VERSION ""

NS_ :

BS_:

BU_: BDCF THU FP IP RRS PLG BDCR FIS EPS ARHUD ETC EMS EPBI LAS WLCM ESCL HU APA ACC LCDAL LCDAR BMT AMP SRS TCU ATB AWD ESL ACM ECM PCU BMS IBCU OTA

BO_ 1476 BDCF_5C4: 8 BDCF
 SG_ Digital_certificate_response : 7|64@0+ (1,0) [0|1] ""  THU

BO_ 1494 BDCF_5D6: 8 BDCF
 SG_ Digital_certificate_request : 7|64@0+ (1,0) [0|1] ""  THU

BO_ 1320 BDCF_528: 8 BDCF
 SG_ group_number : 7|8@0+ (1,0) [0|1] ""  THU,IP,FIS
 SG_ RemoteParking_payment_activation_status : 15|2@0+ (1,0) [0|3] ""  THU,IP
 SG_ controller_number : 39|8@0+ (1,0) [0|255] "" Vector__XXX

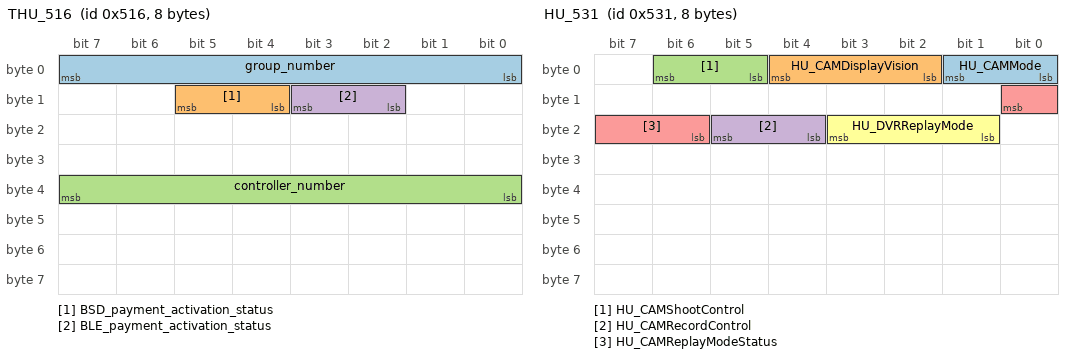
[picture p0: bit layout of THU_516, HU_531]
BO_ 1302 THU_516: 8 THU
 SG_ group_number : 7|8@0+ (1,0) [0|255] ""  BDCF,IP
 SG_ BSD_payment_activation_status : 13|2@0+ (1,0) [0|3] ""  BDCF,IP
 SG_ controller_number : 39|8@0+ (1,0) [0|255] ""  BDCF
 SG_ BLE_payment_activation_status : 11|2@0+ (1,0) [0|3] ""  BDCF

BO_ 1383 BDCF_567: 8 BDCF
 SG_ group_number : 7|8@0+ (1,0) [0|255] ""  THU
 SG_ BSD_payment_activation : 10|1@0+ (1,0) [0|1] ""  THU
 SG_ RemoteParking_payment_activation : 11|1@0+ (1,0) [0|1] ""  THU
 SG_ FV : 39|8@0+ (1,0) [0|255] ""  THU
 SG_ MAC : 47|24@0+ (1,0) [0|16777215] ""  THU
 SG_ BLE_payment_activation : 9|1@0+ (1,0) [0|1] ""  THU

BO_ 1329 HU_531: 8 THU
 SG_ HU_CAMMode : 1|2@0+ (1,0) [0|1] ""  BDCF
 SG_ HU_CAMDisplayVision : 4|3@0+ (1,0) [0|7] ""  BDCF
 SG_ HU_CAMShootControl : 6|2@0+ (1,0) [0|3] ""  BDCF
 SG_ HU_CAMRecordControl : 21|2@0+ (1,0) [0|3] ""  BDCF
 SG_ HU_CAMReplayModeStatus : 8|3@0+ (1,0) [0|7] ""  BDCF
 SG_ HU_DVRReplayMode : 19|3@0+ (1,0) [0|7] ""  BDCF

BO_ 1034 BDCR_40A: 8 BDCR
 SG_ BDCR_NMDestinationAddress : 7|8@0+ (1,0) [0|255] ""  BDCF,THU,HU,IP,FIS,BMT,PLG
 SG_ BDCR_NMAlive : 8|1@0+ (1,0) [0|1] ""  BDCF,THU,HU,IP,FIS,BMT,PLG
 SG_ BDCR_NMRing : 9|1@0+ (1,0) [0|1] ""  BDCF,THU,HU,IP,FIS,BMT,PLG
 SG_ BDCR_NMLimphome : 10|1@0+ (1,0) [0|1] ""  BDCF,THU,HU,IP,FIS,BMT,PLG
 SG_ BDCR_NMSleepIndication : 12|1@0+ (1,0) [0|1] ""  BDCF,THU,HU,IP,FIS,BMT,PLG
 SG_ BDCR_NMSleepAcknowledge : 13|1@0+ (1,0) [0|1] ""  BDCF,THU,HU,IP,FIS,BMT,PLG
 SG_ BDCR_PowerDistributionStatus : 16|1@0+ (1,0) [0|1] ""  BDCF,THU,HU,IP,FIS,BMT,PLG
 SG_ BDCR_BusMessageWakeUp : 17|1@0+ (1,0) [0|1] ""  BDCF,THU,HU,IP,FIS,BMT,PLG
 SG_ BDCR_BusMessageWakeUpMold : 20|3@0+ (1,0) [0|7] ""  BDCF,THU,HU,IP,FIS,BMT,PLG
 SG_ BDCR_PowerStatus : 21|1@0+ (1,0) [0|1] ""  BDCF,THU,HU,IP,FIS,BMT,PLG
 SG_ BDCR_CanBusStatus : 22|1@0+ (1,0) [0|1] ""  BDCF,THU,HU,IP,FIS,BMT,PLG
 SG_ BDCR_KeyRemoteOpenPTSWakeUp : 23|1@0+ (1,0) [0|1] ""  BDCF,THU,HU,IP,FIS,BMT,PLG
 SG_ BDCR_PTSSwitchWakeUp : 24|1@0+ (1,0) [0|1] ""  BDCF,THU,HU,IP,FIS,BMT,PLG
 SG_ BDCR_KickWakeUp : 25|1@0+ (1,0) [0|1] ""  BDCF,THU,HU,IP,FIS,BMT,PLG
 SG_ BDCR_KeyRemoteOpenSCMWakeUp : 26|1@0+ (1,0) [0|1] ""  BDCF,THU,HU,IP,FIS,BMT,PLG
 SG_ BDCR_SCMSwitchWakeUp : 27|1@0+ (1,0) [0|1] ""  BDCF,THU,HU,IP,FIS,BMT,PLG
 SG_ BDCR_PTSStillOver10MinStatus : 28|1@0+ (1,0) [0|1] ""  BDCF,THU,HU,IP,FIS,BMT,PLG
 SG_ BDC2_WakeUpSource : 35|4@0+ (1,0) [0|15] ""  BDCF,THU,HU,IP,FIS,BMT,PLG

BO_ 1041 THU_411: 8 THU
 SG_ HU_NMDestinationAddress : 7|8@0+ (1,0) [0|255] ""  BDCF,ARHUD
 SG_ HU_NMAlive : 8|1@0+ (1,0) [0|1] ""  BDCF,ARHUD
 SG_ HU_NMRing : 9|1@0+ (1,0) [0|1] ""  BDCF,ARHUD
 SG_ HU_NMLimphome : 10|1@0+ (1,0) [0|1] ""  BDCF,ARHUD
 SG_ HU_NMSleepIndication : 12|1@0+ (1,0) [0|1] ""  BDCF,ARHUD
 SG_ HU_NMSleepAcknowledge : 13|1@0+ (1,0) [0|1] ""  BDCF,ARHUD
 SG_ HU_PowerDistributionStatus : 16|1@0+ (1,0) [0|1] ""  BDCF,ARHUD
 SG_ HU_BusMessageWakeUp : 17|1@0+ (1,0) [0|1] ""  BDCF,ARHUD
 SG_ HU_BusMessageWakeUpMold : 20|3@0+ (1,0) [0|7] ""  BDCF,ARHUD
 SG_ HU_Chip : 21|1@0+ (1,0) [0|1] ""  BDCF,ARHUD
 SG_ HU_TBOX_ECALLRequestSwitch : 22|1@0+ (1,0) [0|1] ""  BDCF,ARHUD
 SG_ HU_TBOX_RemoteWakeup : 23|1@0+ (1,0) [0|1] ""  BDCF,ARHUD
 SG_ HU_PowerStatus : 24|1@0+ (1,0) [0|1] ""  BDCF,ARHUD
 SG_ HU_RemoteLocksignal : 25|1@0+ (1,0) [0|1] ""  BDCF,ARHUD
 SG_ HU_PowerDown10Min : 26|1@0+ (1,0) [0|1] ""  BDCF,ARHUD
 SG_ HU_CanBusStatus : 27|1@0+ (1,0) [0|1] ""  BDCF,ARHUD
 SG_ NM_Segment : 28|1@0+ (1,0) [0|1] ""  BDCF,ARHUD
 SG_ HU_G_sensorWakeup : 29|1@0+ (1,0) [0|1] ""  BDCF,ARHUD

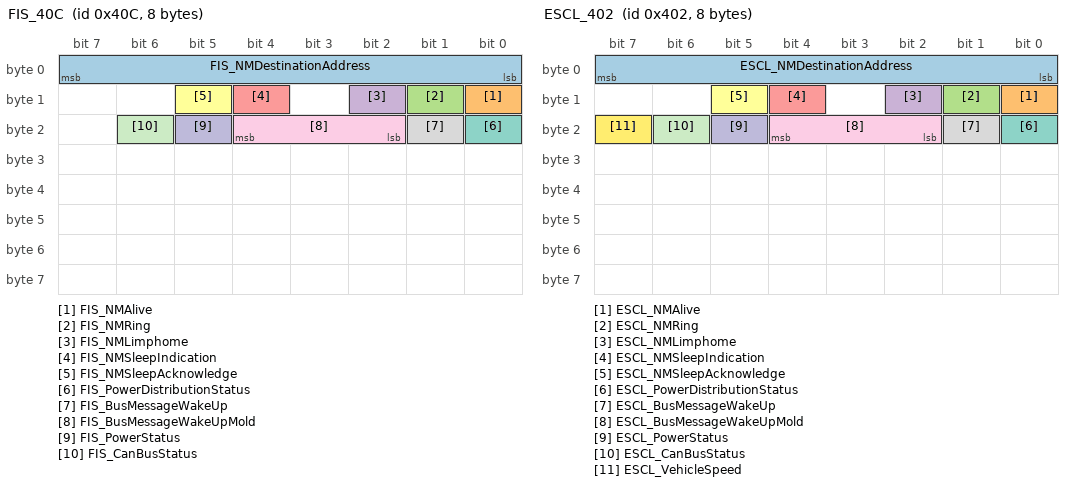
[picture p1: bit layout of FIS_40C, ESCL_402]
BO_ 1036 FIS_40C: 8 FIS
 SG_ FIS_NMDestinationAddress : 7|8@0+ (1,0) [0|255] ""  BDCF,THU,ARHUD
 SG_ FIS_NMAlive : 8|1@0+ (1,0) [0|1] ""  BDCF,THU,ARHUD
 SG_ FIS_NMRing : 9|1@0+ (1,0) [0|1] ""  BDCF,THU,ARHUD
 SG_ FIS_NMLimphome : 10|1@0+ (1,0) [0|1] ""  BDCF,THU,ARHUD
 SG_ FIS_NMSleepIndication : 12|1@0+ (1,0) [0|1] ""  BDCF,THU,ARHUD
 SG_ FIS_NMSleepAcknowledge : 13|1@0+ (1,0) [0|1] ""  BDCF,THU,ARHUD
 SG_ FIS_PowerDistributionStatus : 16|1@0+ (1,0) [0|1] ""  BDCF,THU,ARHUD
 SG_ FIS_BusMessageWakeUp : 17|1@0+ (1,0) [0|1] ""  BDCF,THU,ARHUD
 SG_ FIS_BusMessageWakeUpMold : 20|3@0+ (1,0) [0|7] ""  BDCF,THU,ARHUD
 SG_ FIS_PowerStatus : 21|1@0+ (1,0) [0|1] ""  BDCF,THU,ARHUD
 SG_ FIS_CanBusStatus : 22|1@0+ (1,0) [0|1] ""  BDCF,THU,ARHUD

BO_ 1026 ESCL_402: 8 ESCL
 SG_ ESCL_NMDestinationAddress : 7|8@0+ (1,0) [0|255] ""  BDCF,THU,ARHUD
 SG_ ESCL_NMAlive : 8|1@0+ (1,0) [0|1] ""  BDCF,THU,ARHUD
 SG_ ESCL_NMRing : 9|1@0+ (1,0) [0|1] ""  BDCF,THU,ARHUD
 SG_ ESCL_NMLimphome : 10|1@0+ (1,0) [0|1] ""  BDCF,THU,ARHUD
 SG_ ESCL_NMSleepIndication : 12|1@0+ (1,0) [0|1] ""  BDCF,THU,ARHUD
 SG_ ESCL_NMSleepAcknowledge : 13|1@0+ (1,0) [0|1] ""  BDCF,THU,ARHUD
 SG_ ESCL_PowerDistributionStatus : 16|1@0+ (1,0) [0|1] ""  BDCF,THU,ARHUD
 SG_ ESCL_BusMessageWakeUp : 17|1@0+ (1,0) [0|1] ""  BDCF,THU,ARHUD
 SG_ ESCL_BusMessageWakeUpMold : 20|3@0+ (1,0) [0|7] ""  BDCF,THU,ARHUD
 SG_ ESCL_PowerStatus : 21|1@0+ (1,0) [0|1] ""  BDCF,THU,ARHUD
 SG_ ESCL_CanBusStatus : 22|1@0+ (1,0) [0|1] ""  BDCF,THU,ARHUD
 SG_ ESCL_VehicleSpeed : 23|1@0+ (1,0) [0|1] ""  BDCF,THU,ARHUD

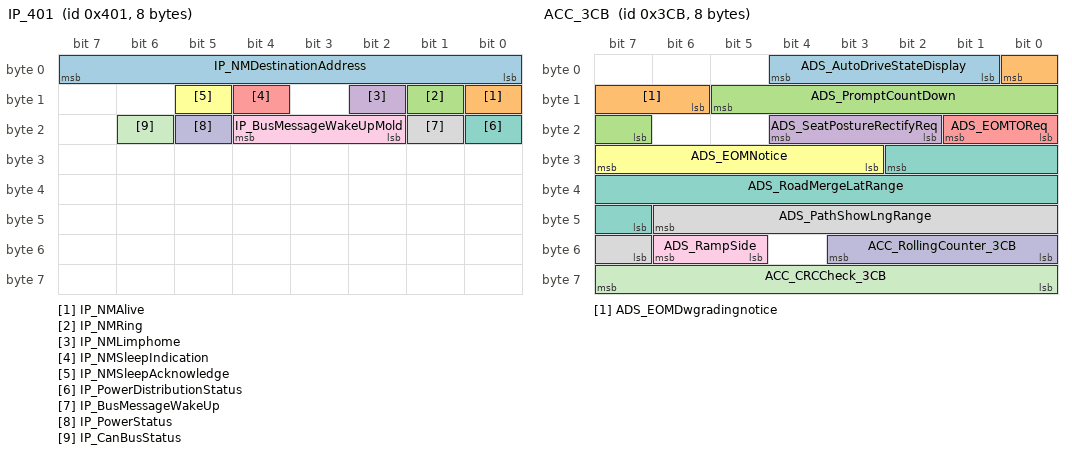
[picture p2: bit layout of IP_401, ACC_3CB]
BO_ 1025 IP_401: 8 IP
 SG_ IP_NMDestinationAddress : 7|8@0+ (1,0) [0|255] ""  BDCF,THU,ARHUD
 SG_ IP_NMAlive : 8|1@0+ (1,0) [0|1] ""  BDCF,THU,ARHUD
 SG_ IP_NMRing : 9|1@0+ (1,0) [0|1] ""  BDCF,THU,ARHUD
 SG_ IP_NMLimphome : 10|1@0+ (1,0) [0|1] ""  BDCF,THU,ARHUD
 SG_ IP_NMSleepIndication : 12|1@0+ (1,0) [0|1] ""  BDCF,THU,ARHUD
 SG_ IP_NMSleepAcknowledge : 13|1@0+ (1,0) [0|1] ""  BDCF,THU,ARHUD
 SG_ IP_PowerDistributionStatus : 16|1@0+ (1,0) [0|1] ""  BDCF,THU,ARHUD
 SG_ IP_BusMessageWakeUp : 17|1@0+ (1,0) [0|1] ""  BDCF,THU,ARHUD
 SG_ IP_BusMessageWakeUpMold : 20|3@0+ (1,0) [0|7] ""  BDCF,THU,ARHUD
 SG_ IP_PowerStatus : 21|1@0+ (1,0) [0|1] ""  BDCF,THU,ARHUD
 SG_ IP_CanBusStatus : 22|1@0+ (1,0) [0|1] ""  BDCF,THU,ARHUD

BO_ 1024 BDCF_400: 8 BDCF
 SG_ BDCF_NMDestinationAddress : 7|8@0+ (1,0) [0|255] ""  THU,ARHUD
 SG_ BDCF_NMAlive : 8|1@0+ (1,0) [0|1] ""  THU,ARHUD
 SG_ BDCF_NMRing : 9|1@0+ (1,0) [0|1] ""  THU,ARHUD
 SG_ BDCF_NMLimphome : 10|1@0+ (1,0) [0|1] ""  THU,ARHUD
 SG_ BDCF_NMSleepIndication : 12|1@0+ (1,0) [0|1] ""  THU,ARHUD
 SG_ BDCF_NMSleepAcknowledge : 13|1@0+ (1,0) [0|1] ""  THU,ARHUD
 SG_ BDCF_PowerDistributionStatus : 16|1@0+ (1,0) [0|1] ""  THU,ARHUD
 SG_ BDCF_BusMessageWakeUpMold : 20|4@0+ (1,0) [0|15] ""  THU,ARHUD
 SG_ BDCF_PositionLampSwitchWakeUp : 21|1@0+ (1,0) [0|1] ""  THU,ARHUD
 SG_ BDCF_EmergencyLightSwitchWakeUp : 22|1@0+ (1,0) [0|1] ""  THU,ARHUD
 SG_ BDCF_HoodStatusWakeUp : 23|1@0+ (1,0) [0|1] ""  THU,ARHUD
 SG_ BDCF_TrunkStatusWakeUp : 24|1@0+ (1,0) [0|1] ""  THU,ARHUD
 SG_ BDCF_RightRearDoorStatusWakeUp : 25|1@0+ (1,0) [0|1] ""  THU,ARHUD
 SG_ BDCF_LeftRearDoorStatusWakeUp : 26|1@0+ (1,0) [0|1] ""  THU,ARHUD
 SG_ BDCF_PassengerDoorStatusWakeUp : 27|1@0+ (1,0) [0|1] ""  THU,ARHUD
 SG_ BDCF_DriverDoorStatusWakeUp : 28|1@0+ (1,0) [0|1] ""  THU,ARHUD
 SG_ BDCF_CentralUnlockorLockControlS : 29|1@0+ (1,0) [0|1] ""  THU,ARHUD
 SG_ BDCF_DriverDoorUnlockorLockStatu : 30|1@0+ (1,0) [0|1] ""  THU,ARHUD
 SG_ BDCF_KeyRemoteSignalWakeUp : 34|3@0+ (1,0) [0|7] ""  THU,ARHUD
 SG_ BDCF_TrunkSwitchCommandWakeUp : 35|1@0+ (1,0) [0|1] ""  THU,ARHUD
 SG_ BDCF_Easy_openWakeUp : 36|1@0+ (1,0) [0|1] ""  THU,ARHUD
 SG_ BDCF_OverTakeLightSwitchWakeUp : 37|1@0+ (1,0) [0|1] ""  THU,ARHUD
 SG_ BDCF_StartupButtonSignalWakeUp : 38|1@0+ (1,0) [0|1] ""  THU,ARHUD
 SG_ BDCF_DoorHandleButtonSignalWakeU : 39|1@0+ (1,0) [0|1] ""  THU,ARHUD
 SG_ BDCF_BrakePedalWakeUp : 40|1@0+ (1,0) [0|1] ""  THU,ARHUD
 SG_ BDCF_GreetWakeUp : 41|1@0+ (1,0) [0|1] ""  THU,ARHUD
 SG_ BDCF_PowerStatus : 42|1@0+ (1,0) [0|1] ""  THU,ARHUD,ETC
 SG_ BDCF_PositionLampStatus : 43|1@0+ (1,0) [0|1] ""  THU,ARHUD
 SG_ BDCF_SecondAntiTheftStatus : 44|1@0+ (1,0) [0|1] ""  THU,ARHUD
 SG_ BDCF_ALLDoorStatus : 45|1@0+ (1,0) [0|1] ""  THU,ARHUD
 SG_ BDCF_DriverDoorHandleButtonStatu : 46|1@0+ (1,0) [0|1] ""  THU,ARHUD
 SG_ BDCF_TrunkButtonStatus : 47|1@0+ (1,0) [0|1] ""  THU,ARHUD
 SG_ BDCF_FollowMeHomeStatus : 48|1@0+ (1,0) [0|1] ""  THU,ARHUD
 SG_ BDCF_CanBusStatus : 49|1@0+ (1,0) [0|1] ""  THU,ARHUD
 SG_ BDCF_LinBusStatus : 50|1@0+ (1,0) [0|1] ""  THU,ARHUD
 SG_ BDCF_TurnLightSwitchStatus : 51|1@0+ (1,0) [0|1] ""  THU,ARHUD
 SG_ BDCF_UnlockPerformStatus : 52|1@0+ (1,0) [0|1] ""  THU,ARHUD
 SG_ BDCF_lockPerformStatus : 53|1@0+ (1,0) [0|1] ""  THU,ARHUD
 SG_ BDCF_PowerSaveModeStatus : 54|1@0+ (1,0) [0|1] ""  THU,ARHUD
 SG_ BDCF_BrakePedalStatus : 55|1@0+ (1,0) [0|1] ""  THU,ARHUD
 SG_ BDCF_RemoteSignalStatus : 56|1@0+ (1,0) [0|1] ""  THU,ARHUD
 SG_ BDCF_DSMLocalSwitchWakeUp : 57|1@0+ (1,0) [0|1] ""  THU,ARHUD
 SG_ BDCF_DSMSleepStatus : 58|1@0+ (1,0) [0|1] ""  THU,ARHUD

BO_ 973 ACC_3CD: 8 ACC
 SG_ ADS_DisToRamp : 7|9@0+ (1,0) [0|400] "m" BDCF,THU
 SG_ ADS_PathThroughRamp : 14|2@0+ (1,0) [0|3] "" THU
 SG_ ADS_RampStatus : 12|3@0+ (1,0) [0|3] "" THU
 SG_ ADS_TunnelStatus : 9|2@0+ (1,0) [0|3] "" THU
 SG_ ADS_TunnelDis : 23|9@0+ (1,0) [0|400] "m" THU
 SG_ ACC_RollingCounter_3CD : 51|4@0+ (1,0) [0|15] "" THU
 SG_ ACC_CRCCheck_3CD : 63|8@0+ (1,0) [0|255] "" THU

BO_ 971 ACC_3CB: 8 ACC
 SG_ ADS_AutoDriveStateDisplay : 4|4@0+ (1,0) [0|15] "" BDCF,THU
 SG_ ADS_EOMDwgradingnotice : 0|3@0+ (1,0) [0|7] "" THU
 SG_ ADS_PromptCountDown : 13|7@0+ (1,0) [0|100] "s" THU
 SG_ ADS_SeatPostureRectifyReq : 20|3@0+ (1,0) [0|7] "" THU
 SG_ ADS_EOMTOReq : 17|2@0+ (1,0) [0|3] "" THU
 SG_ ADS_EOMNotice : 31|5@0+ (1,0) [0|31] "" THU
 SG_ ADS_RoadMergeLatRange : 26|12@0+ (0.01,-16) [-16|16] "m" THU
 SG_ ADS_PathShowLngRange : 46|8@0+ (1,0) [0|200] "m" THU
 SG_ ADS_RampSide : 54|2@0+ (1,0) [0|3] "" THU
 SG_ ACC_RollingCounter_3CB : 51|4@0+ (1,0) [0|15] "" THU
 SG_ ACC_CRCCheck_3CB : 63|8@0+ (1,0) [0|255] "" THU

BO_ 970 ACC_3CA: 8 ACC
 SG_ ADS_RoadSlopeShapeC3 : 7|12@0+ (0.000000476837158203125,-0.000976085662841796875) [-0.000976085662841796875|0.000976085662841796875] "" BDCF,THU
 SG_ ADS_PathShow_C1 : 11|12@0+ (0.00048828125,-1) [-1|0.9990234375] "" THU
 SG_ ADS_PathShow_C2 : 31|12@0+ (0.0000152587890625,-0.0312347412109375) [-0.0312347412109375|0.0312347412109375] "" THU
 SG_ ADS_PathShow_C3 : 35|12@0+ (0.000000476837158203125,-0.000976085662841796875) [-0.000976085662841796875|0.000976085662841796875] "" THU
 SG_ ADS_PathShow_Status : 55|3@0+ (1,0) [0|7] "" THU
 SG_ ACC_RollingCounter_3CA : 51|4@0+ (1,0) [0|15] "" THU
 SG_ ACC_CRCCheck_3CA : 63|8@0+ (1,0) [0|255] "" THU

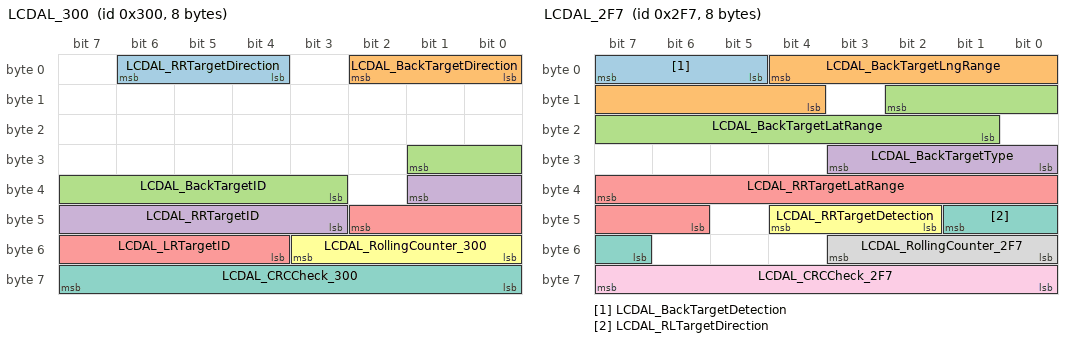
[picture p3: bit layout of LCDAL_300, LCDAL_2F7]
BO_ 768 LCDAL_300: 8 LCDAL
 SG_ LCDAL_RRTargetDirection : 6|3@0+ (1,0) [0|7] "" BDCF,THU,IP
 SG_ LCDAL_BackTargetDirection : 2|3@0+ (1,0) [0|7] "" THU,IP
 SG_ LCDAL_BackTargetID : 25|7@0+ (1,0) [0|63] "" THU,IP
 SG_ LCDAL_RRTargetID : 33|7@0+ (1,0) [0|63] "" THU,IP
 SG_ LCDAL_LRTargetID : 42|7@0+ (1,0) [0|63] "" THU,IP
 SG_ LCDAL_RollingCounter_300 : 51|4@0+ (1,0) [0|15] "" THU,IP
 SG_ LCDAL_CRCCheck_300 : 63|8@0+ (1,0) [0|255] "" THU,IP

BO_ 759 LCDAL_2F7: 8 LCDAL
 SG_ LCDAL_BackTargetDetection : 7|3@0+ (1,0) [0|7] "" BDCF,THU,IP
 SG_ LCDAL_BackTargetLngRange : 4|9@0+ (0.5,-70) [-70|180] "m" THU,IP
 SG_ LCDAL_BackTargetLatRange : 10|10@0+ (0.1,-50) [-50|50] "m" THU,IP
 SG_ LCDAL_BackTargetType : 27|4@0+ (1,0) [0|15] "" THU,IP
 SG_ LCDAL_RRTargetLatRange : 39|10@0+ (0.1,-50) [-50|50] "m" THU,IP
 SG_ LCDAL_RRTargetDetection : 44|3@0+ (1,0) [0|7] "" THU,IP
 SG_ LCDAL_RLTargetDirection : 41|3@0+ (1,0) [0|7] "" THU,IP
 SG_ LCDAL_RollingCounter_2F7 : 51|4@0+ (1,0) [0|15] "" THU,IP
 SG_ LCDAL_CRCCheck_2F7 : 63|8@0+ (1,0) [0|255] "" THU,IP

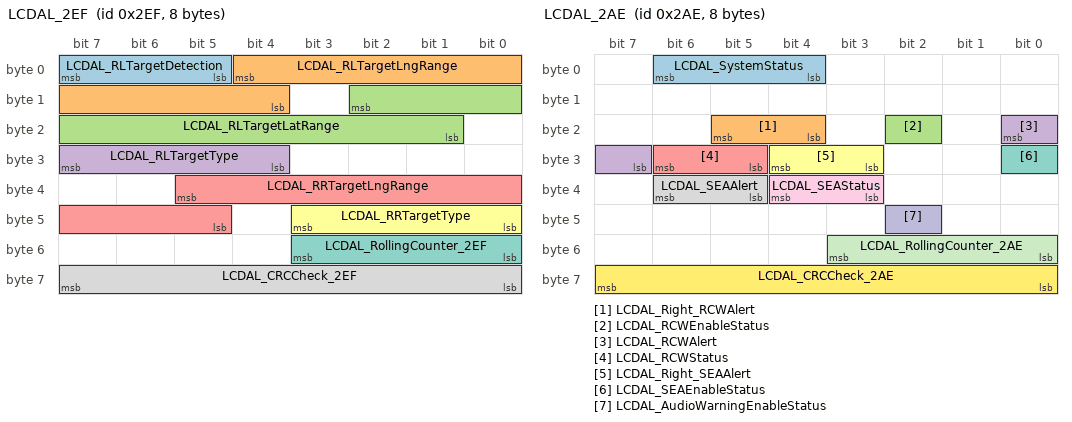
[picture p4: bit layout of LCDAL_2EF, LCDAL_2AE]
BO_ 751 LCDAL_2EF: 8 LCDAL
 SG_ LCDAL_RLTargetDetection : 7|3@0+ (1,0) [0|7] "" BDCF,THU,IP
 SG_ LCDAL_RLTargetLngRange : 4|9@0+ (0.5,-70) [-70|180] "m" THU,IP
 SG_ LCDAL_RLTargetLatRange : 10|10@0+ (0.1,-50) [-50|50] "m" THU,IP
 SG_ LCDAL_RLTargetType : 31|4@0+ (1,0) [0|15] "" THU,IP
 SG_ LCDAL_RRTargetLngRange : 37|9@0+ (0.5,-70) [-70|180] "m" THU,IP
 SG_ LCDAL_RRTargetType : 43|4@0+ (1,0) [0|15] "" THU,IP
 SG_ LCDAL_RollingCounter_2EF : 51|4@0+ (1,0) [0|15] "" THU,IP
 SG_ LCDAL_CRCCheck_2EF : 63|8@0+ (1,0) [0|255] "" THU,IP

BO_ 687 LCDAR_2AF: 8 LCDAR
SG_ LCDAR_BSD_LCAEnableStatus : 7|2@0+ (1,0) [0|3] "" THU,IP
SG_ LCDAR_Left_BSD_LCAAlert : 5|2@0+ (1,0) [0|3] "" THU,IP
SG_ LCDAR_Left_RCTAAlert : 1|2@0+ (1,0) [0|3] "" THU,IP
SG_ LCDAR_RCTAEnableStatus : 15|1@0+ (1,0) [0|1] "" THU,IP
SG_ LCDAR_SystemStatus : 12|3@0+ (1,0) [0|7] "" BDCF,THU,IP
SG_ LCDAR_BSD_LCAAlert : 9|2@0+ (1,0) [0|3] "" THU,IP
SG_ LCDAR_BSD_LCAStatus : 23|2@0+ (1,0) [0|3] "" THU,IP
SG_ LCDAR_RCTAAlert : 21|2@0+ (1,0) [0|3] "" THU,IP
SG_ LCDAR_RCTBActive : 19|1@0+ (1,0) [0|1] "" Vector__XXX
SG_ LCDAR_RCTBEnable : 18|1@0+ (1,0) [0|1] "" Vector__XXX
SG_ LCDAR_RCTBStatus : 17|2@0+ (1,0) [0|3] "" THU,IP
SG_ LCDAR_RCTAStatus : 31|2@0+ (1,0) [0|3] "" THU,IP
SG_ LCDAR_Left_ELK_oAlert : 29|2@0+ (1,0) [0|3] "" THU,IP
SG_ LCDAR_ELK_oStatus : 27|2@0+ (1,0) [0|3] "" THU,IP
SG_ LCDAR_ELK_oAlert : 25|2@0+ (1,0) [0|3] "" THU,IP
SG_ LCDAR_RCTBTargetDecel : 39|16@0+ (0.0005,-16) [-16|16] "m/s2" Vector__XXX
SG_ ADS_LCDAR_Left_LCAAlertForELK : 53|2@0+ (1,0) [0|3] "" THU,IP
SG_ LCDAR_RollingCounter_2AF : 51|4@0+ (1,0) [0|15] "" THU,IP
SG_ LCDAR_CRCCheck_2AF : 63|8@0+ (1,0) [0|255] "" THU,IP

BO_ 686 LCDAL_2AE: 8 LCDAL
SG_ LCDAL_SystemStatus : 6|3@0+ (1,0) [0|7] "" BDCF,THU,IP
SG_ LCDAL_Right_RCWAlert : 21|2@0+ (1,0) [0|3] "" THU,IP
SG_ LCDAL_RCWEnableStatus : 18|1@0+ (1,0) [0|1] "" THU,IP
SG_ LCDAL_RCWAlert : 16|2@0+ (1,0) [0|3] "" BDCF,THU,IP
SG_ LCDAL_RCWStatus : 30|2@0+ (1,0) [0|3] "" BDCF,THU,IP
SG_ LCDAL_Right_SEAAlert : 28|2@0+ (1,0) [0|3] "" THU,IP
SG_ LCDAL_SEAEnableStatus : 24|1@0+ (1,0) [0|1] "" BDCF,THU,IP
SG_ LCDAL_SEAAlert : 38|2@0+ (1,0) [0|3] "" BDCF,THU,IP
SG_ LCDAL_SEAStatus : 36|2@0+ (1,0) [0|3] "" THU,IP
SG_ LCDAL_AudioWarningEnableStatus : 42|1@0+ (1,0) [0|1] "" THU,IP
SG_ LCDAL_RollingCounter_2AE : 51|4@0+ (1,0) [0|15] "" THU,IP
SG_ LCDAL_CRCCheck_2AE : 63|8@0+ (1,0) [0|255] "" THU,IP

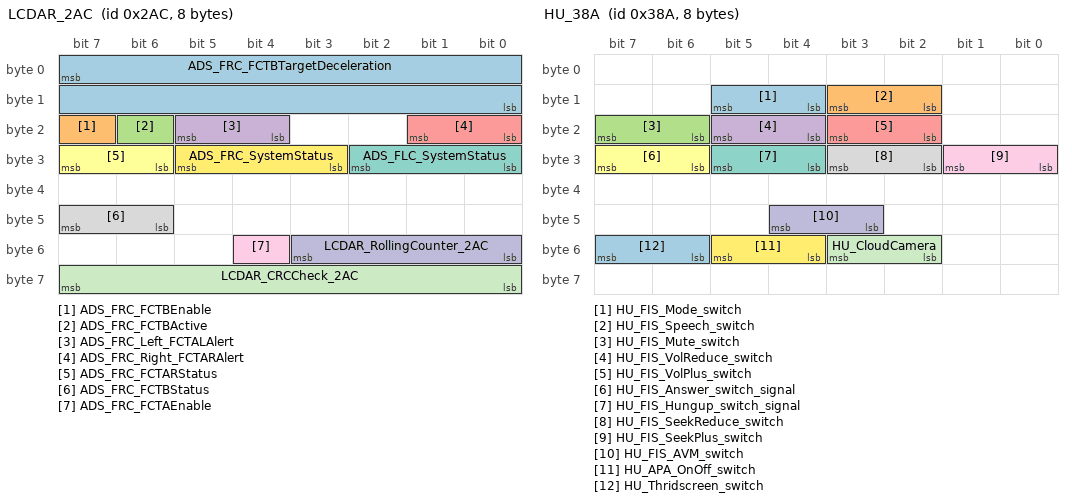
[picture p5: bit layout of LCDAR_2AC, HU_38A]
BO_ 684 LCDAR_2AC: 8 LCDAR
 SG_ ADS_FRC_FCTBTargetDeceleration : 7|16@0+ (0.0005,-16) [-16|16] "m/s2" BDCF
 SG_ ADS_FRC_FCTBEnable : 23|1@0+ (1,0) [0|1] "" THU
 SG_ ADS_FRC_FCTBActive : 22|1@0+ (1,0) [0|1] "" Vector__XXX
 SG_ ADS_FRC_Left_FCTALAlert : 21|2@0+ (1,0) [0|3] "" THU,IP
 SG_ ADS_FRC_Right_FCTARAlert : 17|2@0+ (1,0) [0|3] "" THU,IP
 SG_ ADS_FRC_FCTARStatus : 31|2@0+ (1,0) [0|3] "" IP
 SG_ ADS_FLC_SystemStatus : 26|3@0+ (1,0) [0|7] "" Vector__XXX
 SG_ ADS_FRC_FCTBStatus : 47|2@0+ (1,0) [0|3] "" IP
 SG_ ADS_FRC_FCTAEnable : 52|1@0+ (1,0) [0|1] "" THU
 SG_ LCDAR_RollingCounter_2AC : 51|4@0+ (1,0) [0|15] "" THU,IP
 SG_ LCDAR_CRCCheck_2AC : 63|8@0+ (1,0) [0|255] "" THU,IP
 SG_ ADS_FRC_SystemStatus : 29|3@0+ (1,0) [0|7] "" Vector__XXX

BO_ 1771 BDCF_6EB: 8 BDCF
 SG_ GW_InstallReqFeedback : 7|2@0+ (1,0) [0|3] "" Vector__XXX
 SG_ GW_InstallReqFeedback_PowerSts : 4|1@0+ (1,0) [0|1] "" Vector__XXX
 SG_ GW_InstallReqFeedback_BatterySts : 5|1@0+ (1,0) [0|1] "" Vector__XXX
 SG_ GW_VehicleSpeedSts : 3|1@0+ (1,0) [0|1] "" Vector__XXX
 SG_ GW_InstallReqFeedbackShiftSts : 2|1@0+ (1,0) [0|1] "" Vector__XXX
 SG_ GW_FBLhandbreakSts : 1|1@0+ (1,0) [0|1] "" Vector__XXX
 SG_ GW_FBLTempSts : 0|1@0+ (1,0) [0|1] "" Vector__XXX
 SG_ GW_FBLExceedSts : 15|1@0+ (1,0) [0|1] "" Vector__XXX
 SG_ GW_FBLVehicleChargeSts : 14|1@0+ (1,0) [0|1] "" Vector__XXX
 SG_ GW_FBLRemoteSts : 13|1@0+ (1,0) [0|1] "" Vector__XXX

BO_ 906 HU_38A: 8 THU
 SG_ HU_FIS_Mode_switch : 13|2@0+ (1,0) [0|3] ""  BDCF
 SG_ HU_FIS_Speech_switch : 11|2@0+ (1,0) [0|3] ""  BDCF
 SG_ HU_FIS_Mute_switch : 23|2@0+ (1,0) [0|3] ""  BDCF
 SG_ HU_FIS_VolReduce_switch : 21|2@0+ (1,0) [0|3] ""  BDCF
 SG_ HU_FIS_VolPlus_switch : 19|2@0+ (1,0) [0|3] ""  BDCF
 SG_ HU_FIS_Answer_switch_signal : 31|2@0+ (1,0) [0|3] ""  BDCF
 SG_ HU_FIS_Hungup_switch_signal : 29|2@0+ (1,0) [0|3] ""  BDCF
 SG_ HU_FIS_SeekReduce_switch : 27|2@0+ (1,0) [0|3] ""  BDCF
 SG_ HU_FIS_SeekPlus_switch : 25|2@0+ (1,0) [0|3] ""  BDCF
 SG_ HU_FIS_AVM_switch : 44|2@0+ (1,0) [0|3] ""  BDCF
 SG_ HU_CloudCamera : 51|2@0+ (1,0) [0|3] ""  BDCF
 SG_ HU_APA_OnOff_switch : 53|2@0+ (1,0) [0|3] ""  BDCF
 SG_ HU_Thridscreen_switch : 55|2@0+ (1,0) [0|3] ""  BDCF,IP

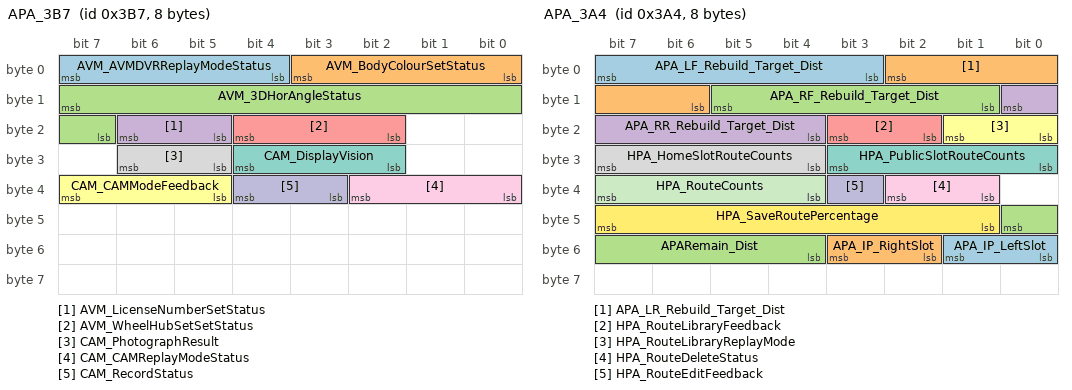
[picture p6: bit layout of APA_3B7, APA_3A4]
BO_ 951 APA_3B7: 8 APA
 SG_ AVM_AVMDVRReplayModeStatus : 7|4@0+ (1,0) [0|15] "" BDCF,THU
 SG_ AVM_BodyColourSetStatus : 3|4@0+ (1,0) [0|15] "" THU
 SG_ AVM_3DHorAngleStatus : 15|9@0+ (1,0) [0|360] "°" THU
 SG_ AVM_LicenseNumberSetStatus : 22|2@0+ (1,0) [0|3] "" THU
 SG_ AVM_WheelHubSetSetStatus : 20|3@0+ (1,0) [0|7] "" THU
 SG_ CAM_CAMModeFeedback : 39|3@0+ (1,0) [0|7] ""  THU
 SG_ CAM_DisplayVision : 28|3@0+ (1,0) [0|7] "" THU
 SG_ CAM_PhotographResult : 30|2@0+ (1,0) [0|3] "" THU
 SG_ CAM_CAMReplayModeStatus : 34|3@0+ (1,0) [0|7] "" THU
 SG_ CAM_RecordStatus : 36|2@0+ (1,0) [0|3] "" THU

BO_ 1760 APA_6E0: 8 APA
SG_ APA_AuthenticationStatus : 7|64@0+ (1,0) [0|0] "" BDCF,APA

BO_ 932 APA_3A4: 8 APA
 SG_ APA_LF_Rebuild_Target_Dist : 7|5@0+ (10,0) [0|310] "cm" BDCF,THU,IP
 SG_ APA_LR_Rebuild_Target_Dist : 2|5@0+ (10,0) [0|310] "cm" THU,IP
 SG_ APA_RF_Rebuild_Target_Dist : 13|5@0+ (10,0) [0|310] "cm" THU,IP
 SG_ APA_RR_Rebuild_Target_Dist : 8|5@0+ (10,0) [0|310] "cm" THU,IP
 SG_ HPA_RouteLibraryFeedback : 19|2@0+ (1,0) [0|3] ""  THU
 SG_ HPA_RouteLibraryReplayMode : 17|2@0+ (1,0) [0|3] ""  THU
 SG_ HPA_PublicSlotRouteCounts : 27|4@0+ (1,0) [0|15] ""  THU
 SG_ HPA_HomeSlotRouteCounts : 31|4@0+ (1,0) [0|15] ""  THU
 SG_ HPA_RouteDeleteStatus : 34|2@0+ (1,0) [0|3] ""  THU
 SG_ HPA_RouteEditFeedback : 35|1@0+ (1,0) [0|1] ""  THU
 SG_ HPA_RouteCounts : 39|4@0+ (1,0) [0|15] ""  THU
 SG_ HPA_SaveRoutePercentage : 47|7@0+ (1,0) [0|100] "%"  THU
 SG_ APA_IP_LeftSlot : 49|2@0+ (1,0) [0|3] ""  IP
 SG_ APA_IP_RightSlot : 51|2@0+ (1,0) [0|3] ""  IP
 SG_ APARemain_Dist : 40|5@0+ (0.5,0) [0|15] "m"  THU

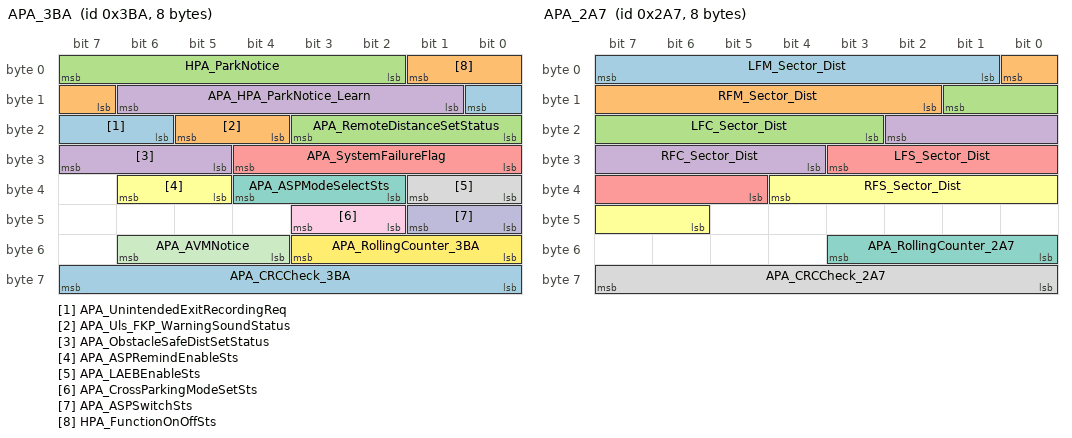
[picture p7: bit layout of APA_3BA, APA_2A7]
BO_ 954 APA_3BA: 8 APA
 SG_ APA_UnintendedExitRecordingReq : 8|3@0+ (1,0) [0|7] "" BDCF,THU
 SG_ APA_Uls_FKP_WarningSoundStatus : 21|2@0+ (1,0) [0|3] "" Vector__XXX
 SG_ APA_RemoteDistanceSetStatus : 19|4@0+ (-1,0) [0|-15] "m" THU
 SG_ APA_ObstacleSafeDistSetStatus : 31|3@0+ (-1,0) [0|-7] "cm" Vector__XXX
 SG_ APA_SystemFailureFlag : 28|5@0+ (1,0) [0|31] "" THU,IP
 SG_ APA_ASPRemindEnableSts : 38|2@0+ (1,0) [0|3] "" Vector__XXX
 SG_ APA_ASPModeSelectSts : 36|3@0+ (1,0) [0|7] "" Vector__XXX
 SG_ APA_LAEBEnableSts : 33|2@0+ (1,0) [0|3] "" Vector__XXX
 SG_ APA_CrossParkingModeSetSts : 43|2@0+ (1,0) [0|3] "" Vector__XXX
 SG_ APA_ASPSwitchSts : 41|2@0+ (1,0) [0|3] "" Vector__XXX
 SG_ APA_AVMNotice : 54|3@0+ (1,0) [0|7] "" Vector__XXX
 SG_ APA_RollingCounter_3BA : 51|4@0+ (1,0) [0|15] "" Vector__XXX
 SG_ APA_CRCCheck_3BA : 63|8@0+ (1,0) [0|255] "" Vector__XXX
 SG_ HPA_FunctionOnOffSts : 1|3@0+ (1,0) [0|7] ""  THU
 SG_ HPA_ParkNotice : 7|6@0+ (1,0) [0|63] ""  THU
 SG_ APA_HPA_ParkNotice_Learn : 14|6@0+ (1,0) [0|63] ""  THU

BO_ 679 APA_2A7: 8 APA
 SG_ LFM_Sector_Dist : 7|7@0+ (1,0) [0|127] "cm" BDCF,THU,IP
 SG_ RFM_Sector_Dist : 0|7@0+ (1,0) [0|127] "cm" THU,IP
 SG_ LFC_Sector_Dist : 9|7@0+ (1,0) [0|127] "cm" THU,IP
 SG_ RFC_Sector_Dist : 18|7@0+ (1,0) [0|127] "cm" THU,IP
 SG_ LFS_Sector_Dist : 27|7@0+ (1,0) [0|127] "cm" THU,IP
 SG_ RFS_Sector_Dist : 36|7@0+ (1,0) [0|127] "cm" THU,IP
 SG_ APA_RollingCounter_2A7 : 51|4@0+ (1,0) [0|15] "" THU,IP
 SG_ APA_CRCCheck_2A7 : 63|8@0+ (1,0) [0|255] "" THU,IP

BO_ 1295 APA_50F: 8 APA
 SG_ APA_Coordinate_Angle : 39|9@0+ (1,-180) [-180|180] "degree" BDCF
 SG_ APA_Coordinate_Y : 46|12@0+ (1,-1500) [-1500|500] "cm" THU
 SG_ APA_Coordinate_X : 50|11@0+ (1,-500) [-500|500] "cm" THU

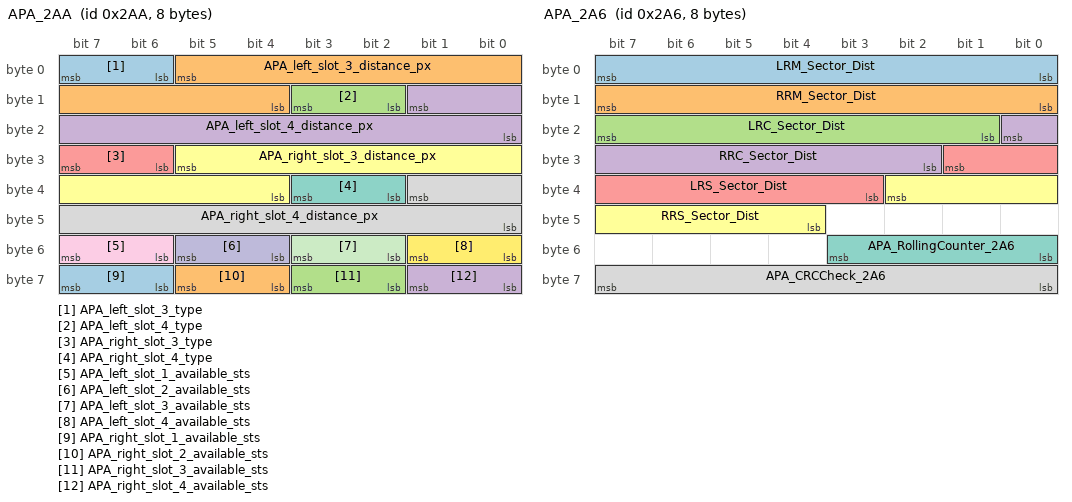
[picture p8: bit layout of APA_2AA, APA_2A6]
BO_ 682 APA_2AA: 8 APA
 SG_ APA_left_slot_3_type : 7|2@0+ (1,0) [0|3] "" BDCF,THU
 SG_ APA_left_slot_3_distance_px : 5|10@0+ (1,0) [0|1023] "" THU
 SG_ APA_left_slot_4_type : 11|2@0+ (1,0) [0|3] "" THU
 SG_ APA_left_slot_4_distance_px : 9|10@0+ (1,0) [0|1023] "" THU
 SG_ APA_right_slot_3_type : 31|2@0+ (1,0) [0|3] "" THU
 SG_ APA_right_slot_3_distance_px : 29|10@0+ (1,0) [0|1023] "" THU
 SG_ APA_right_slot_4_type : 35|2@0+ (1,0) [0|3] "" THU
 SG_ APA_right_slot_4_distance_px : 33|10@0+ (1,0) [0|1023] "" THU
 SG_ APA_left_slot_1_available_sts : 55|2@0+ (1,0) [0|3] "" THU
 SG_ APA_left_slot_2_available_sts : 53|2@0+ (1,0) [0|3] "" THU
 SG_ APA_left_slot_3_available_sts : 51|2@0+ (1,0) [0|3] "" THU
 SG_ APA_left_slot_4_available_sts : 49|2@0+ (1,0) [0|3] "" THU
 SG_ APA_right_slot_1_available_sts : 63|2@0+ (1,0) [0|3] "" THU
 SG_ APA_right_slot_2_available_sts : 61|2@0+ (1,0) [0|3] "" THU
 SG_ APA_right_slot_3_available_sts : 59|2@0+ (1,0) [0|3] "" THU
 SG_ APA_right_slot_4_available_sts : 57|2@0+ (1,0) [0|3] "" THU

BO_ 678 APA_2A6: 8 APA
 SG_ LRM_Sector_Dist : 7|8@0+ (1,0) [0|255] "cm" BDCF,THU,IP
 SG_ RRM_Sector_Dist : 15|8@0+ (1,0) [0|255] "cm" THU,IP
 SG_ LRC_Sector_Dist : 23|7@0+ (1,0) [0|127] "cm" THU,IP
 SG_ RRC_Sector_Dist : 16|7@0+ (1,0) [0|127] "cm" THU,IP
 SG_ LRS_Sector_Dist : 25|7@0+ (1,0) [0|127] "cm" THU,IP
 SG_ RRS_Sector_Dist : 34|7@0+ (1,0) [0|127] "cm" THU,IP
 SG_ APA_RollingCounter_2A6 : 51|4@0+ (1,0) [0|15] "" THU,IP
 SG_ APA_CRCCheck_2A6 : 63|8@0+ (1,0) [0|255] "" THU,IP

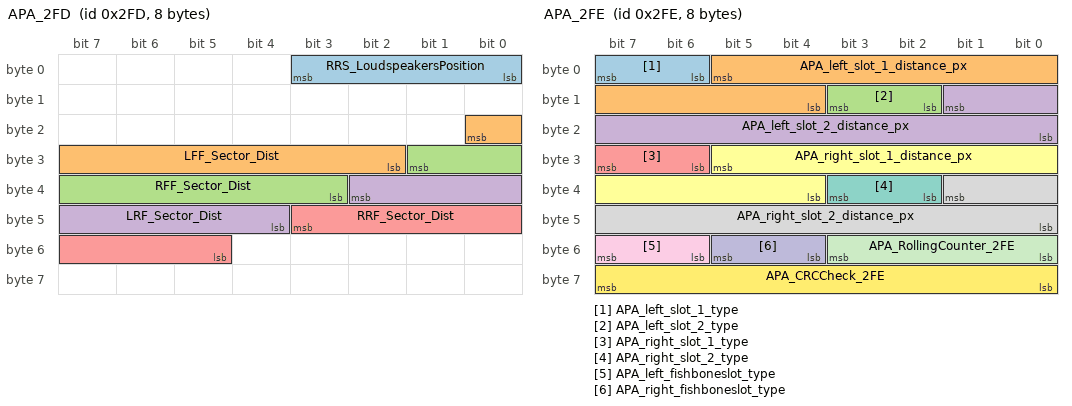
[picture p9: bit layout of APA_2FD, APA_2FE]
BO_ 765 APA_2FD: 8 APA
 SG_ RRS_LoudspeakersPosition : 3|4@0+ (1,0) [0|15] "" BDCF,THU,IP
 SG_ LFF_Sector_Dist : 16|7@0+ (1,0) [0|127] "cm" THU,IP
 SG_ RFF_Sector_Dist : 25|7@0+ (1,0) [0|127] "cm" THU,IP
 SG_ LRF_Sector_Dist : 34|7@0+ (1,0) [0|127] "cm" THU,IP
 SG_ RRF_Sector_Dist : 43|7@0+ (1,0) [0|127] "cm" THU,IP

BO_ 767 APA_2FF: 8 APA
 SG_ RRS_RRMDistance : 7|4@0+ (1,0) [0|15] "" BDCF,THU,IP
 SG_ RRS_LRMDistance : 3|4@0+ (1,0) [0|15] "" THU,IP
 SG_ RRS_RRCDistance : 15|4@0+ (1,0) [0|15] "" THU,IP
 SG_ RRS_LRCDistance : 11|4@0+ (1,0) [0|15] "" THU,IP
 SG_ RRS_RFCDistance : 23|4@0+ (1,0) [0|15] "" THU,IP
 SG_ RRS_LFCDistance : 19|4@0+ (1,0) [0|15] "" THU,IP
 SG_ RRS_LFMDistance : 31|4@0+ (1,0) [0|15] "" THU,IP
 SG_ RRS_RFMDistance : 27|4@0+ (1,0) [0|15] "" THU,IP
 SG_ RRS_SideZoneStatus_Front : 39|2@0+ (1,0) [0|3] "" THU,IP
 SG_ RRS_RRSDistance : 37|3@0+ (1,0) [0|7] "" THU,IP
 SG_ RRS_MODE : 34|3@0+ (1,0) [0|7] "" THU,IP
 SG_ RRS_WarningType : 47|4@0+ (1,0) [0|15] "" THU,IP
 SG_ RRS_SideZoneStatus_Rear : 43|2@0+ (1,0) [0|3] "" THU,IP
 SG_ RRS_WarningFrequency : 41|2@0+ (1,0) [0|3] "" THU,IP
 SG_ RRS_LRSDistance : 55|3@0+ (1,0) [0|7] "" THU,IP
 SG_ RRS_RFSDistance : 52|3@0+ (1,0) [0|7] "" THU,IP
 SG_ RRS_ButtonPress : 49|1@0+ (1,0) [0|1] "" THU,IP
 SG_ RRS_SystemFailureFlag : 48|2@0+ (1,0) [0|3] "" THU,IP
 SG_ RRS_FrontRadarActiveStatus : 62|2@0+ (1,0) [0|3] "" THU,IP
 SG_ RRS_SwitchIndicatorError : 60|1@0+ (1,0) [0|1] "" THU,IP
 SG_ RRS_LFSDistance : 58|3@0+ (1,0) [0|7] "" THU,IP

BO_ 766 APA_2FE: 8 APA
 SG_ APA_left_slot_1_type : 7|2@0+ (1,0) [0|3] "" BDCF
 SG_ APA_left_slot_1_distance_px : 5|10@0+ (1,0) [0|1023] "px" Vector__XXX
 SG_ APA_left_slot_2_type : 11|2@0+ (1,0) [0|3] "" Vector__XXX
 SG_ APA_left_slot_2_distance_px : 9|10@0+ (1,0) [0|1023] "px" Vector__XXX
 SG_ APA_right_slot_1_type : 31|2@0+ (1,0) [0|3] "" Vector__XXX
 SG_ APA_right_slot_1_distance_px : 29|10@0+ (1,0) [0|1023] "px" Vector__XXX
 SG_ APA_right_slot_2_type : 35|2@0+ (1,0) [0|3] "" Vector__XXX
 SG_ APA_right_slot_2_distance_px : 33|10@0+ (1,0) [0|1023] "px" Vector__XXX
 SG_ APA_left_fishboneslot_type : 55|2@0+ (1,0) [0|3] "" THU
 SG_ APA_right_fishboneslot_type : 53|2@0+ (1,0) [0|3] "" THU
 SG_ APA_RollingCounter_2FE : 51|4@0+ (1,0) [0|15] "" Vector__XXX
 SG_ APA_CRCCheck_2FE : 63|8@0+ (1,0) [0|255] "" Vector__XXX

BO_ 620 APA_26C: 8 APA
 SG_ APA_TransPRNDShiftReqValid : 7|1@0+ (1,0) [0|1] "" BDCF
 SG_ APA_TransPRNDShiftRequest : 6|3@0+ (1,0) [0|7] "" Vector__XXX
 SG_ APA_TargetAccelerationValid : 3|1@0+ (1,0) [0|1] "" Vector__XXX
 SG_ APA_EPBrequestValid : 2|1@0+ (1,0) [0|1] "" Vector__XXX
 SG_ APA_EPBrequest : 1|2@0+ (1,0) [0|3] "" Vector__XXX
 SG_ APA_TargetAcceleration : 15|8@0+ (0.05,-5) [-5|7.75] "m/s2" Vector__XXX
 SG_ APA_EngTorqReq : 23|10@0+ (0.097847,0) [0|99.999634] "%" Vector__XXX
 SG_ APA_EngineTrqReqEnable : 29|1@0+ (1,0) [0|1] "" Vector__XXX
 SG_ APA_HSAHDforbidden : 28|1@0+ (1,0) [0|1] "" Vector__XXX
 SG_ APA_LSCAction : 27|1@0+ (1,0) [0|1] "" THU
 SG_ APA_TransPRNDShiftEnable : 26|1@0+ (1,0) [0|1] "" Vector__XXX
 SG_ APA_Activation_Status : 25|3@0+ (1,0) [0|7] "" THU,IP
 SG_ APA_ESPDecompressionModel : 34|1@0+ (1,0) [0|1] "" Vector__XXX
 SG_ APA_AccPedShieldReq : 33|1@0+ (1,0) [0|1] "" Vector__XXX
 SG_ APA_TrqHoldForTCUCl : 47|1@0+ (1,0) [0|1] "" Vector__XXX
 SG_ APA_TCUClutchCombinationReq : 46|1@0+ (1,0) [0|1] "" Vector__XXX
 SG_ APA_SlotNotice : 45|4@0+ (1,0) [0|15] "" THU,IP
 SG_ APA_DynamicSlotWarning : 41|1@0+ (1,0) [0|1] "" THU,IP
 SG_ APA_PrefillReq : 40|1@0+ (1,0) [0|1] "" Vector__XXX
 SG_ APA_RollingCounter_26C : 51|4@0+ (1,0) [0|15] "" Vector__XXX
 SG_ APA_CRCCheck_26C : 63|8@0+ (1,0) [0|255] "" Vector__XXX

BO_ 621 APA_26D: 8 BDCF
 SG_ APA_TransPRNDShiftReqValid : 7|1@0+ (1,0) [0|1] "" APA
 SG_ APA_TransPRNDShiftRequest : 6|3@0+ (1,0) [0|7] "" Vector__XXX
 SG_ APA_TargetAccelerationValid : 3|1@0+ (1,0) [0|1] "" Vector__XXX
 SG_ APA_EPBrequestValid : 2|1@0+ (1,0) [0|1] "" Vector__XXX
 SG_ APA_EPBrequest : 1|2@0+ (1,0) [0|3] "" Vector__XXX
 SG_ APA_TargetAcceleration : 15|8@0+ (0.05,-5) [-5|7.75] "m/s2" Vector__XXX
 SG_ APA_EngTorqReq : 23|10@0+ (0.097847,0) [0|99.999634] "%" Vector__XXX
 SG_ APA_EngineTrqReqEnable : 29|1@0+ (1,0) [0|1] "" Vector__XXX
 SG_ APA_HSAHDforbidden : 28|1@0+ (1,0) [0|1] "" Vector__XXX
 SG_ APA_LSCAction : 27|1@0+ (1,0) [0|1] "" THU
 SG_ APA_TransPRNDShiftEnable : 26|1@0+ (1,0) [0|1] "" Vector__XXX
 SG_ APA_Activation_Status : 25|3@0+ (1,0) [0|7] "" THU,IP
 SG_ APA_ESPDecompressionModel : 34|1@0+ (1,0) [0|1] "" Vector__XXX
 SG_ APA_AccPedShieldReq : 33|1@0+ (1,0) [0|1] "" Vector__XXX
 SG_ APA_TrqHoldForTCUCl : 47|1@0+ (1,0) [0|1] "" Vector__XXX
 SG_ APA_TCUClutchCombinationReq : 46|1@0+ (1,0) [0|1] "" Vector__XXX
 SG_ APA_SlotNotice : 45|4@0+ (1,0) [0|15] "" THU,IP
 SG_ APA_DynamicSlotWarning : 41|1@0+ (1,0) [0|1] "" THU,IP
 SG_ APA_PrefillReq : 40|1@0+ (1,0) [0|1] "" Vector__XXX
 SG_ APA_RollingCounter_26D : 51|4@0+ (1,0) [0|15] "" Vector__XXX
 SG_ APA_CRCCheck_26D : 63|8@0+ (1,0) [0|255] "" Vector__XXX

BO_ 724 APA_2D4: 8 APA
SG_ APA_LAEBReq : 7|1@0+ (1,0) [0|1] "" BDCF
SG_ APA_ParkNotice_5 : 6|7@0+ (1,0) [0|127] "" THU,IP
SG_ APA_BLEConnectionRemind : 15|1@0+ (1,0) [0|1] "" Vector__XXX
SG_ APA_LAEBStatus : 14|3@0+ (1,0) [0|7] "" Vector__XXX
SG_ APA_FunctionOnOffSts : 11|4@0+ (1,0) [0|15] "" THU,IP
SG_ APA_CrossModeSelectReq : 23|1@0+ (1,0) [0|1] "" Vector__XXX
SG_ APA_ASPStatus : 22|2@0+ (1,0) [0|3] "" Vector__XXX
SG_ APA_ASPAvailableStatus : 20|1@0+ (1,0) [0|1] "" Vector__XXX
SG_ APA_RemoteParkingUsingRemind : 19|1@0+ (1,0) [0|1] "" Vector__XXX
SG_ APA_LAEBNotice : 18|3@0+ (1,0) [0|7] "" THU,IP
SG_ APA_NumberofParkingSlot : 31|4@0+ (1,0) [0|15] "" THU
SG_ APA_ParkingModeAvailableSts : 27|2@0+ (1,0) [0|3] "" THU
SG_ APA_PowerMirrorFoldReq : 25|2@0+ (1,0) [0|3] "" Vector__XXX
SG_ APA_PEPS_EngineOffLockRequest : 37|1@0+ (1,0) [0|1] "" Vector__XXX
SG_ APA_ReleasePressureReq : 36|1@0+ (1,0) [0|1] "" Vector__XXX
SG_ APA_vehicleFrontdetect : 35|2@0+ (1,0) [0|3] "" Vector__XXX
SG_ APA_BCMHornCommand : 33|2@0+ (1,0) [0|3] "" Vector__XXX
SG_ APA_RollingCounter_2D4 : 51|4@0+ (1,0) [0|15] "" Vector__XXX
SG_ APA_CRCCheck_2D4 : 63|8@0+ (1,0) [0|255] "" Vector__XXX

BO_ 725 APA_2D5: 8 BDCF
SG_ APA_LAEBReq : 7|1@0+ (1,0) [0|1] "" APA
SG_ APA_ParkNotice_5 : 6|7@0+ (1,0) [0|127] "" THU,IP
SG_ APA_BLEConnectionRemind : 15|1@0+ (1,0) [0|1] "" Vector__XXX
SG_ APA_LAEBStatus : 14|3@0+ (1,0) [0|7] "" Vector__XXX
SG_ APA_FunctionOnOffSts : 11|4@0+ (1,0) [0|15] "" THU,IP
SG_ APA_CrossModeSelectReq : 23|1@0+ (1,0) [0|1] "" Vector__XXX
SG_ APA_ASPStatus : 22|2@0+ (1,0) [0|3] "" Vector__XXX
SG_ APA_ASPAvailableStatus : 20|1@0+ (1,0) [0|1] "" Vector__XXX
SG_ APA_RemoteParkingUsingRemind : 19|1@0+ (1,0) [0|1] "" Vector__XXX
SG_ APA_LAEBNotice : 18|3@0+ (1,0) [0|7] "" THU,IP
SG_ APA_NumberofParkingSlot : 31|4@0+ (1,0) [0|15] "" THU
SG_ APA_ParkingModeAvailableSts : 27|2@0+ (1,0) [0|3] "" THU
SG_ APA_PowerMirrorFoldReq : 25|2@0+ (1,0) [0|3] "" Vector__XXX
SG_ APA_PEPS_EngineOffLockRequest : 37|1@0+ (1,0) [0|1] "" Vector__XXX
SG_ APA_ReleasePressureReq : 36|1@0+ (1,0) [0|1] "" Vector__XXX
SG_ APA_vehicleFrontdetect : 35|2@0+ (1,0) [0|3] "" Vector__XXX
SG_ APA_BCMHornCommand : 33|2@0+ (1,0) [0|3] "" Vector__XXX
SG_ APA_RollingCounter_2D5 : 51|4@0+ (1,0) [0|15] "" Vector__XXX
SG_ APA_CRCCheck_2D5 : 63|8@0+ (1,0) [0|255] "" Vector__XXX

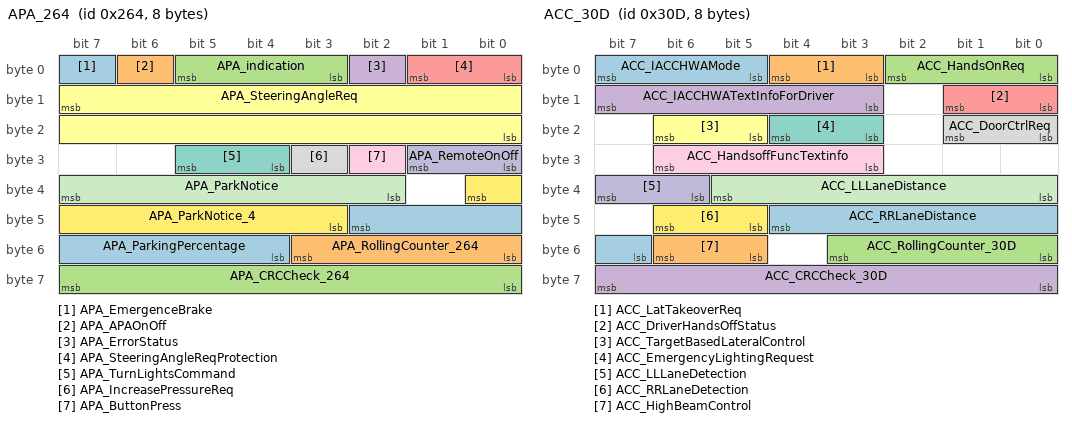
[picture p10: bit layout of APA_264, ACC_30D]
BO_ 612 APA_264: 8 APA
SG_ APA_EmergenceBrake : 7|1@0+ (1,0) [0|1] "" BDCF
SG_ APA_APAOnOff : 6|1@0+ (1,0) [0|1] "" THU
SG_ APA_indication : 5|3@0+ (1,0) [0|7] "" Vector__XXX
SG_ APA_ErrorStatus : 2|1@0+ (1,0) [0|1] "" Vector__XXX
SG_ APA_SteeringAngleReqProtection : 1|2@0+ (1,0) [0|3] "" Vector__XXX
SG_ APA_SteeringAngleReq : 15|16@0+ (0.1,0) [-780|780] "degree" Vector__XXX
SG_ APA_TurnLightsCommand : 29|2@0+ (1,0) [0|3] "" Vector__XXX
SG_ APA_IncreasePressureReq : 27|1@0+ (1,0) [0|1] "" Vector__XXX
SG_ APA_ButtonPress : 26|1@0+ (1,0) [0|1] "" THU,IP
SG_ APA_RemoteOnOff : 25|2@0+ (1,0) [0|3] "" THU,IP
SG_ APA_ParkNotice : 39|6@0+ (1,0) [0|63] "" THU,IP
SG_ APA_ParkNotice_4 : 32|6@0+ (1,0) [0|63] "" THU,IP
SG_ APA_ParkingPercentage : 42|7@0+ (1,0) [0|100] "%" Vector__XXX
SG_ APA_RollingCounter_264 : 51|4@0+ (1,0) [0|15] "" THU,IP
SG_ APA_CRCCheck_264 : 63|8@0+ (1,0) [0|255] "" THU,IP

BO_ 983 ACC_3D7: 8 ACC
 SG_ ACC_DriverWindowControl : 6|7@0+ (1,0) [0|100] "%" BDCF
 SG_ ACC_PassengerWindowControl : 14|7@0+ (1,0) [0|100] "%" Vector__XXX
 SG_ ACC_LeftRearWindowControl : 22|7@0+ (1,0) [0|100] "%" Vector__XXX
 SG_ ACC_RightRearWindowControl : 30|7@0+ (1,0) [0|100] "%" Vector__XXX
 SG_ ACC_SunroofControl : 39|8@0+ (1,0) [0|255] "" Vector__XXX
 SG_ ADS_RollingCounter_3D7 : 51|4@0+ (1,0) [0|15] "" Vector__XXX
 SG_ ADS_CRCCheck_3D7 : 63|8@0+ (1,0) [0|255] "" Vector__XXX

BO_ 861 ACC_35D: 8 ACC
 SG_ ACC_FLTarget2LatRange : 7|10@0+ (0.1,-50) [-50|50] "m" BDCF,THU,IP
 SG_ ACC_FRTarget1Detection : 12|3@0+ (1,0) [0|7] "" THU,IP
 SG_ ACC_FRTarget1LngRange : 8|9@0+ (0.5,-70) [-70|180] "m" THU,IP
 SG_ ACC_FRTarget1LatRange : 30|10@0+ (0.1,-50) [-50|50] "m" THU,IP
 SG_ ACC_FRTarget1Type : 35|4@0+ (1,0) [0|15] "" THU,IP
 SG_ ACC_FRTarget1Direction : 47|3@0+ (1,0) [0|7] "" THU,IP
 SG_ ACC_RollingCounter_35D : 51|4@0+ (1,0) [0|15] "" THU,IP
 SG_ ACC_CRCCheck_35D : 63|8@0+ (1,0) [0|255] "" THU,IP

BO_ 860 ACC_35C: 8 ACC
 SG_ ACC_FRTarget2Detection : 12|3@0+ (1,0) [0|7] "" BDCF,THU,IP
 SG_ ACC_FRTarget2LngRange : 8|9@0+ (0.5,-70) [-70|180] "m" THU,IP
 SG_ ACC_FRTarget2LatRange : 30|10@0+ (0.1,-50) [-50|50] "m" THU,IP
 SG_ ACC_FRTarget2Type : 35|4@0+ (1,0) [0|15] "" THU,IP
 SG_ ACC_FRTarget2Direction : 47|3@0+ (1,0) [0|7] "" THU,IP
 SG_ ACC_RollingCounter_35C : 51|4@0+ (1,0) [0|15] "" THU,IP
 SG_ ACC_CRCCheck_35C : 63|8@0+ (1,0) [0|255] "" THU,IP

BO_ 968 ACC_3C8: 8 ACC
 SG_ ACC_TakeoverReqAtIPFail : 7|2@0+ (1,0) [0|3] "" BDCF,THU,IP
 SG_ ADS_RemoteRoadShapeC3 : 5|12@0+ (0.000000476837158203125,-0.000976085662841796875) [-0.000976085662841796875|0.000976085662841796875] "" THU,IP
 SG_ ADS_RoadMergeFlag : 9|1@0+ (1,0) [0|1] "" THU,IP
 SG_ ADS_RoadSlopeFlag : 8|1@0+ (1,0) [0|1] "" THU,IP
 SG_ ADS_RoadMergeLngRange : 23|8@0+ (1,0) [0|200] "m" THU,IP
 SG_ ADS_RoadSlopeShapeC1 : 31|12@0+ (0.00048828125,-1) [-1|0.9990234375] "rad" THU,IP
 SG_ ADS_RoadSlopeShapeC2 : 35|12@0+ (0.0000152587890625,-0.0312347412109375) [-0.0312347412109375|0.0312347412109375] "" THU,IP
 SG_ ACC_RollingCounter_3C8 : 51|4@0+ (1,0) [0|15] "" THU,IP
 SG_ ACC_CRCCheck_3C8 : 63|8@0+ (1,0) [0|255] "" THU,IP

BO_ 781 ACC_30D: 8 ACC
 SG_ ACC_IACCHWAMode : 7|3@0+ (1,0) [0|7] "" BDCF,THU,IP
 SG_ ACC_LatTakeoverReq : 4|2@0+ (1,0) [0|3] "" THU,IP
 SG_ ACC_HandsOnReq : 2|3@0+ (1,0) [0|7] "" THU,IP
 SG_ ACC_IACCHWATextInfoForDriver : 15|5@0+ (1,0) [0|31] "" THU,IP
 SG_ ACC_DriverHandsOffStatus : 9|2@0+ (1,0) [0|3] "" THU,IP
 SG_ ACC_TargetBasedLateralControl : 22|2@0+ (1,0) [0|3] "" THU,IP
 SG_ ACC_EmergencyLightingRequest : 20|2@0+ (1,0) [0|3] "" THU,IP
 SG_ ACC_DoorCtrlReq : 17|2@0+ (1,0) [0|3] "" THU,IP
 SG_ ACC_HandsoffFuncTextinfo : 30|4@0+ (1,0) [0|15] "" IP
 SG_ ACC_LLLaneDetection : 39|2@0+ (1,0) [0|3] "" THU,IP
 SG_ ACC_LLLaneDistance : 37|6@0+ (0.2,0) [0|12] "m" THU,IP
 SG_ ACC_RRLaneDetection : 46|2@0+ (1,0) [0|3] "" THU,IP
 SG_ ACC_RRLaneDistance : 44|6@0+ (0.2,0) [0|12] "m" THU,IP
 SG_ ACC_HighBeamControl : 54|2@0+ (1,0) [0|3] "" THU,IP
 SG_ ACC_RollingCounter_30D : 51|4@0+ (1,0) [0|15] "" THU,IP
 SG_ ACC_CRCCheck_30D : 63|8@0+ (1,0) [0|255] "" THU,IP

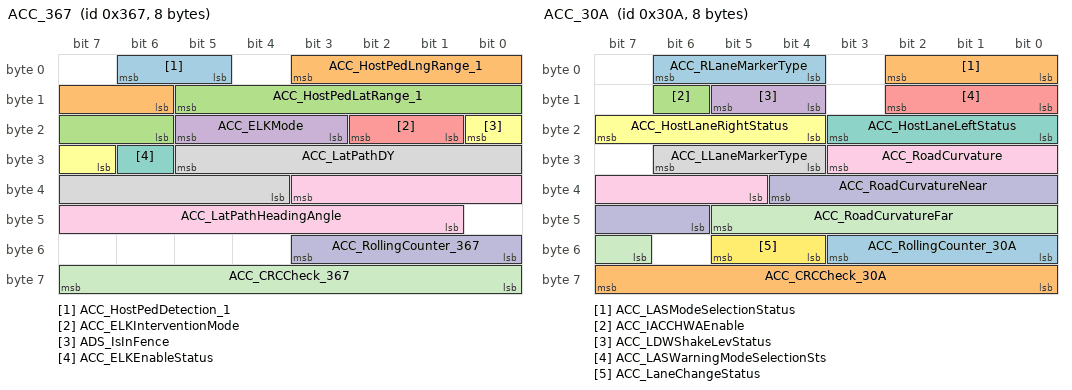
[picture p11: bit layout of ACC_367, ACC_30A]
BO_ 871 ACC_367: 8 ACC
 SG_ ACC_HostPedDetection_1 : 6|2@0+ (1,0) [0|3] "" BDCF,THU,IP
 SG_ ACC_HostPedLngRange_1 : 3|6@0+ (1,0) [0|62] "m" THU,IP
 SG_ ACC_HostPedLatRange_1 : 13|8@0+ (0.2,-25) [-25|25] "m" THU,IP
 SG_ ACC_ELKMode : 21|3@0+ (1,0) [0|7] "" THU,IP
 SG_ ACC_ELKInterventionMode : 18|2@0+ (1,0) [0|3] "" THU,IP
 SG_ ADS_IsInFence : 16|2@0+ (1,0) [0|3] "" Vector__XXX
 SG_ ACC_ELKEnableStatus : 30|1@0+ (1,0) [0|1] "" THU,IP
 SG_ ACC_LatPathDY : 29|10@0+ (0.01,0) [-5|5] "" THU,IP
 SG_ ACC_LatPathHeadingAngle : 35|11@0+ (0.1,0) [-90|90] "" Vector__XXX
 SG_ ACC_RollingCounter_367 : 51|4@0+ (1,0) [0|15] "" THU,IP
 SG_ ACC_CRCCheck_367 : 63|8@0+ (1,0) [0|255] "" THU,IP

BO_ 778 ACC_30A: 8 ACC
 SG_ ACC_RLaneMarkerType : 6|3@0+ (1,0) [0|7] "" BDCF,THU,IP
 SG_ ACC_LASModeSelectionStatus : 2|3@0+ (1,0) [0|7] "" THU,IP
 SG_ ACC_IACCHWAEnable : 14|1@0+ (1,0) [0|1] "" THU,IP
 SG_ ACC_LDWShakeLevStatus : 13|2@0+ (1,0) [0|3] "" THU,IP
 SG_ ACC_LASWarningModeSelectionSts : 10|3@0+ (1,0) [0|7] "" THU,IP
 SG_ ACC_HostLaneRightStatus : 23|4@0+ (1,0) [0|15] "" THU,IP
 SG_ ACC_HostLaneLeftStatus : 19|4@0+ (1,0) [15|15] "" THU,IP
 SG_ ACC_LLaneMarkerType : 30|3@0+ (1,0) [0|7] "" THU,IP
 SG_ ACC_RoadCurvature : 27|7@0+ (0.0005,-0.03) [-0.03|0.03] "1/m" THU,IP
 SG_ ACC_RoadCurvatureNear : 36|7@0+ (0.0005,-0.03) [-0.03|0.03] "1/m" THU,IP
 SG_ ACC_RoadCurvatureFar : 45|7@0+ (0.0005,-0.03) [-0.03|0.03] "1/m" THU,IP
 SG_ ACC_LaneChangeStatus : 53|2@0+ (1,0) [0|3] "" THU,IP
 SG_ ACC_RollingCounter_30A : 51|4@0+ (1,0) [0|15] "" THU,IP
 SG_ ACC_CRCCheck_30A : 63|8@0+ (1,0) [0|255] "" THU,IP

BO_ 877 ACC_36D: 8 ACC
 SG_ ACC_AEBTargetLngRange : 7|9@0+ (0.5,-70) [-70|180] "m" BDCF,THU,IP
 SG_ ACC_AEBTargetRelSpeed : 14|9@0+ (1,-250) [-250|250] "km/h" THU,IP
 SG_ ACC_AEBTargetLatRange : 21|10@0+ (0.1,-50) [-50|50] "m" THU,IP
 SG_ ACC_AEBStatus : 39|2@0+ (1,0) [0|3] "" THU,IP
 SG_ ACC_AEBTextInfo : 37|4@0+ (1,0) [0|15] "" THU,IP
 SG_ ACC_AEBTargetmode : 33|2@0+ (1,0) [0|3] "" THU,IP
 SG_ ACC_Voiceinfo : 47|5@0+ (1,0) [0|31] "" THU,IP
 SG_ ACC_FRadarFailureStatus : 53|2@0+ (1,0) [0|3] "" THU,IP
 SG_ ACC_RollingCounter_36D : 51|4@0+ (1,0) [0|15] "" THU,IP
 SG_ ACC_CRCCheck_36D : 63|8@0+ (1,0) [0|255] "" THU,IP

BO_ 998 ACC_3E6: 8 ACC
 SG_ ACC_LaneQuality : 6|6@0+ (0.015625,0) [0|0.984375] "" BDCF,THU,IP
 SG_ ACC_LaneEquationC1 : 9|12@0+ (0.00048828125,-1) [-1|0.9990234375] "rad" THU,IP
 SG_ ACC_LaneEquationC2 : 29|12@0+ (0.0000152587890625,-0.0312347412109375) [-0.0312347412109375|0.0312347412109375] "" THU,IP
 SG_ ACC_LaneEquationC3 : 33|12@0+ (0.000000476837158203125,-0.000976085662841797) [-0.000976085662841797|0.000976085662841797] "" THU,IP
 SG_ ACC_LaneEquationStatus : 53|2@0+ (1,0) [0|3] "" THU,IP
 SG_ ACC_RollingCounter_3E6 : 51|4@0+ (1,0) [0|15] "" THU,IP
 SG_ ACC_CRCCheck_3E6 : 63|8@0+ (1,0) [0|255] "" THU,IP

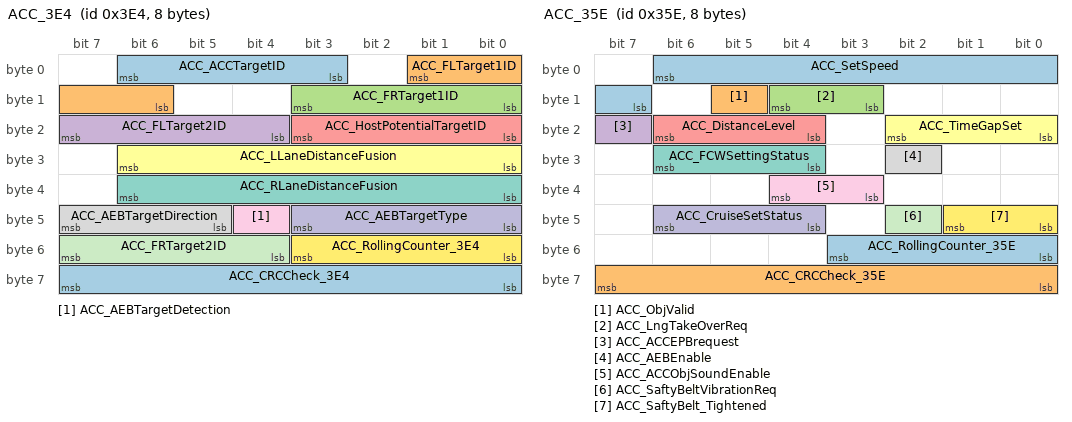
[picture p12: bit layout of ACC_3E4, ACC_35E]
BO_ 996 ACC_3E4: 8 ACC
 SG_ ACC_ACCTargetID : 6|4@0+ (1,0) [0|15] "" BDCF,THU,IP
 SG_ ACC_FLTarget1ID : 1|4@0+ (1,0) [0|15] "" THU,IP
 SG_ ACC_FRTarget1ID : 11|4@0+ (1,0) [0|15] "" THU,IP
 SG_ ACC_FLTarget2ID : 23|4@0+ (1,0) [0|15] "" THU,IP
 SG_ ACC_HostPotentialTargetID : 19|4@0+ (1,0) [0|15] "" THU,IP
 SG_ ACC_LLaneDistanceFusion : 30|7@0+ (0.05,-1) [-1|5] "m" THU,IP
 SG_ ACC_RLaneDistanceFusion : 38|7@0+ (0.05,-1) [-1|5] "m" THU,IP
 SG_ ACC_AEBTargetDirection : 47|3@0+ (1,0) [0|7] "" THU,IP
 SG_ ACC_AEBTargetDetection : 44|1@0+ (1,0) [0|1] "" THU,IP
 SG_ ACC_AEBTargetType : 43|4@0+ (1,0) [0|15] "" THU,IP
 SG_ ACC_FRTarget2ID : 55|4@0+ (1,0) [0|15] "" THU,IP
 SG_ ACC_RollingCounter_3E4 : 51|4@0+ (1,0) [0|15] "" THU,IP
 SG_ ACC_CRCCheck_3E4 : 63|8@0+ (1,0) [0|255] "" THU,IP

BO_ 863 ACC_35F: 8 ACC
 SG_ ACC_HostPotentialTargetType : 7|4@0+ (1,0) [0|15] "" BDCF,THU,IP
 SG_ ACC_HostPotentialTargetDetection : 2|3@0+ (1,0) [0|7] "" THU,IP
 SG_ ACC_HostPotentialTargetLngRange : 15|9@0+ (0.5,-70) [-70|180] "m" THU,IP
 SG_ ACC_HostPotentialTargetLatRange : 22|10@0+ (0.1,-50) [-50|50] "m" THU,IP
 SG_ ACC_HostPotentialTargetDirection : 39|3@0+ (1,0) [0|7] "" THU,IP
 SG_ ACC_CSLAEnableStatus : 53|2@0+ (1,0) [0|3] ""  THU,IP
 SG_ ACC_CSLSetReq : 35|1@0+ (1,0) [0|1] "" THU,IP
 SG_ ACC_RollingCounter_35F : 51|4@0+ (1,0) [0|15] "" THU,IP
 SG_ ACC_CRCCheck_35F : 63|8@0+ (1,0) [0|255] "" THU,IP
 SG_ ACC_VehicleStartRemindSts : 28|2@0+ (1,0) [0|3] ""  THU

BO_ 862 ACC_35E: 8 ACC
 SG_ ACC_SetSpeed : 6|8@0+ (1,0) [0|254] "Km/h" BDCF,THU,IP
 SG_ ACC_ObjValid : 13|1@0+ (1,0) [0|1] "" THU,IP
 SG_ ACC_LngTakeOverReq : 12|2@0+ (1,0) [0|3] "" THU,IP
 SG_ ACC_ACCEPBrequest : 23|1@0+ (1,0) [0|1] "" Vector__XXX
 SG_ ACC_DistanceLevel : 22|3@0+ (1,0) [0|7] "" THU,IP
 SG_ ACC_TimeGapSet : 18|3@0+ (1,0) [0|7] "" THU,IP
 SG_ ACC_FCWSettingStatus : 30|3@0+ (1,0) [0|7] "" THU,IP
 SG_ ACC_AEBEnable : 26|1@0+ (1,0) [0|1] "" THU,IP
 SG_ ACC_ACCObjSoundEnable : 36|2@0+ (1,0) [0|3] "" THU,IP
 SG_ ACC_CruiseSetStatus : 46|3@0+ (1,0) [0|7] "" THU,IP
 SG_ ACC_SaftyBeltVibrationReq : 42|1@0+ (1,0) [0|1] "" Vector__XXX
 SG_ ACC_SaftyBelt_Tightened : 41|2@0+ (1,0) [0|3] "" Vector__XXX
 SG_ ACC_RollingCounter_35E : 51|4@0+ (1,0) [0|15] "" THU,IP
 SG_ ACC_CRCCheck_35E : 63|8@0+ (1,0) [0|255] "" THU,IP

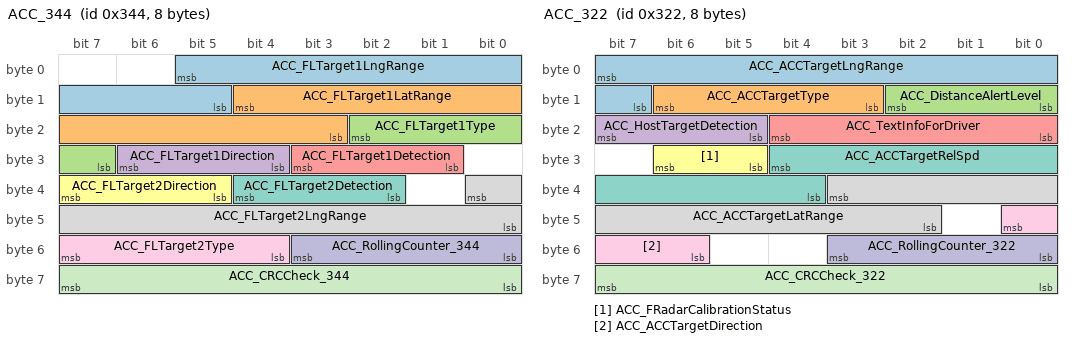
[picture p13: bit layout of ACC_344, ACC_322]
BO_ 836 ACC_344: 8 ACC
 SG_ ACC_FLTarget1LngRange : 5|9@0+ (0.5,-70) [-70|180] "m" BDCF,THU,IP
 SG_ ACC_FLTarget1LatRange : 12|10@0+ (0.1,-50) [-50|50] "m" THU,IP
 SG_ ACC_FLTarget1Type : 18|4@0+ (1,0) [0|15] "" THU,IP
 SG_ ACC_FLTarget1Direction : 30|3@0+ (1,0) [0|7] "" THU,IP
 SG_ ACC_FLTarget1Detection : 27|3@0+ (1,0) [0|7] "" THU,IP
 SG_ ACC_FLTarget2Direction : 39|3@0+ (1,0) [0|7] "" THU,IP
 SG_ ACC_FLTarget2Detection : 36|3@0+ (1,0) [0|7] "" THU,IP
 SG_ ACC_FLTarget2LngRange : 32|9@0+ (0.5,-70) [-70|180] "m" THU,IP
 SG_ ACC_FLTarget2Type : 55|4@0+ (1,0) [0|15] "" THU,IP
 SG_ ACC_RollingCounter_344 : 51|4@0+ (1,0) [0|15] "" THU,IP
 SG_ ACC_CRCCheck_344 : 63|8@0+ (1,0) [0|255] "" THU,IP

BO_ 802 ACC_322: 8 ACC
 SG_ ACC_ACCTargetLngRange : 7|9@0+ (0.5,-70) [-70|180] "m" BDCF,THU,IP
 SG_ ACC_ACCTargetType : 14|4@0+ (1,0) [0|15] "" THU,IP
 SG_ ACC_DistanceAlertLevel : 10|3@0+ (1,0) [0|7] "" THU,IP
 SG_ ACC_HostTargetDetection : 23|3@0+ (1,0) [0|7] "" THU,IP
 SG_ ACC_TextInfoForDriver : 20|5@0+ (1,0) [0|31] "" THU,IP
 SG_ ACC_FRadarCalibrationStatus : 30|2@0+ (1,0) [0|3] "" THU,IP
 SG_ ACC_ACCTargetRelSpd : 28|9@0+ (1,-250) [-250|250] "km/h" THU,IP
 SG_ ACC_ACCTargetLatRange : 35|10@0+ (0.1,-50) [-50|50] "m" THU,IP
 SG_ ACC_ACCTargetDirection : 40|3@0+ (1,0) [0|7] "" THU,IP
 SG_ ACC_RollingCounter_322 : 51|4@0+ (1,0) [0|15] "" THU,IP
 SG_ ACC_CRCCheck_322 : 63|8@0+ (1,0) [0|255] "" THU,IP

BO_ 606 ACC_25E: 8 ACC
 SG_ ACC_AEBTargetDeceleration : 7|16@0+ (0.0005,-16) [-16|16] "m/s2" BDCF
 SG_ ACC_AEBActive : 23|1@0+ (1,0) [0|1] "" THU,IP
 SG_ ACC_ABAlevel : 22|2@0+ (1,0) [0|3] "" Vector__XXX
 SG_ ACC_ABAActive : 20|1@0+ (1,0) [0|1] "" Vector__XXX
 SG_ ACC_AWBlevel : 19|4@0+ (1,0) [0|15] "" THU,IP
 SG_ ACC_AWBActive : 31|1@0+ (1,0) [0|1] "" THU,IP
 SG_ ACC_PrefillActive : 30|1@0+ (1,0) [0|1] "" Vector__XXX
 SG_ ACC_FCWActive : 29|1@0+ (1,0) [0|1] "" THU,IP
 SG_ ACC_FCWLatentWarning : 28|1@0+ (1,0) [0|1] "" THU,IP
 SG_ ACC_FCWPreWarning : 27|1@0+ (1,0) [0|1] "" THU,IP
 SG_ ACC_AEBVehilceHoldReq : 26|1@0+ (1,0) [0|1] "" Vector__XXX
 SG_ ACC_AccTrqReq : 36|10@0+ (0.097847,0) [0|99.999634] "%" Vector__XXX
 SG_ ACC_AccTrqReqActive : 42|1@0+ (1,0) [0|1] "" Vector__XXX
 SG_ ACC_AEBCtrlType : 40|4@0+ (1,0) [0|15] "" THU,IP
 SG_ ACC_FuelCutOffPrevention : 52|1@0+ (1,0) [0|1] "" Vector__XXX
 SG_ ACC_RollingCounter_25E : 51|4@0+ (1,0) [0|15] "" Vector__XXX
 SG_ ACC_CRCCheck_25E : 63|8@0+ (1,0) [0|255] "" Vector__XXX

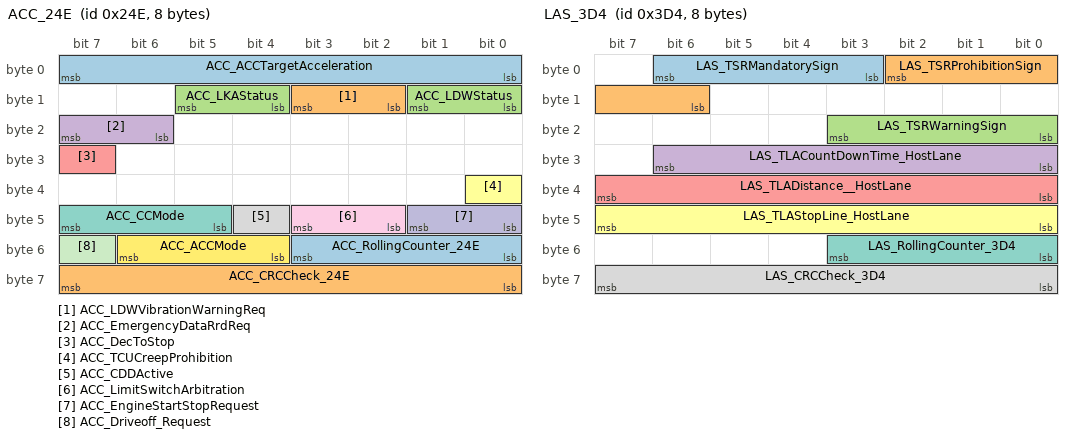
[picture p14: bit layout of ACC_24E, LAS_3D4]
BO_ 590 ACC_24E: 8 ACC
 SG_ ACC_ACCTargetAcceleration : 7|8@0+ (0.05,-5) [-5|7.75] "m/s2" BDCF
 SG_ ACC_LDWVibrationWarningReq : 11|2@0+ (1,0) [0|3] "" THU,IP
 SG_ ACC_LDWStatus : 9|2@0+ (1,0) [0|3] "" THU,IP
 SG_ ACC_EmergencyDataRrdReq : 23|2@0+ (1,0) [0|3] "" Vector__XXX
 SG_ ACC_DecToStop : 31|1@0+ (1,0) [0|1] "" Vector__XXX
 SG_ ACC_TCUCreepProhibition : 32|1@0+ (1,0) [0|1] "" Vector__XXX
 SG_ ACC_CCMode : 47|3@0+ (1,0) [0|7] "" THU,IP
 SG_ ACC_CDDActive : 44|1@0+ (1,0) [0|1] "" Vector__XXX
 SG_ ACC_LimitSwitchArbitration : 43|2@0+ (1,0) [0|3] "" Vector__XXX
 SG_ ACC_EngineStartStopRequest : 41|2@0+ (1,0) [0|3] "" Vector__XXX
 SG_ ACC_Driveoff_Request : 55|1@0+ (1,0) [0|1] "" Vector__XXX
 SG_ ACC_ACCMode : 54|3@0+ (1,0) [0|7] "" THU,IP
 SG_ ACC_RollingCounter_24E : 51|4@0+ (1,0) [0|15] "" Vector__XXX
 SG_ ACC_CRCCheck_24E : 63|8@0+ (1,0) [0|255] "" Vector__XXX
 SG_ ACC_LKAStatus : 13|2@0+ (1,0) [0|3] ""  IP

BO_ 448 ACC_1C0: 8 ACC
 SG_ ACC_MotorTorqueMaxLimitRequest : 7|11@0+ (0.02,-20.48) [-20.48|20.46] "Nm" BDCF
 SG_ ACC_MotorTorqueMinLimitRequest : 12|11@0+ (0.02,-20.48) [-20.48|20.46] "Nm" Vector__XXX
 SG_ ACC_LatAngReq : 17|14@0+ (0.1,-720) [-720|720] "degree" Vector__XXX
 SG_ ACC_LatAngReqActive : 35|1@0+ (1,0) [0|1] "" Vector__XXX
 SG_ ACC_RollingCounter_1C0 : 51|4@0+ (1,0) [0|15] "" Vector__XXX
 SG_ ACC_CRCCheck_1C0 : 63|8@0+ (1,0) [0|255] "" Vector__XXX

BO_ 980 LAS_3D4: 8 LAS
 SG_ LAS_TSRMandatorySign : 6|4@0+ (1,0) [0|15] "" BDCF,THU,IP
 SG_ LAS_TSRProhibitionSign : 2|5@0+ (1,0) [0|31] "" THU,IP
 SG_ LAS_TSRWarningSign : 19|4@0+ (1,0) [0|15] "" THU,IP
 SG_ LAS_TLACountDownTime_HostLane : 30|7@0+ (1,0) [0|127] "" THU,IP
 SG_ LAS_TLADistance__HostLane : 39|8@0+ (1,0) [0|255] "" THU,IP
 SG_ LAS_TLAStopLine_HostLane : 47|8@0+ (1,0) [0|255] "" THU,IP
 SG_ LAS_RollingCounter_3D4 : 51|4@0+ (1,0) [0|15] "" THU,IP
 SG_ LAS_CRCCheck_3D4 : 63|8@0+ (1,0) [0|255] "" THU,IP

BO_ 818 LAS_332: 8 LAS
 SG_ LAS_OverspeedVisualWarning : 5|1@0+ (1,0) [0|1] "" BDCF,THU,IP
 SG_ LAS_OverspeedSoundWarning : 2|1@0+ (1,0) [0|1] "" THU,IP
 SG_ LAS_OverspeedWarningEnableStatus : 15|1@0+ (1,0) [0|1] "" Vector__XXX
 SG_ LAS_OverspeedWarningOffset : 14|5@0+ (1,-10) [-10|10] "km/h" THU,IP
 SG_ LAS_HMALightDistribution : 8|1@0+ (1,0) [0|1] "" THU,IP
 SG_ LAS_HMAEnableStatus : 22|1@0+ (1,0) [0|1] "" Vector__XXX
 SG_ LAS_FrontCameraCalibrationStatus : 20|2@0+ (1,0) [0|3] "" THU,IP
 SG_ LAS_FrontCameraFailureStatus : 17|2@0+ (1,0) [0|3] "" THU,IP
 SG_ LAS_TSREnable : 30|1@0+ (1,0) [0|1] "" THU,IP
 SG_ LAS_OverspeedSoundWarningEnSt : 27|1@0+ (1,0) [0|1] "" THU,IP
 SG_ LAS_TSRStatus : 26|3@0+ (1,0) [0|7] "" THU,IP
 SG_ LAS_TSRHostSpdLimit : 39|8@0+ (1,0) [0|255] "" THU,IP
 SG_ LAS_HMAStatus : 44|2@0+ (1,0) [0|3] "" THU,IP
 SG_ LAS_TSRHostSpdLimitUnits : 41|2@0+ (1,0) [0|3] "" THU,IP
 SG_ LAS_TSRLeftLaneStatus : 47|3@0+ (1,0) [0|7] "" THU,IP
 SG_ LAS_TSRRightLaneStatus : 55|3@0+ (1,0) [0|7] "" THU,IP
 SG_ LAS_RollingCounter_332 : 51|4@0+ (1,0) [0|15] "" THU,IP
 SG_ LAS_CRCCheck_332 : 63|8@0+ (1,0) [0|255] "" THU,IP

BO_ 893 LAS_37D: 8 LAS
 SG_ LAS_TLAObjectStatus_HostLane : 7|2@0+ (1,0) [0|3] "" BDCF,THU,IP
 SG_ LAS_TLAEnable : 2|1@0+ (1,0) [0|1] "" THU,IP
 SG_ LAS_TLAStatus : 1|2@0+ (1,0) [0|3] "" THU,IP
 SG_ LAS_TLAWarninglevel : 5|2@0+ (1,0) [0|3] "" THU,IP
 SG_ LAS_TLAObjectColour_HostLane : 12|2@0+ (1,0) [0|3] "" THU,IP
 SG_ LAS_TLAObjectDetection_HostLane : 8|1@0+ (1,0) [0|1] "" THU,IP
 SG_ LAS_TLAArrowDirection_HostLane : 23|3@0+ (1,0) [0|7] "" THU,IP
 SG_ LAS_TLAObjectType_HostLane : 20|3@0+ (1,0) [0|7] "" THU,IP
 SG_ LAS_TLAObjectDetection_LeftLane : 31|1@0+ (1,0) [0|1] "" THU,IP
 SG_ LAS_TLAObjectColour_LeftLane : 29|2@0+ (1,0) [0|3] "" THU,IP
 SG_ LAS_TLAObjectType_LeftLane : 27|3@0+ (1,0) [0|7] "" THU,IP
 SG_ LAS_TLAArrowDirection_LeftLane : 24|3@0+ (1,0) [0|7] "" THU,IP
 SG_ LAS_TLAObjectDetection_RightLane : 35|1@0+ (1,0) [0|1] "" THU,IP
 SG_ LAS_TLAObjectColour_RightLane : 33|2@0+ (1,0) [0|3] "" THU,IP
 SG_ LAS_TLAObjectType_RightLane : 47|3@0+ (1,0) [0|7] "" THU,IP
 SG_ LAS_TLAArrowDirection_RightLane : 44|3@0+ (1,0) [0|7] "" THU,IP
 SG_ LAS_TLAObjectStatus_RightLane : 55|2@0+ (1,0) [0|3] "" THU,IP
 SG_ LAS_TLAObjectStatus_LeftLane : 53|2@0+ (1,0) [0|3] "" THU,IP
 SG_ LAS_RollingCounter_37D : 51|4@0+ (1,0) [0|15] "" THU,IP
 SG_ LAS_CRCCheck_37D : 63|8@0+ (1,0) [0|255] "" THU,IP

BO_ 960 LAS_3C0: 8 LAS
 SG_ LAS_TSRLeftLaneSpdLimit : 7|8@0+ (1,0) [0|255] "" BDCF,THU,IP
 SG_ LAS_TSRRightLaneSpdLimit : 15|8@0+ (1,0) [0|255] "" THU,IP
 SG_ LAS_RollingCounter_3C0 : 51|4@0+ (1,0) [0|15] "" THU,IP
 SG_ LAS_CRCCheck_3C0 : 63|8@0+ (1,0) [0|255] "" THU,IP

BO_ 856 ADS_358: 8 APA
 SG_ ADS_ESSMode : 7|3@0+ (1,0) [0|7] "" BDCF
 SG_ ADS_LowBeamLampOnRequest : 4|2@0+ (1,0) [0|3] "" Vector__XXX
 SG_ ADS_UDLCEnableStatus : 2|1@0+ (1,0) [0|1] "" Vector__XXX
 SG_ ADS_UDLCStatus : 1|4@0+ (1,0) [0|15] "" Vector__XXX
 SG_ ADS_UDLCLeftStatus : 13|4@0+ (1,0) [0|15] "" Vector__XXX
 SG_ ADS_LightBrightRequest : 9|3@0+ (1,0) [0|7] "" Vector__XXX
 SG_ ADS_LightFrequencyRequest : 22|3@0+ (1,0) [0|7] "" Vector__XXX
 SG_ ADS_UDLCRightStatus : 19|4@0+ (1,0) [0|15] "" Vector__XXX
 SG_ ACC_HornCommand : 31|2@0+ (1,0) [0|3] "" Vector__XXX
 SG_ ADS_ESSEnable : 29|1@0+ (1,0) [0|1] "" Vector__XXX
 SG_ ADS_UDLCTurnRightRequest : 28|1@0+ (1,0) [0|1] "" Vector__XXX
 SG_ ADS_AutoWiperShift_Rqe : 27|1@0+ (1,0) [0|1] "" Vector__XXX
 SG_ ADS_UDLCTurnLightReq : 26|3@0+ (1,0) [0|7] "" Vector__XXX
 SG_ ADS_UDLCTurnLeftRequest : 39|1@0+ (1,0) [0|1] "" Vector__XXX
 SG_ ADS_LLaneColor : 38|3@0+ (1,0) [0|7] "" Vector__XXX
 SG_ ADS_AutoHeadlightshift_Req : 35|1@0+ (1,0) [0|1] "" Vector__XXX
 SG_ ADS_RLaneColor : 34|3@0+ (1,0) [0|7] "" Vector__XXX
 SG_ ADS_LightingReq : 47|1@0+ (1,0) [0|1] "" Vector__XXX
 SG_ ADS_HighBeamLampOnRequest : 46|2@0+ (1,0) [0|3] "" Vector__XXX
 SG_ ADS_LightFlashRequest : 43|1@0+ (1,0) [0|1] "" Vector__XXX
 SG_ ADS_LightColorRequest : 42|3@0+ (1,0) [0|7] "" Vector__XXX
 SG_ ADS_UDLCTextInfoForDriver : 55|4@0+ (1,0) [0|15] "" Vector__XXX
 SG_ ADS_RollingCounter_358 : 51|4@0+ (1,0) [0|15] "" Vector__XXX
 SG_ ADS_CRCCheck_358 : 63|8@0+ (1,0) [0|255] "" Vector__XXX

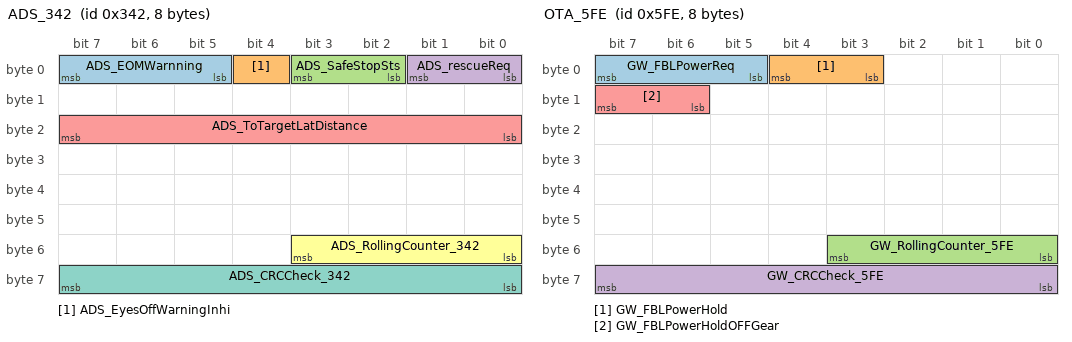
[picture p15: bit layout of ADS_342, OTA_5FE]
BO_ 834 ADS_342: 8 APA
 SG_ ADS_EOMWarnning : 7|3@0+ (1,0) [0|7] "" BDCF
 SG_ ADS_EyesOffWarningInhi : 4|1@0+ (1,0) [0|1] "" Vector__XXX
 SG_ ADS_SafeStopSts : 3|2@0+ (1,0) [0|3] "" Vector__XXX
 SG_ ADS_rescueReq : 1|2@0+ (1,0) [0|1] "" Vector__XXX
 SG_ ADS_ToTargetLatDistance : 23|8@0+ (0.1,-10) [-10|10] "m" Vector__XXX
 SG_ ADS_RollingCounter_342 : 51|4@0+ (1,0) [0|15] "" Vector__XXX
 SG_ ADS_CRCCheck_342 : 63|8@0+ (1,0) [0|255] "" Vector__XXX

 BO_ 1534 OTA_5FE: 8 OTA
SG_ GW_FBLPowerReq : 7|3@0+ (1,0) [0|7] "" THU,IP,BDCF
SG_ GW_FBLPowerHold : 4|2@0+ (1,0) [0|3] "" THU,IP
SG_ GW_RollingCounter_5FE : 51|4@0+ (1,0) [0|15] "" THU,IP
SG_ GW_CRCCheck_5FE : 63|8@0+ (1,0) [0|255] "" THU,IP
SG_ GW_FBLPowerHoldOFFGear : 15|2@0+ (1,0) [0|3] "" THU,IP

BO_ 801 OTA_321: 8 OTA
SG_ GW_OTAmode : 55|4@0+ (1,0) [0|15] "" THU,IP,RRS,ETC,APA,LAS,ACC,LCDAL,LCDAR,BDCR,BDCF
SG_ GW_OTAmode_Cntr : 20|4@0+ (1,0) [0|15] "" THU,IP,RRS,ETC,APA,LAS,ACC,LCDAL,LCDAR,BDCR
SG_ GW_OTAmode_Chks : 7|8@0+ (1,0) [0|255] "" THU,IP,RRS,ETC,APA,LAS,ACC,LCDAL,LCDAR,BDCR

BO_ 1014 BDCF_3F6: 8 BDCF
SG_ EDL_LckSts : 47|8@0+ (1,0) [0|255] "" Vector__XXX

BO_ 950 BDCF_3B6: 8 BDCF
 SG_ ATB_DriveMode : 3|4@0+ (1,0) [0|15] "" Vector__XXX
 SG_ ATB_WarningDisp : 9|2@0+ (1,0) [0|3] "" Vector__XXX
 SG_ ATB_RollingCounter_3B6 : 51|4@0+ (1,0) [0|15] "" Vector__XXX
 SG_ ATB_CRCCheck_3B6 : 63|8@0+ (1,0) [0|255] "" Vector__XXX

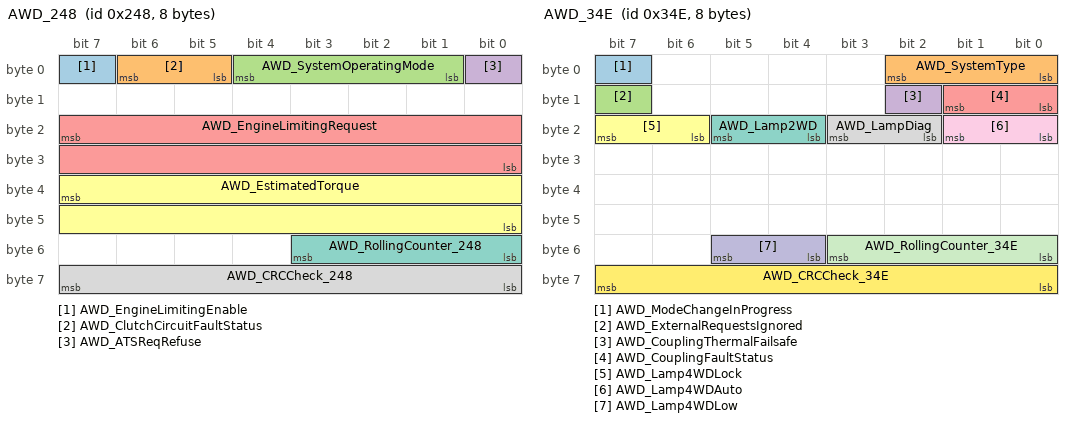
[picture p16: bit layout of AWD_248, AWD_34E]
BO_ 584 AWD_248: 8 AWD
 SG_ AWD_EngineLimitingEnable : 7|1@0+ (1,0) [0|1] "" BDCF
 SG_ AWD_ClutchCircuitFaultStatus : 6|2@0+ (1,0) [0|3] "" Vector__XXX
 SG_ AWD_SystemOperatingMode : 4|4@0+ (1,0) [0|15] "" Vector__XXX
 SG_ AWD_ATSReqRefuse : 0|1@0+ (1,0) [0|1] "" Vector__XXX
 SG_ AWD_EngineLimitingRequest : 23|16@0+ (0.001526,0) [0|99.99878] "%（单位由NM改为%，信号定义待定）" Vector__XXX
 SG_ AWD_EstimatedTorque : 39|16@0+ (0.25,0) [0|3000] "NM" Vector__XXX
 SG_ AWD_RollingCounter_248 : 51|4@0+ (1,0) [0|15] "" Vector__XXX
 SG_ AWD_CRCCheck_248 : 63|8@0+ (1,0) [0|255] "" Vector__XXX

BO_ 846 AWD_34E: 8 AWD
 SG_ AWD_ModeChangeInProgress : 7|1@0+ (1,0) [0|1] "" BDCF
 SG_ AWD_SystemType : 2|3@0+ (1,0) [0|7] "" Vector__XXX
 SG_ AWD_ExternalRequestsIgnored : 15|1@0+ (1,0) [0|1] "" Vector__XXX
 SG_ AWD_CouplingThermalFailsafe : 10|1@0+ (1,0) [0|1] "" Vector__XXX
 SG_ AWD_CouplingFaultStatus : 9|2@0+ (1,0) [0|3] "" Vector__XXX
 SG_ AWD_Lamp4WDLock : 23|2@0+ (1,0) [0|3] "" Vector__XXX
 SG_ AWD_Lamp2WD : 21|2@0+ (1,0) [0|3] "" Vector__XXX
 SG_ AWD_LampDiag : 19|2@0+ (1,0) [0|3] "" Vector__XXX
 SG_ AWD_Lamp4WDAuto : 17|2@0+ (1,0) [0|3] "" Vector__XXX
 SG_ AWD_Lamp4WDLow : 53|2@0+ (1,0) [0|3] "" Vector__XXX
 SG_ AWD_RollingCounter_34E : 51|4@0+ (1,0) [0|15] "" Vector__XXX
 SG_ AWD_CRCCheck_34E : 63|8@0+ (1,0) [0|255] "" Vector__XXX

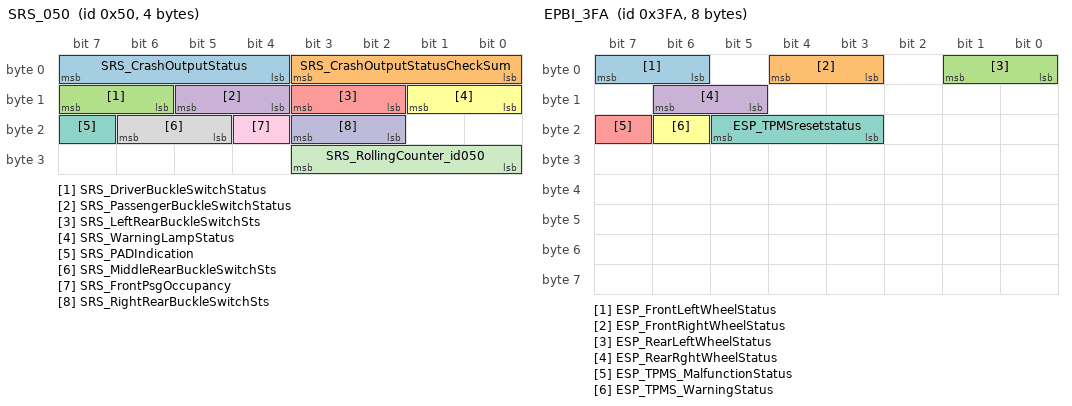
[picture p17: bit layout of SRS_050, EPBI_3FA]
BO_ 80 SRS_050: 4 SRS
SG_ SRS_CrashOutputStatus : 7|4@0+ (1,0) [0|15] "" BDCF,THU,IP
SG_ SRS_CrashOutputStatusCheckSum : 3|4@0+ (1,0) [0|15] "" IP
SG_ SRS_DriverBuckleSwitchStatus : 15|2@0+ (1,0) [0|3] "" THU,IP
SG_ SRS_PassengerBuckleSwitchStatus : 13|2@0+ (1,0) [0|3] "" THU,IP
SG_ SRS_LeftRearBuckleSwitchSts : 11|2@0+ (1,0) [0|3] "" THU,IP
SG_ SRS_WarningLampStatus : 9|2@0+ (1,0) [0|3] "" THU,IP
SG_ SRS_PADIndication : 23|1@0+ (1,0) [0|1] "" Vector__XXX
SG_ SRS_MiddleRearBuckleSwitchSts : 22|2@0+ (1,0) [0|3] "" THU,IP
SG_ SRS_FrontPsgOccupancy : 20|1@0+ (1,0) [0|1] "" THU,IP
SG_ SRS_RightRearBuckleSwitchSts : 19|2@0+ (1,0) [0|3] "" THU,IP
SG_ SRS_RollingCounter_id050 : 27|4@0+ (1,0) [0|15] "" IP

BO_ 1288 EPBI_508: 8 EPBI
 SG_ ESP_FLWheelSpdSensorFailure : 7|1@0+ (1,0) [0|1] "" BDCF
 SG_ ESP_FLWheelSpdSensor_GND : 6|1@0+ (1,0) [0|1] "" Vector__XXX
 SG_ ESP_FLWheelSpdSensor_ShtBAT : 5|1@0+ (1,0) [0|1] "" Vector__XXX
 SG_ ESP_FLWheelSpdSensor_Open : 4|1@0+ (1,0) [0|1] "" Vector__XXX
 SG_ ESP_FLWheelSpdSensorSigFailure : 3|1@0+ (1,0) [0|1] "" Vector__XXX
 SG_ ESP_FRWheelSpdSensorFailure : 2|1@0+ (1,0) [0|1] "" Vector__XXX
 SG_ ESP_FRWheelSpdSensor_GND : 1|1@0+ (1,0) [0|1] "" Vector__XXX
 SG_ ESP_FRWheelSpdSensor_ShtBAT : 0|1@0+ (1,0) [0|1] "" Vector__XXX
 SG_ ESP_FRWheelSpdSensor_Open : 15|1@0+ (1,0) [0|1] "" Vector__XXX
 SG_ ESP_FRWheelSpdSensorSigFailure : 14|1@0+ (1,0) [0|1] "" Vector__XXX
 SG_ ESP_RLWheelSpdSensorFailure : 13|1@0+ (1,0) [0|1] "" Vector__XXX
 SG_ ESP_RLWheelSpdSensor_GND : 12|1@0+ (1,0) [0|1] "" Vector__XXX
 SG_ ESP_RLWheelSpdSensor_ShtBAT : 11|1@0+ (1,0) [0|1] "" Vector__XXX
 SG_ ESP_RLWheelSpdSensor_Open : 10|1@0+ (1,0) [0|1] "" Vector__XXX
 SG_ ESP_RLWheelSpdSensorSigFailure : 9|1@0+ (1,0) [0|1] "" Vector__XXX
 SG_ ESP_RRWheelSpdSensorFailure : 8|1@0+ (1,0) [0|1] "" Vector__XXX
 SG_ ESP_RRWheelSpdSensor_GND : 21|1@0+ (1,0) [0|1] "" Vector__XXX
 SG_ ESP_RRWheelSpdSensor_ShtBAT : 20|1@0+ (1,0) [0|1] "" Vector__XXX
 SG_ ESP_RRWheelSpdSensor_Open : 19|1@0+ (1,0) [0|1] "" Vector__XXX
 SG_ ESP_RRWheelSpdSensorSigFailure : 18|1@0+ (1,0) [0|1] "" Vector__XXX
 SG_ ESP_WheelSpdSensorError : 17|1@0+ (1,0) [0|1] "" Vector__XXX
 SG_ ESP_WheelSpdSensorEcuError : 16|1@0+ (1,0) [0|1] "" Vector__XXX
 SG_ ESP_RollingCounter_508 : 51|4@0+ (1,0) [0|15] "" Vector__XXX
 SG_ ESP_CRCCheck_508 : 63|8@0+ (1,0) [0|255] "" Vector__XXX

BO_ 1018 EPBI_3FA: 8 EPBI
 SG_ ESP_FrontLeftWheelStatus : 7|2@0+ (1,0) [0|3] "" BDCF,THU,IP
 SG_ ESP_FrontRightWheelStatus : 4|2@0+ (1,0) [0|3] "" THU,IP
 SG_ ESP_RearLeftWheelStatus : 1|2@0+ (1,0) [0|3] "" THU,IP
 SG_ ESP_RearRghtWheelStatus : 14|2@0+ (1,0) [0|3] "" THU,IP
 SG_ ESP_TPMS_MalfunctionStatus : 23|1@0+ (1,0) [0|1] "" THU,IP
 SG_ ESP_TPMS_WarningStatus : 22|1@0+ (1,0) [0|1] "" THU,IP
 SG_ ESP_TPMSresetstatus : 21|3@0+ (1,0) [0|7] "" THU,IP

BO_ 847 EPBI_34F: 8 EPBI
 SG_ EPB_FailureLamp : 7|2@0+ (1,0) [0|3] "" BDCF,THU,IP
 SG_ EPB_FunctionLamp : 5|2@0+ (1,0) [0|3] "" THU,IP
 SG_ EPB_AcousticWarning : 3|2@0+ (1,0) [0|3] "" Vector__XXX
 SG_ EPB_TextDisplay : 1|4@0+ (1,0) [0|15] "" IP
 SG_ ESP_ATS_DriveModeRequest : 13|4@0+ (1,0) [0|15] "" Vector__XXX
 SG_ ESP_ATS_DriveMode_confirm : 9|4@0+ (1,0) [0|15] "" Vector__XXX
 SG_ ESP_ATSReqRefuse : 21|1@0+ (1,0) [0|1] "" Vector__XXX
 SG_ ESP_ATS_EMS_Failure : 20|1@0+ (1,0) [0|1] "" Vector__XXX
 SG_ ESP_ATS_TCU_Failure : 19|1@0+ (1,0) [0|1] "" Vector__XXX
 SG_ ESP_ATS_AWD_Failure : 18|1@0+ (1,0) [0|1] "" Vector__XXX
 SG_ ESP_ATS_EPBi_Failure : 17|1@0+ (1,0) [0|1] "" Vector__XXX
 SG_ ESP_ATS_ATB_Failure : 16|1@0+ (1,0) [0|1] "" Vector__XXX
 SG_ ESP_ATS_PtrotectMode : 31|1@0+ (1,0) [0|1] "" Vector__XXX
 SG_ ESP_HDC_StatusFeedback : 30|3@0+ (1,0) [0|7] "" THU,IP
 SG_ ESP_AVHStatusSet : 27|2@0+ (1,0) [0|3] "" THU
 SG_ AUTOHOLD_TextDisplay : 44|3@0+ (1,0) [0|7] "" IP
 SG_ HDC_TextDisplay : 41|3@0+ (1,0) [0|7] "" IP
 SG_ ESP_VGH_Status : 54|2@0+ (1,0) [0|3] "" Vector__XXX
 SG_ ESP_VGH_Available : 52|1@0+ (1,0) [0|1] "" Vector__XXX
 SG_ EPB_RollingCounter_34F : 51|4@0+ (1,0) [0|15] "" Vector__XXX
 SG_ EPB_CRCCheck_34F : 63|8@0+ (1,0) [0|255] "" Vector__XXX

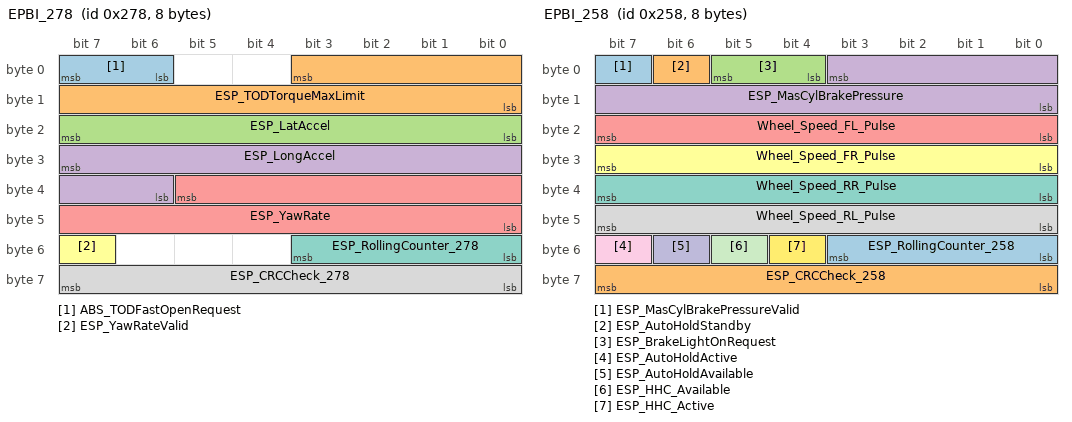
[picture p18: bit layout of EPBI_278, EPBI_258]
BO_ 632 EPBI_278: 8 EPBI
 SG_ ABS_TODFastOpenRequest : 7|2@0+ (1,0) [0|3] "" BDCF
 SG_ ESP_TODTorqueMaxLimit : 3|12@0+ (1,0) [0|4094] "NM" Vector__XXX
 SG_ ESP_LatAccel : 23|8@0+ (0.1,-12.7) [-12.7|12.7] "m/s2" THU
 SG_ ESP_LongAccel : 31|10@0+ (0.03125,-16) [-16|15.90625] "m/s2" THU
 SG_ ESP_YawRate : 37|14@0+ (0.01,-81.91) [-81.91|81.91] "degree/s" Vector__XXX
 SG_ ESP_YawRateValid : 55|1@0+ (1,0) [0|1] "" Vector__XXX
 SG_ ESP_RollingCounter_278 : 51|4@0+ (1,0) [0|15] "" Vector__XXX
 SG_ ESP_CRCCheck_278 : 63|8@0+ (1,0) [0|255] "" Vector__XXX

BO_ 631 EPBI_277: 8 EPBI
 SG_ ESP_BrakeForce : 7|1@0+ (1,0) [0|1] "" BDCF
 SG_ ESP_ABAactive : 6|1@0+ (1,0) [0|1] "" Vector__XXX
 SG_ ESP_ABAavailable : 5|1@0+ (1,0) [0|1] "" Vector__XXX
 SG_ ESP_PrefillActive : 4|1@0+ (1,0) [0|1] "" Vector__XXX
 SG_ ESP_PrefillAvailable : 3|1@0+ (1,0) [0|1] "" Vector__XXX
 SG_ ESP_AEBAvailable : 2|1@0+ (1,0) [0|1] "" Vector__XXX
 SG_ ESP_AEBdecActive : 1|1@0+ (1,0) [0|1] "" Vector__XXX
 SG_ ESP_AWBactive : 0|1@0+ (1,0) [0|1] "" Vector__XXX
 SG_ ESP_AWBavailable : 15|1@0+ (1,0) [0|1] "" Vector__XXX
 SG_ ESP_BrakeOverHeatBrakeDiscTemp : 14|1@0+ (1,0) [0|1] "" THU,IP
 SG_ ESP_CDD_Active : 13|1@0+ (1,0) [0|1] "" Vector__XXX
 SG_ ESP_CDD_Available : 12|1@0+ (1,0) [0|1] "" Vector__XXX
 SG_ ESP_VehicleStandstill : 11|1@0+ (1,0) [0|1] "" THU
 SG_ ESP_VDCActive : 10|1@0+ (1,0) [0|1] "" Vector__XXX
 SG_ ESP_TCSActive : 9|1@0+ (1,0) [0|1] "" THU,IP
 SG_ ESP_OnlyABSActive : 8|1@0+ (1,0) [0|1] "" THU,IP
 SG_ ESP_QDCACC : 23|2@0+ (1,0) [0|3] "" Vector__XXX
 SG_ ESP_CDD_Active_APA : 21|1@0+ (1,0) [0|1] "" Vector__XXX
 SG_ ESP_CDD_Available_APA : 20|1@0+ (1,0) [0|1] "" Vector__XXX
 SG_ ESP_IncreasePressureReqOK : 19|1@0+ (1,0) [0|1] "" Vector__XXX
 SG_ ESP_HDC_STATUS : 18|2@0+ (1,0) [0|3] "" THU,IP
 SG_ ESP_HBBActiveStatus : 16|1@0+ (1,0) [0|1] "" Vector__XXX
 SG_ ESP_RWU_ParkingActiveForACC : 31|1@0+ (1,0) [0|1] "" Vector__XXX
 SG_ ESP_RWU_ParkingAvailForACC : 30|1@0+ (1,0) [0|1] "" Vector__XXX
 SG_ ESP_CDP_ParkingActiveForACC : 29|1@0+ (1,0) [0|1] "" Vector__XXX
 SG_ ESP_CDP_ParkingAvailForACC : 28|1@0+ (1,0) [0|1] "" Vector__XXX
 SG_ ESP_LatAcceloffset : 39|8@0+ (0.1,-12.7) [-12.7|12.7] "m/s2" Vector__XXX
 SG_ ESP_LongAcceloffset : 47|10@0+ (0.03125,-16) [-16|15.90625] "m/s2" Vector__XXX
 SG_ ESP_HBBFunctionStatus : 53|2@0+ (1,0) [0|3] "" THU,IP
 SG_ ESP_RollingCounter_277 : 51|4@0+ (1,0) [0|15] "" THU,IP
 SG_ ESP_CRCCheck_277 : 63|8@0+ (1,0) [0|255] "" THU,IP

BO_ 600 EPBI_258: 8 EPBI
SG_ ESP_MasCylBrakePressureValid : 7|1@0+ (1,0) [0|1] "" BDCF
SG_ ESP_AutoHoldStandby : 6|1@0+ (1,0) [0|1] "" THU,IP
SG_ ESP_BrakeLightOnRequest : 5|2@0+ (1,0) [0|3] "" THU,IP
SG_ ESP_MasCylBrakePressure : 3|12@0+ (0.1,0) [0|250] "Bar" Vector__XXX
SG_ Wheel_Speed_FL_Pulse : 23|8@0+ (1,0) [0|254] "" Vector__XXX
SG_ Wheel_Speed_FR_Pulse : 31|8@0+ (1,0) [0|254] "" Vector__XXX
SG_ Wheel_Speed_RR_Pulse : 39|8@0+ (1,0) [0|254] "" Vector__XXX
SG_ Wheel_Speed_RL_Pulse : 47|8@0+ (1,0) [0|254] "" Vector__XXX
SG_ ESP_AutoHoldActive : 55|1@0+ (1,0) [0|1] "" THU,IP
SG_ ESP_AutoHoldAvailable : 54|1@0+ (1,0) [0|1] "" THU,IP
SG_ ESP_HHC_Available : 53|1@0+ (1,0) [0|1] "" THU,IP
SG_ ESP_HHC_Active : 52|1@0+ (1,0) [0|1] "" THU,IP
SG_ ESP_RollingCounter_258 : 51|4@0+ (1,0) [0|15] "" Vector__XXX
SG_ ESP_CRCCheck_258 : 63|8@0+ (1,0) [0|255] "" Vector__XXX

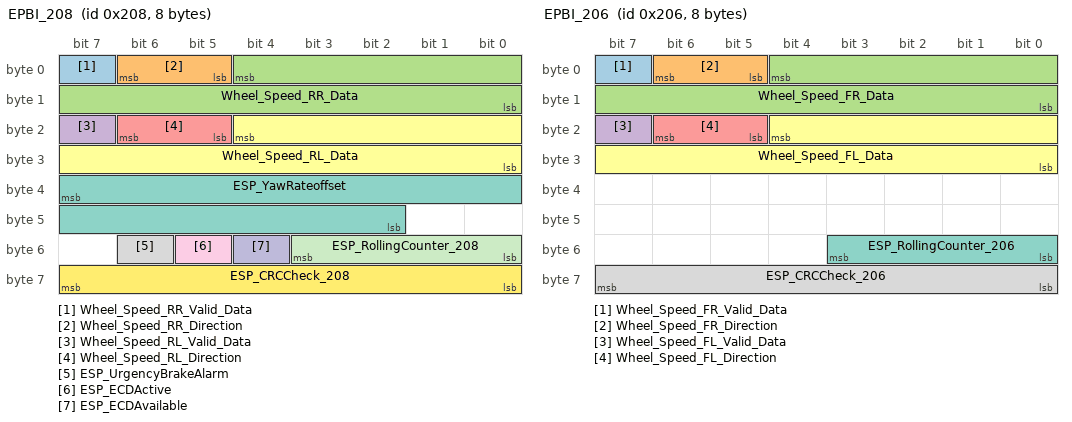
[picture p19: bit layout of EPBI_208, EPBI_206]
BO_ 520 EPBI_208: 8 EPBI
SG_ Wheel_Speed_RR_Valid_Data : 7|1@0+ (1,0) [0|1] "" BDCF
SG_ Wheel_Speed_RR_Direction : 6|2@0+ (1,0) [0|3] "" Vector__XXX
SG_ Wheel_Speed_RR_Data : 4|13@0+ (0.05625,0) [0|360] "km/h" Vector__XXX
SG_ Wheel_Speed_RL_Valid_Data : 23|1@0+ (1,0) [0|1] "" Vector__XXX
SG_ Wheel_Speed_RL_Direction : 22|2@0+ (1,0) [0|3] "" Vector__XXX
SG_ Wheel_Speed_RL_Data : 20|13@0+ (0.05625,0) [0|360] "km/h" Vector__XXX
SG_ ESP_YawRateoffset : 39|14@0+ (0.01,-81.91) [-81.91|81.91] "degree/s" Vector__XXX
SG_ ESP_UrgencyBrakeAlarm : 54|1@0+ (1,0) [0|1] "" Vector__XXX
SG_ ESP_ECDActive : 53|1@0+ (1,0) [0|1] "" Vector__XXX
SG_ ESP_ECDAvailable : 52|1@0+ (1,0) [0|1] "" Vector__XXX
SG_ ESP_RollingCounter_208 : 51|4@0+ (1,0) [0|15] "" Vector__XXX
SG_ ESP_CRCCheck_208 : 63|8@0+ (1,0) [0|255] "" Vector__XXX

BO_ 518 EPBI_206: 8 EPBI
SG_ Wheel_Speed_FR_Valid_Data : 7|1@0+ (1,0) [0|1] "" BDCF
SG_ Wheel_Speed_FR_Direction : 6|2@0+ (1,0) [0|3] "" Vector__XXX
SG_ Wheel_Speed_FR_Data : 4|13@0+ (0.05625,0) [0|360] "km/h" Vector__XXX
SG_ Wheel_Speed_FL_Valid_Data : 23|1@0+ (1,0) [0|1] "" Vector__XXX
SG_ Wheel_Speed_FL_Direction : 22|2@0+ (1,0) [0|3] "" Vector__XXX
SG_ Wheel_Speed_FL_Data : 20|13@0+ (0.05625,0) [0|360] "km/h" Vector__XXX
SG_ ESP_RollingCounter_206 : 51|4@0+ (1,0) [0|15] "" Vector__XXX
SG_ ESP_CRCCheck_206 : 63|8@0+ (1,0) [0|255] "" Vector__XXX

CM_ SG_ 1476 Digital_certificate_response "数字钥匙认证学习验证报文";
CM_ SG_ 1494 Digital_certificate_request "数字钥匙认证学习报文";
CM_ SG_ 1320 controller_number "付费功能控制器代码";
CM_ SG_ 1320 RemoteParking_payment_activation_status "遥控泊车付费激活";
CM_ SG_ 1320 group_number "车型分组编号（有多个分组时，循环发送）";
CM_ SG_ 1302 controller_number "付费功能控制器代码";
CM_ SG_ 1302 BSD_payment_activation_status "盲区监测付费激活状态";
CM_ SG_ 1302 BLE_payment_activation_status "蓝牙钥匙付费激活状态";
CM_ SG_ 1302 group_number "车型分组编号（有多个分组时，循环发送）";
CM_ SG_ 1383 MAC "MAC";
CM_ SG_ 1383 FV "FV";
CM_ SG_ 1383 RemoteParking_payment_activation "遥控泊车付费激活";
CM_ SG_ 1383 BSD_payment_activation "盲区监测付费激活";
CM_ SG_ 1383 group_number "车型分组编号（有多个分组时，循环发送）";
CM_ SG_ 1383 BLE_payment_activation "蓝牙钥匙付费激活";
CM_ SG_ 1329 HU_CAMReplayModeStatus "CAM记录回放模式请求";
CM_ SG_ 1329 HU_CAMRecordControl "拍照请求信号";
CM_ SG_ 1329 HU_CAMShootControl "拍照请求信号";
CM_ SG_ 1329 HU_CAMDisplayVision "CAM显示角度";
CM_ SG_ 1329 HU_CAMMode "CAM模式请求";
CM_ SG_ 1329 HU_DVRReplayMode "全景DVR回放模式";
CM_ SG_ 1034 BDC2_WakeUpSource "BDCR唤醒源信号";
CM_ SG_ 1034 BDCR_PTSStillOver10MinStatus "尾门无动作时间超过1分钟";
CM_ SG_ 1034 BDCR_SCMSwitchWakeUp "天窗开关信号触发唤醒";
CM_ SG_ 1034 BDCR_KeyRemoteOpenSCMWakeUp "遥控信号开启天窗唤醒";
CM_ SG_ 1034 BDCR_KickWakeUp "脚踢信号唤醒";
CM_ SG_ 1034 BDCR_PTSSwitchWakeUp "中控开启尾门按键信号触发唤醒";
CM_ SG_ 1034 BDCR_KeyRemoteOpenPTSWakeUp "遥控钥匙开启尾门唤醒";
CM_ SG_ 1034 BDCR_CanBusStatus "CAN总线状态";
CM_ SG_ 1034 BDCR_PowerStatus "电源档位";
CM_ SG_ 1034 BDCR_BusMessageWakeUpMold "总线唤醒类型";
CM_ SG_ 1034 BDCR_BusMessageWakeUp "总线唤醒";
CM_ SG_ 1034 BDCR_PowerDistributionStatus "电源状态变化引起唤醒（OFF->非OFF）";
CM_ SG_ 1034 BDCR_NMSleepAcknowledge "睡眠响应位";
CM_ SG_ 1034 BDCR_NMSleepIndication "睡眠标识位";
CM_ SG_ 1034 BDCR_NMLimphome "Limphome报文";
CM_ SG_ 1034 BDCR_NMRing "Ring报文";
CM_ SG_ 1034 BDCR_NMAlive "Alive报文";
CM_ SG_ 1034 BDCR_NMDestinationAddress "目的地址";
CM_ SG_ 1041 HU_G_sensorWakeup "碰撞G-sensor引起唤醒";
CM_ SG_ 1041 NM_Segment "NM报文所属网段";
CM_ SG_ 1041 HU_CanBusStatus "CAN总线状态";
CM_ SG_ 1041 HU_PowerDown10Min "整车下电满10min";
CM_ SG_ 1041 HU_RemoteLocksignal "遥控闭锁";
CM_ SG_ 1041 HU_PowerStatus "电源档位";
CM_ SG_ 1041 HU_TBOX_RemoteWakeup "远程控制引起唤醒";
CM_ SG_ 1041 HU_TBOX_ECALLRequestSwitch "ECALL按键开关引起唤醒";
CM_ SG_ 1041 HU_Chip "芯片引起唤醒";
CM_ SG_ 1041 HU_BusMessageWakeUpMold "总线唤醒类型";
CM_ SG_ 1041 HU_BusMessageWakeUp "总线唤醒";
CM_ SG_ 1041 HU_PowerDistributionStatus "电源状态变化引起唤醒（OFF->非OFF）";
CM_ SG_ 1041 HU_NMSleepAcknowledge "睡眠响应位";
CM_ SG_ 1041 HU_NMSleepIndication "睡眠标识位";
CM_ SG_ 1041 HU_NMLimphome "Limphome报文";
CM_ SG_ 1041 HU_NMRing "Ring报文";
CM_ SG_ 1041 HU_NMAlive "Alive报文";
CM_ SG_ 1041 HU_NMDestinationAddress "目的地址";
CM_ SG_ 1036 FIS_CanBusStatus "CAN总线状态";
CM_ SG_ 1036 FIS_PowerStatus "电源档位";
CM_ SG_ 1036 FIS_BusMessageWakeUpMold "总线唤醒类型";
CM_ SG_ 1036 FIS_BusMessageWakeUp "总线唤醒";
CM_ SG_ 1036 FIS_PowerDistributionStatus "电源状态变化引起唤醒（OFF->非OFF）";
CM_ SG_ 1036 FIS_NMSleepAcknowledge "睡眠响应位";
CM_ SG_ 1036 FIS_NMSleepIndication "睡眠标识位";
CM_ SG_ 1036 FIS_NMLimphome "Limphome报文";
CM_ SG_ 1036 FIS_NMRing "Ring报文";
CM_ SG_ 1036 FIS_NMAlive "Alive报文";
CM_ SG_ 1036 FIS_NMDestinationAddress "目的地址";
CM_ SG_ 1026 ESCL_VehicleSpeed "车速为0";
CM_ SG_ 1026 ESCL_CanBusStatus "CAN总线状态";
CM_ SG_ 1026 ESCL_PowerStatus "电源档位";
CM_ SG_ 1026 ESCL_BusMessageWakeUpMold "总线唤醒类型";
CM_ SG_ 1026 ESCL_BusMessageWakeUp "总线唤醒";
CM_ SG_ 1026 ESCL_PowerDistributionStatus "电源状态变化引起唤醒（OFF->非OFF）";
CM_ SG_ 1026 ESCL_NMSleepAcknowledge "睡眠响应位";
CM_ SG_ 1026 ESCL_NMSleepIndication "睡眠标识位";
CM_ SG_ 1026 ESCL_NMLimphome "Limphome报文";
CM_ SG_ 1026 ESCL_NMRing "Ring报文";
CM_ SG_ 1026 ESCL_NMAlive "Alive报文";
CM_ SG_ 1026 ESCL_NMDestinationAddress "目的地址";
CM_ SG_ 1025 IP_CanBusStatus "CAN总线状态";
CM_ SG_ 1025 IP_PowerStatus "电源档位";
CM_ SG_ 1025 IP_BusMessageWakeUpMold "总线唤醒类型";
CM_ SG_ 1025 IP_BusMessageWakeUp "总线唤醒";
CM_ SG_ 1025 IP_PowerDistributionStatus "电源状态变化引起唤醒（OFF->非OFF）";
CM_ SG_ 1025 IP_NMSleepAcknowledge "睡眠响应位";
CM_ SG_ 1025 IP_NMSleepIndication "睡眠标识位";
CM_ SG_ 1025 IP_NMLimphome "Limphome报文";
CM_ SG_ 1025 IP_NMRing "Ring报文";
CM_ SG_ 1025 IP_NMAlive "Alive报文";
CM_ SG_ 1025 IP_NMDestinationAddress "目的地址";
CM_ SG_ 1024 BDCF_DSMSleepStatus "座椅部分功能是否满足睡眠状态";
CM_ SG_ 1024 BDCF_DSMLocalSwitchWakeUp "座椅本地开关唤醒";
CM_ SG_ 1024 BDCF_RemoteSignalStatus "遥控信号输入状态";
CM_ SG_ 1024 BDCF_BrakePedalStatus "制动踏板状态";
CM_ SG_ 1024 BDCF_PowerSaveModeStatus "节电功能到期状态";
CM_ SG_ 1024 BDCF_lockPerformStatus "闭锁执行状态";
CM_ SG_ 1024 BDCF_UnlockPerformStatus "解锁执行状态";
CM_ SG_ 1024 BDCF_TurnLightSwitchStatus "转向灯开关状态";
CM_ SG_ 1024 BDCF_LinBusStatus "LIN总线状态";
CM_ SG_ 1024 BDCF_CanBusStatus "CAN总线状态";
CM_ SG_ 1024 BDCF_FollowMeHomeStatus "跟随回家功能执行状态";
CM_ SG_ 1024 BDCF_TrunkButtonStatus "行李箱解锁开关状态";
CM_ SG_ 1024 BDCF_DriverDoorHandleButtonStatus "驾驶侧门把手按钮状态";
CM_ SG_ 1024 BDCF_ALLDoorStatus "五门状态";
CM_ SG_ 1024 BDCF_SecondAntiTheftStatus "二次防盗功能执行状态";
CM_ SG_ 1024 BDCF_PositionLampStatus "位置灯灯光状态";
CM_ SG_ 1024 BDCF_PowerStatus "电源档位";
CM_ SG_ 1024 BDCF_GreetWakeUp "迎宾功能引起唤醒";
CM_ SG_ 1024 BDCF_BrakePedalWakeUp "制动踏板信号引起唤醒";
CM_ SG_ 1024 BDCF_DoorHandleButtonSignalWakeUp "门把手按钮状态信号引起唤醒";
CM_ SG_ 1024 BDCF_StartupButtonSignalWakeUp "启动按钮状态信号引起唤醒";
CM_ SG_ 1024 BDCF_OverTakeLightSwitchWakeUp "超车灯开关信号引起唤醒";
CM_ SG_ 1024 BDCF_Easy_openWakeUp "脚踢引起唤醒";
CM_ SG_ 1024 BDCF_TrunkSwitchCommandWakeUp "后背门按钮信号引起唤醒";
CM_ SG_ 1024 BDCF_KeyRemoteSignalWakeUp "遥控钥匙信号引起唤醒";
CM_ SG_ 1024 BDCF_DriverDoorUnlockorLockStatusWakeUp "机械钥匙解闭锁信号（主驾锁状态）变化引起唤醒";
CM_ SG_ 1024 BDCF_CentralUnlockorLockControlSignalWakeUp "中控解闭锁信号引起唤醒";
CM_ SG_ 1024 BDCF_DriverDoorStatusWakeUp "左前门状态变化引起唤醒";
CM_ SG_ 1024 BDCF_PassengerDoorStatusWakeUp "右前门状态变化引起唤醒";
CM_ SG_ 1024 BDCF_LeftRearDoorStatusWakeUp "左后门状态变化引起唤醒";
CM_ SG_ 1024 BDCF_RightRearDoorStatusWakeUp "右后门状态变化引起唤醒";
CM_ SG_ 1024 BDCF_TrunkStatusWakeUp "行李箱门状态变化引起唤醒";
CM_ SG_ 1024 BDCF_HoodStatusWakeUp "发动机舱盖状态变化引起唤醒";
CM_ SG_ 1024 BDCF_EmergencyLightSwitchWakeUp "紧急报警灯开关引起唤醒";
CM_ SG_ 1024 BDCF_PositionLampSwitchWakeUp "位置灯开关引起唤醒";
CM_ SG_ 1024 BDCF_BusMessageWakeUpMold "总线唤醒类型";
CM_ SG_ 1024 BDCF_BusMessageWakeUp "总线唤醒";
CM_ SG_ 1024 BDCF_PowerDistributionStatus "电源状态变化引起唤醒（OFF->非OFF）";
CM_ SG_ 1024 BDCF_NMSleepAcknowledge "睡眠响应位";
CM_ SG_ 1024 BDCF_NMSleepIndication "睡眠标识位";
CM_ SG_ 1024 BDCF_NMLimphome "Limphome报文";
CM_ SG_ 1024 BDCF_NMRing "Ring报文";
CM_ SG_ 1024 BDCF_NMAlive "Alive报文";
CM_ SG_ 1024 BDCF_NMDestinationAddress "目的地址";
CM_ SG_ 973 ACC_CRCCheck_3CD "ACC_3CD校验和";
CM_ SG_ 973 ACC_RollingCounter_3CD "ACC_3CD计数器";
CM_ SG_ 973 ADS_TunnelDis "隧道距离";
CM_ SG_ 973 ADS_TunnelStatus "隧道状态";
CM_ SG_ 973 ADS_RampStatus "匝道状态";
CM_ SG_ 973 ADS_PathThroughRamp "匝道信息";
CM_ SG_ 973 ADS_DisToRamp "匝道距离";
CM_ SG_ 971 ACC_CRCCheck_3CB "ACC_3CB校验和";
CM_ SG_ 971 ACC_RollingCounter_3CB "ACC_3CB计数器";
CM_ SG_ 971 ADS_RampSide "匝道方向";
CM_ SG_ 971 ADS_PathShowLngRange "轨迹显示纵向距离";
CM_ SG_ 971 ADS_RoadMergeLatRange "道路拼接点横向位置";
CM_ SG_ 971 ADS_EOMNotice "EOM提示信息";
CM_ SG_ 971 ADS_EOMTOReq "EOM接管请求";
CM_ SG_ 971 ADS_SeatPostureRectifyReq "驾驶员坐姿纠正请求";
CM_ SG_ 971 ADS_PromptCountDown "提示倒计时";
CM_ SG_ 971 ADS_EOMDwgradingnotice "EOM降级提示";
CM_ SG_ 971 ADS_AutoDriveStateDisplay "自动驾驶状态指示";
CM_ SG_ 970 ACC_CRCCheck_3CA "ACC_3CA校验和";
CM_ SG_ 970 ACC_RollingCounter_3CA "ACC_3CA计数器";
CM_ SG_ 970 ADS_PathShow_Status "轨迹显示状态";
CM_ SG_ 970 ADS_PathShow_C3 "轨迹显示C3";
CM_ SG_ 970 ADS_PathShow_C2 "轨迹显示C2";
CM_ SG_ 970 ADS_PathShow_C1 "轨迹显示C1";
CM_ SG_ 970 ADS_RoadSlopeShapeC3 "道路坡度形状参数C3";
CM_ SG_ 768 LCDAL_CRCCheck_300 "LCDAL_300校验和";
CM_ SG_ 768 LCDAL_RollingCounter_300 "LCDAL_300计数器";
CM_ SG_ 768 LCDAL_LRTargetID "左车道后方目标ID";
CM_ SG_ 768 LCDAL_RRTargetID "右车道后方目标ID";
CM_ SG_ 768 LCDAL_BackTargetID "后方目标ID";
CM_ SG_ 768 LCDAL_BackTargetDirection "后方目标方向";
CM_ SG_ 768 LCDAL_RRTargetDirection "右车道后方目标方向";
CM_ SG_ 759 LCDAL_CRCCheck_2F7 "LCDAL_2F7校验和";
CM_ SG_ 759 LCDAL_RollingCounter_2F7 "LCDAL_2F7报文计数器";
CM_ SG_ 759 LCDAL_RLTargetDirection "左车道后方目标方向";
CM_ SG_ 759 LCDAL_RRTargetDetection "右车道后方目标的识别情况";
CM_ SG_ 759 LCDAL_RRTargetLatRange "右车道后方目标横向距离";
CM_ SG_ 759 LCDAL_BackTargetType "后方目标类型";
CM_ SG_ 759 LCDAL_BackTargetLatRange "后方目标横向距离";
CM_ SG_ 759 LCDAL_BackTargetLngRange "后方目标纵向距离";
CM_ SG_ 759 LCDAL_BackTargetDetection "后方目标的识别情况";
CM_ SG_ 751 LCDAL_CRCCheck_2EF "LCDAL_2EF校验和";
CM_ SG_ 751 LCDAL_RollingCounter_2EF "LCDAL_2EF计数器";
CM_ SG_ 751 LCDAL_RRTargetType "右车道后方目标类型";
CM_ SG_ 751 LCDAL_RRTargetLngRange "右车道后方目标纵向距离";
CM_ SG_ 751 LCDAL_RLTargetType "左车道后方目标类型";
CM_ SG_ 751 LCDAL_RLTargetLatRange "左车道后方目标横向距离";
CM_ SG_ 751 LCDAL_RLTargetLngRange "左车道后方目标纵向距离";
CM_ SG_ 751 LCDAL_RLTargetDetection "左车道后方目标的识别情况";
CM_ SG_ 687 LCDAR_CRCCheck_2AF "LCDAR_2AF校验和";
CM_ SG_ 687 LCDAR_RollingCounter_2AF "LCDAR_2AF计数器";
CM_ SG_ 687 ADS_LCDAR_Left_LCAAlertForELK "左侧换道危险报警信号";
CM_ SG_ 687 LCDAR_RCTBTargetDecel "RCTB减速度";
CM_ SG_ 687 LCDAR_ELK_oAlert "后向右侧邻道超车预警信号";
CM_ SG_ 687 LCDAR_ELK_oStatus "左侧邻道超车预警功能模块状态";
CM_ SG_ 687 LCDAR_Left_ELK_oAlert "后向左侧邻道超车预警信号";
CM_ SG_ 687 LCDAR_RCTAStatus "后向右侧倒车横向预警功能模块状态";
CM_ SG_ 687 LCDAR_RCTBStatus "后向右侧倒车横向预警制动功能模块状态";
CM_ SG_ 687 LCDAR_RCTBEnable "RCTB使能开关状态";
CM_ SG_ 687 LCDAR_RCTBActive "RCTB激活";
CM_ SG_ 687 LCDAR_RCTAAlert "后向右侧倒车横向预警信号";
CM_ SG_ 687 LCDAR_BSD_LCAStatus "右侧盲点检测_换道辅助功能模块状态";
CM_ SG_ 687 LCDAR_BSD_LCAAlert "右侧盲点检测_换道辅助报警信号";
CM_ SG_ 687 LCDAR_SystemStatus "右侧并线辅助模块状态信号";
CM_ SG_ 687 LCDAR_RCTAEnableStatus "后向横向预警使能状态";
CM_ SG_ 687 LCDAR_Left_RCTAAlert "后向左侧倒车横向预警报警信号";
CM_ SG_ 687 LCDAR_Left_BSD_LCAAlert "左侧盲点检测_换道辅助报警信号";
CM_ SG_ 687 LCDAR_BSD_LCAEnableStatus "盲点检测_换道辅助使能状态";
CM_ SG_ 686 LCDAL_CRCCheck_2AE "ADS_2AE校验和";
CM_ SG_ 686 LCDAL_RollingCounter_2AE "ADS_2AE计数器";
CM_ SG_ 686 LCDAL_AudioWarningEnableStatus "语音警示开关状态";
CM_ SG_ 686 LCDAL_SEAStatus "左侧开门预警功能模块状态";
CM_ SG_ 686 LCDAL_SEAAlert "左侧开门预警信号";
CM_ SG_ 686 LCDAL_SEAEnableStatus "开门预警使能状态";
CM_ SG_ 686 LCDAL_Right_SEAAlert "右侧开门预警信号";
CM_ SG_ 686 LCDAL_RCWStatus "左侧后追尾预警功能模块状态";
CM_ SG_ 686 LCDAL_RCWAlert "左侧后追尾预警信号";
CM_ SG_ 686 LCDAL_RCWEnableStatus "后追尾预警使能状态";
CM_ SG_ 686 LCDAL_Right_RCWAlert "右侧后追尾预警信号";
CM_ SG_ 686 LCDAL_SystemStatus "左侧并线辅助模块状态信号";
CM_ SG_ 684 LCDAR_CRCCheck_2AC "LCDAR_2AC校验和";
CM_ SG_ 684 LCDAR_RollingCounter_2AC "LCDAR_2AC计数器";
CM_ SG_ 684 ADS_FRC_FCTAEnable "FCTA使能开关状态";
CM_ SG_ 684 ADS_FRC_FCTBStatus "后向右侧倒车横向预警制动功能模块状态";
CM_ SG_ 684 ADS_FLC_SystemStatus "左前角雷达状态信号";
CM_ SG_ 684 ADS_FRC_SystemStatus "右前角雷达状态信号";
CM_ SG_ 684 ADS_FRC_FCTARStatus "前向右侧横向预警功能模块状态";
CM_ SG_ 684 ADS_FRC_Right_FCTARAlert "前向右侧横向预警报警信号";
CM_ SG_ 684 ADS_FRC_Left_FCTALAlert "前向左侧横向预警报警信号";
CM_ SG_ 684 ADS_FRC_FCTBActive "FCTB激活";
CM_ SG_ 684 ADS_FRC_FCTBEnable "FCTB使能开关状态";
CM_ SG_ 684 ADS_FRC_FCTBTargetDeceleration "FCTB减速度";
CM_ SG_ 1771 GW_FBLRemoteSts "远程启动状态反馈";
CM_ SG_ 1771 GW_FBLVehicleChargeSts "充电状态反馈";
CM_ SG_ 1771 GW_FBLExceedSts "刷写状态反馈";
CM_ SG_ 1771 GW_FBLTempSts "温度状态反馈";
CM_ SG_ 1771 GW_FBLhandbreakSts "手刹状态反馈";
CM_ SG_ 1771 GW_InstallReqFeedbackShiftSts "档位状态反馈";
CM_ SG_ 1771 GW_VehicleSpeedSts "车速状态反馈";
CM_ SG_ 1771 GW_InstallReqFeedback_BatterySts "蓄电池状态反馈";
CM_ SG_ 1771 GW_InstallReqFeedback_PowerSts "整车电源挡位反馈";
CM_ SG_ 1771 GW_InstallReqFeedback "GW反馈TBOX刷写请求";
CM_ SG_ 906 HU_Thridscreen_switch "第三屏按键";
CM_ SG_ 906 HU_APA_OnOff_switch "APA泊车按键";
CM_ SG_ 906 HU_CloudCamera "云相机按键";
CM_ SG_ 906 HU_FIS_AVM_switch "多功能方向盘全景影像开关";
CM_ SG_ 906 HU_FIS_SeekPlus_switch "多功能方向盘下一曲/接听";
CM_ SG_ 906 HU_FIS_SeekReduce_switch "多功能方向盘上一曲/挂断";
CM_ SG_ 906 HU_FIS_Hungup_switch_signal "多功能方向盘挂电话";
CM_ SG_ 906 HU_FIS_Answer_switch_signal "多功能方向盘接电话";
CM_ SG_ 906 HU_FIS_VolPlus_switch "多功能方向盘音量加";
CM_ SG_ 906 HU_FIS_VolReduce_switch "多功能方向盘音量减";
CM_ SG_ 906 HU_FIS_Mute_switch "多功能方向盘静音";
CM_ SG_ 906 HU_FIS_Speech_switch "多功能方向盘语音控制";
CM_ SG_ 906 HU_FIS_Mode_switch "多功能方向盘多媒体模式切换";
CM_ SG_ 951 CAM_RecordStatus "CAM录制反馈信号";
CM_ SG_ 951 CAM_CAMReplayModeStatus "CAM记录回放模式请求";
CM_ SG_ 951 CAM_PhotographResult "照相结果";
CM_ SG_ 951 CAM_DisplayVision "CAM显示角度";
CM_ SG_ 951 CAM_CAMModeFeedback "CAM模式反馈";
CM_ SG_ 951 AVM_WheelHubSetSetStatus "轮毂样式设置状态";
CM_ SG_ 951 AVM_LicenseNumberSetStatus "车牌号设置状态";
CM_ SG_ 951 AVM_3DHorAngleStatus "3D视图水平角度状态";
CM_ SG_ 951 AVM_BodyColourSetStatus "车身颜色设置状态";
CM_ SG_ 951 AVM_AVMDVRReplayModeStatus "全景行车记录回放模式状态";
CM_ SG_ 1760 APA_AuthenticationStatus "APA认证状态";
CM_ SG_ 932 APA_RR_Rebuild_Target_Dist "右后场景重构_目标距离";
CM_ SG_ 932 APA_RF_Rebuild_Target_Dist "右前场景重构目标距离";
CM_ SG_ 932 APA_LR_Rebuild_Target_Dist "左后场景重构目标距离";
CM_ SG_ 932 APA_LF_Rebuild_Target_Dist "左前场景重构目标距离";
CM_ SG_ 932 HPA_RouteLibraryFeedback "路线库进入反馈";
CM_ SG_ 932 HPA_RouteLibraryReplayMode "路线库浏览模式反馈";
CM_ SG_ 932 HPA_PublicSlotRouteCounts "公共泊位路线数量";
CM_ SG_ 932 HPA_HomeSlotRouteCounts "固定泊位路线数量";
CM_ SG_ 932 HPA_RouteDeleteStatus "路线删除状态反馈";
CM_ SG_ 932 HPA_RouteEditFeedback "路线库编辑状态反馈";
CM_ SG_ 932 HPA_RouteCounts "路线总数量";
CM_ SG_ 932 HPA_SaveRoutePercentage "路线保存进度条";
CM_ SG_ 932 APA_IP_LeftSlot "左侧搜索到车位";
CM_ SG_ 932 APA_IP_RightSlot "右侧搜索到车位";
CM_ SG_ 932 APARemain_Dist "自动泊车剩余行驶距离";
CM_ SG_ 954 HPA_ParkNotice "HPA停车提示";
CM_ SG_ 954 APA_HPA_ParkNotice_Learn "HPA泊车提示";
CM_ SG_ 954 APA_UnintendedExitRecordingReq "APA泊车异常记录请求";
CM_ SG_ 954 APA_CRCCheck_3BA "APA_3BA校验和";
CM_ SG_ 954 APA_RollingCounter_3BA "APA_3BA计数器";
CM_ SG_ 954 APA_AVMNotice "影像跳转";
CM_ SG_ 954 APA_ASPSwitchSts "ASP开关状态";
CM_ SG_ 954 APA_CrossParkingModeSetSts "垂直泊车进入模式设置状态";
CM_ SG_ 954 APA_LAEBEnableSts "LAEB使能状态";
CM_ SG_ 954 APA_ASPModeSelectSts "ASP模式选择状态";
CM_ SG_ 954 APA_ASPRemindEnableSts "ASP主动提示使能状态";
CM_ SG_ 954 APA_SystemFailureFlag "系统故障";
CM_ SG_ 954 APA_ObstacleSafeDistSetStatus "泊车距障碍物停止距离设置";
CM_ SG_ 954 APA_RemoteDistanceSetStatus "遥控泊车行驶距离设置状态";
CM_ SG_ 954 APA_Uls_FKP_WarningSoundStatus "APA响应超声波侧面保护声音报警状态";
CM_ SG_ 954 APA_UnintendedExitRecordingReq "APA泊车异常记录请求";
CM_ SG_ 679 APA_CRCCheck_2A7 "APA_2A7校验和";
CM_ SG_ 679 APA_RollingCounter_2A7 "APA_2A7计数器";
CM_ SG_ 679 RFS_Sector_Dist "右前侧扇区距离";
CM_ SG_ 679 LFS_Sector_Dist "左前侧扇区距离";
CM_ SG_ 679 RFC_Sector_Dist "右前角扇区距离";
CM_ SG_ 679 LFC_Sector_Dist "左前角扇区距离";
CM_ SG_ 679 RFM_Sector_Dist "右前中扇区距离";
CM_ SG_ 679 LFM_Sector_Dist "左前中扇区距离";
CM_ SG_ 1295 APA_Coordinate_X "车位相对车身坐标X";
CM_ SG_ 1295 APA_Coordinate_Y "车位相对车身坐标Y";
CM_ SG_ 1295 APA_Coordinate_Angle "车位相对车身角度";
CM_ SG_ 682 APA_right_slot_4_available_sts "右侧4号车位可用状态";
CM_ SG_ 682 APA_right_slot_3_available_sts "右侧3号车位可用状态";
CM_ SG_ 682 APA_right_slot_2_available_sts "右侧2号车位可用状态";
CM_ SG_ 682 APA_right_slot_1_available_sts "右侧1号车位可用状态";
CM_ SG_ 682 APA_left_slot_4_available_sts "左侧4号车位可用状态";
CM_ SG_ 682 APA_left_slot_3_available_sts "左侧3号车位可用状态";
CM_ SG_ 682 APA_left_slot_2_available_sts "左侧2号车位可用状态";
CM_ SG_ 682 APA_left_slot_1_available_sts "左侧1号车位可用状态";
CM_ SG_ 682 APA_right_slot_4_distance_px "右侧4号车位距离";
CM_ SG_ 682 APA_right_slot_4_type "右侧4号车位类型";
CM_ SG_ 682 APA_right_slot_3_distance_px "右侧3号车位距离";
CM_ SG_ 682 APA_right_slot_3_type "右侧3号车位类型";
CM_ SG_ 682 APA_left_slot_4_distance_px "左侧4号车位距离";
CM_ SG_ 682 APA_left_slot_4_type "左侧4号车位类型";
CM_ SG_ 682 APA_left_slot_3_distance_px "左侧3号车位距离";
CM_ SG_ 682 APA_left_slot_3_type "左侧3号车位类型";
CM_ SG_ 678 APA_CRCCheck_2A6 "APA_2A6校验和";
CM_ SG_ 678 APA_RollingCounter_2A6 "APA_2A6计数器";
CM_ SG_ 678 RRS_Sector_Dist "右后侧扇区距离";
CM_ SG_ 678 LRS_Sector_Dist "左后侧扇区距离";
CM_ SG_ 678 RRC_Sector_Dist "右后角扇区距离";
CM_ SG_ 678 LRC_Sector_Dist "左后角扇区距离";
CM_ SG_ 678 RRM_Sector_Dist "右后中扇区距离";
CM_ SG_ 678 LRM_Sector_Dist "左后中扇区距离";
CM_ SG_ 765 RRF_Sector_Dist "右后边扇区距离";
CM_ SG_ 765 LRF_Sector_Dist "左后边扇区距离";
CM_ SG_ 765 RFF_Sector_Dist "右前边扇区距离";
CM_ SG_ 765 LFF_Sector_Dist "左前边扇区距离";
CM_ SG_ 765 RRS_LoudspeakersPosition "扬声器位置";
CM_ SG_ 767 RRS_LFSDistance "左前侧sensor障碍物距离";
CM_ SG_ 767 RRS_SwitchIndicatorError "倒车雷达开关指示灯故障";
CM_ SG_ 767 RRS_FrontRadarActiveStatus "前雷达激活设置反馈";
CM_ SG_ 767 RRS_SystemFailureFlag "系统故障";
CM_ SG_ 767 RRS_ButtonPress "倒车雷达开关动作";
CM_ SG_ 767 RRS_RFSDistance "右前侧sensor障碍物距离";
CM_ SG_ 767 RRS_LRSDistance "左后侧sensor障碍物距离";
CM_ SG_ 767 RRS_WarningFrequency "前后角识别";
CM_ SG_ 767 RRS_SideZoneStatus_Rear "后区雷达状态";
CM_ SG_ 767 RRS_WarningType "报警方式识别";
CM_ SG_ 767 RRS_MODE "倒车雷达的工作模式";
CM_ SG_ 767 RRS_RRSDistance "右后侧sensor障碍物距离";
CM_ SG_ 767 RRS_SideZoneStatus_Front "前区雷达状态";
CM_ SG_ 767 RRS_RFMDistance "右前中sensor障碍物距离";
CM_ SG_ 767 RRS_LFMDistance "左前中sensor障碍物距离";
CM_ SG_ 767 RRS_LFCDistance "左前sensor障碍物距离";
CM_ SG_ 767 RRS_RFCDistance "右前sensor障碍物距离";
CM_ SG_ 767 RRS_LRCDistance "左后角sensor障碍物距离";
CM_ SG_ 767 RRS_RRCDistance "右后角sensor障碍物距离";
CM_ SG_ 767 RRS_LRMDistance "后左中sensor障碍物距离";
CM_ SG_ 767 RRS_RRMDistance "后右中sensor障碍物距离";
CM_ SG_ 766 APA_CRCCheck_2FE "APA_2FE校验和";
CM_ SG_ 766 APA_RollingCounter_2FE "APA_2FE计数器";
CM_ SG_ 766 APA_right_fishboneslot_type "右侧鱼骨车位类型";
CM_ SG_ 766 APA_left_fishboneslot_type "左侧鱼骨车位类型";
CM_ SG_ 766 APA_right_slot_2_distance_px "右侧2号车位距离";
CM_ SG_ 766 APA_right_slot_2_type "右侧2号车位类型";
CM_ SG_ 766 APA_right_slot_1_distance_px "右侧1号车位距离";
CM_ SG_ 766 APA_right_slot_1_type "右侧1号车位类型";
CM_ SG_ 766 APA_left_slot_2_distance_px "左侧2号车位距离";
CM_ SG_ 766 APA_left_slot_2_type "左侧2号车位类型";
CM_ SG_ 766 APA_left_slot_1_distance_px "左侧1号车位距离";
CM_ SG_ 766 APA_left_slot_1_type "左侧1号车位类型";
CM_ SG_ 620 APA_CRCCheck_26C "APA_26C校验和";
CM_ SG_ 620 APA_RollingCounter_26C "APA_26C计数器";
CM_ SG_ 620 APA_PrefillReq "预夹紧请求";
CM_ SG_ 620 APA_DynamicSlotWarning "APA动态车位提示";
CM_ SG_ 620 APA_SlotNotice "自动泊车车位提示信号";
CM_ SG_ 620 APA_TCUClutchCombinationReq "离合器结合请求";
CM_ SG_ 620 APA_TrqHoldForTCUCl "TCU扭矩稳定标志";
CM_ SG_ 620 APA_AccPedShieldReq "加速踏板屏蔽请求";
CM_ SG_ 620 APA_ESPDecompressionModel "ESP泄压方式";
CM_ SG_ 620 APA_Activation_Status "APA激活状态";
CM_ SG_ 620 APA_TransPRNDShiftEnable "换档控制使能";
CM_ SG_ 620 APA_LSCAction "LSC功能开启状态";
CM_ SG_ 620 APA_HSAHDforbidden "AUtoHold功能、坡起辅助功能禁止请求";
CM_ SG_ 620 APA_EngineTrqReqEnable "扭矩请求使能";
CM_ SG_ 620 APA_EngTorqReq "APA扭矩请求";
CM_ SG_ 620 APA_EPBrequest "电子手刹请求";
CM_ SG_ 620 APA_TargetAcceleration "APA目标加速度";
CM_ SG_ 620 APA_TransPRNDShiftRequest "目标档位请求";
CM_ SG_ 620 APA_TransPRNDShiftReqValid "目标档位请求有效";
CM_ SG_ 621 APA_CRCCheck_26D "APA_26D校验和";
CM_ SG_ 621 APA_RollingCounter_26D "APA_26D计数器";
CM_ SG_ 621 APA_PrefillReq "预夹紧请求";
CM_ SG_ 621 APA_DynamicSlotWarning "APA动态车位提示";
CM_ SG_ 621 APA_SlotNotice "自动泊车车位提示信号";
CM_ SG_ 621 APA_TCUClutchCombinationReq "离合器结合请求";
CM_ SG_ 621 APA_TrqHoldForTCUCl "TCU扭矩稳定标志";
CM_ SG_ 621 APA_AccPedShieldReq "加速踏板屏蔽请求";
CM_ SG_ 621 APA_ESPDecompressionModel "ESP泄压方式";
CM_ SG_ 621 APA_Activation_Status "APA激活状态";
CM_ SG_ 621 APA_TransPRNDShiftEnable "换档控制使能";
CM_ SG_ 621 APA_LSCAction "LSC功能开启状态";
CM_ SG_ 621 APA_HSAHDforbidden "AUtoHold功能、坡起辅助功能禁止请求";
CM_ SG_ 621 APA_EngineTrqReqEnable "扭矩请求使能";
CM_ SG_ 621 APA_EngTorqReq "APA扭矩请求";
CM_ SG_ 621 APA_EPBrequest "电子手刹请求";
CM_ SG_ 621 APA_TargetAcceleration "APA目标加速度";
CM_ SG_ 621 APA_TransPRNDShiftRequest "目标档位请求";
CM_ SG_ 621 APA_TransPRNDShiftReqValid "目标档位请求有效";
CM_ SG_ 724 APA_CRCCheck_2D4 "APA_2D4校验和";
CM_ SG_ 724 APA_RollingCounter_2D4 "APA_2D4计数器";
CM_ SG_ 724 APA_BCMHornCommand "喇叭控制命令";
CM_ SG_ 724 APA_vehicleFrontdetect "车辆前方障碍物探测";
CM_ SG_ 724 APA_ReleasePressureReq "APA泄压起步请求";
CM_ SG_ 724 APA_PEPS_EngineOffLockRequest "遥控泊车完成熄火及闭锁请求";
CM_ SG_ 724 APA_PowerMirrorFoldReq "泊车过程外后视镜折叠请求";
CM_ SG_ 724 APA_ParkingModeAvailableSts "泊车模式可用状态";
CM_ SG_ 724 APA_NumberofParkingSlot "找到泊车车位数量";
CM_ SG_ 724 APA_LAEBNotice "LAEB_提示";
CM_ SG_ 724 APA_RemoteParkingUsingRemind "遥控泊车使用提示";
CM_ SG_ 724 APA_ASPAvailableStatus "ASP_功能可用状态";
CM_ SG_ 724 APA_ASPStatus "ASP工作状态";
CM_ SG_ 724 APA_CrossModeSelectReq "垂直泊车进入模式选择请求";
CM_ SG_ 724 APA_FunctionOnOffSts "APA功能开启状态";
CM_ SG_ 724 APA_LAEBStatus "LAEB工作状态";
CM_ SG_ 724 APA_BLEConnectionRemind "蓝牙连接提示";
CM_ SG_ 724 APA_ParkNotice_5 "自动泊车过程提示信号";
CM_ SG_ 724 APA_LAEBReq "LAEB请求";
CM_ SG_ 725 APA_CRCCheck_2D5 "APA_2D4校验和";
CM_ SG_ 725 APA_RollingCounter_2D5 "APA_2D4计数器";
CM_ SG_ 725 APA_BCMHornCommand "喇叭控制命令";
CM_ SG_ 725 APA_vehicleFrontdetect "车辆前方障碍物探测";
CM_ SG_ 725 APA_ReleasePressureReq "APA泄压起步请求";
CM_ SG_ 725 APA_PEPS_EngineOffLockRequest "遥控泊车完成熄火及闭锁请求";
CM_ SG_ 725 APA_PowerMirrorFoldReq "泊车过程外后视镜折叠请求";
CM_ SG_ 725 APA_ParkingModeAvailableSts "泊车模式可用状态";
CM_ SG_ 725 APA_NumberofParkingSlot "找到泊车车位数量";
CM_ SG_ 725 APA_LAEBNotice "LAEB_提示";
CM_ SG_ 725 APA_RemoteParkingUsingRemind "遥控泊车使用提示";
CM_ SG_ 725 APA_ASPAvailableStatus "ASP_功能可用状态";
CM_ SG_ 725 APA_ASPStatus "ASP工作状态";
CM_ SG_ 725 APA_CrossModeSelectReq "垂直泊车进入模式选择请求";
CM_ SG_ 725 APA_FunctionOnOffSts "APA功能开启状态";
CM_ SG_ 725 APA_LAEBStatus "LAEB工作状态";
CM_ SG_ 725 APA_BLEConnectionRemind "蓝牙连接提示";
CM_ SG_ 725 APA_ParkNotice_5 "自动泊车过程提示信号";
CM_ SG_ 725 APA_LAEBReq "LAEB请求";
CM_ SG_ 612 APA_CRCCheck_264 "APA_264校验和";
CM_ SG_ 612 APA_RollingCounter_264 "APA_264计数器";
CM_ SG_ 612 APA_ParkingPercentage "泊车进度条显示";
CM_ SG_ 612 APA_ParkNotice_4 "自动泊车过程提示信号";
CM_ SG_ 612 APA_ParkNotice "自动泊车过程提示信号";
CM_ SG_ 612 APA_RemoteOnOff "遥控钥匙方案_APA_发出信号给PEPS";
CM_ SG_ 612 APA_ButtonPress "APA开关状态";
CM_ SG_ 612 APA_IncreasePressureReq "APA请求主动建压请求";
CM_ SG_ 612 APA_TurnLightsCommand "转向灯控制命令";
CM_ SG_ 612 APA_SteeringAngleReq "APA转向角度请求";
CM_ SG_ 612 APA_ErrorStatus "自动泊车故障信号";
CM_ SG_ 612 APA_indication "APA功能指示";
CM_ SG_ 612 APA_APAOnOff "APA功能开启状态";
CM_ SG_ 612 APA_EmergenceBrake "紧急制动请求";
CM_ SG_ 983 ADS_CRCCheck_3D7 "ADS_3D7校验和";
CM_ SG_ 983 ADS_RollingCounter_3D7 "ADS_3D7计数器";
CM_ SG_ 983 ACC_SunroofControl "天窗控制";
CM_ SG_ 983 ACC_RightRearWindowControl "后排右侧车窗控制";
CM_ SG_ 983 ACC_LeftRearWindowControl "后排左侧车窗控制";
CM_ SG_ 983 ACC_PassengerWindowControl "副驾车窗控制";
CM_ SG_ 983 ACC_DriverWindowControl "主驾车窗控制";
CM_ SG_ 861 ACC_CRCCheck_35D "ACC_35D校验和";
CM_ SG_ 861 ACC_RollingCounter_35D "ACC_35D计数器";
CM_ SG_ 861 ACC_FRTarget1Direction "右车道前方目标1方向";
CM_ SG_ 861 ACC_FRTarget1Type "右车道前方目标1类型";
CM_ SG_ 861 ACC_FRTarget1LatRange "右车道前方目标1横向距离";
CM_ SG_ 861 ACC_FRTarget1LngRange "右车道前方目标1纵向距离";
CM_ SG_ 861 ACC_FRTarget1Detection "右车道前方目标1的识别情况";
CM_ SG_ 861 ACC_FLTarget2LatRange "左车道前方目标2横向距离";
CM_ SG_ 860 ACC_CRCCheck_35C "ACC_35C校验和";
CM_ SG_ 860 ACC_RollingCounter_35C "ACC_35C计数器";
CM_ SG_ 860 ACC_FRTarget2Direction "右车道前方目标2方向";
CM_ SG_ 860 ACC_FRTarget2Type "右车道前方目标2类型";
CM_ SG_ 860 ACC_FRTarget2LatRange "右车道前方目标2横向距离";
CM_ SG_ 860 ACC_FRTarget2LngRange "右车道前方目标2纵向距离";
CM_ SG_ 860 ACC_FRTarget2Detection "右车道前方目标2的识别情况";
CM_ SG_ 968 ACC_CRCCheck_3C8 "ACC_3C8校验和";
CM_ SG_ 968 ACC_RollingCounter_3C8 "ACC_3C8计数器";
CM_ SG_ 968 ADS_RoadSlopeShapeC2 "道路坡度形状参数C2";
CM_ SG_ 968 ADS_RoadSlopeShapeC1 "道路坡度形状参数C1";
CM_ SG_ 968 ADS_RoadMergeLngRange "道路拼接点纵向位置";
CM_ SG_ 968 ADS_RoadSlopeFlag "道路坡度标志位";
CM_ SG_ 968 ADS_RoadMergeFlag "道路拼接标志位";
CM_ SG_ 968 ADS_RemoteRoadShapeC3 "远端道路形状参数C3";
CM_ SG_ 968 ACC_TakeoverReqAtIPFail "IP故障时驾驶员接管请求";
CM_ SG_ 781 ACC_CRCCheck_30D "ACC_30D校验和";
CM_ SG_ 781 ACC_RollingCounter_30D "ACC_30D计数器";
CM_ SG_ 781 ACC_HighBeamControl "远近光灯切换点亮请求";
CM_ SG_ 781 ACC_RRLaneDistance "车辆中心到右右侧车道线的距离";
CM_ SG_ 781 ACC_RRLaneDetection "右右侧车道线识别情况";
CM_ SG_ 781 ACC_LLLaneDistance "车辆中心到左左侧车道线的距离";
CM_ SG_ 781 ACC_LLLaneDetection "左左侧车道线识别情况";
CM_ SG_ 781 ACC_DoorCtrlReq "车门闭锁请求";
CM_ SG_ 781 ACC_EmergencyLightingRequest "危险报警灯点亮请求";
CM_ SG_ 781 ACC_TargetBasedLateralControl "横向控制目标类型";
CM_ SG_ 781 ACC_DriverHandsOffStatus "驾驶员脱手状态";
CM_ SG_ 781 ACC_IACCHWATextInfoForDriver "IACC驾驶员信息提示";
CM_ SG_ 781 ACC_HandsOnReq "handsOn请求";
CM_ SG_ 781 ACC_LatTakeoverReq "横向接管请求";
CM_ SG_ 781 ACC_IACCHWAMode "IACC/HWA工作模式";
CM_ SG_ 871 ACC_CRCCheck_367 "ACC_367校验和";
CM_ SG_ 871 ACC_RollingCounter_367 "ACC_367计数器";
CM_ SG_ 871 ACC_LatPathHeadingAngle "横向目标轨迹与实际轨迹航向角偏差";
CM_ SG_ 871 ACC_LatPathDY "横向目标轨迹与实际轨迹间距";
CM_ SG_ 871 ACC_ELKEnableStatus "紧急车道保持开关状态";
CM_ SG_ 871 ADS_IsInFence "是否在电子围栏内";
CM_ SG_ 871 ACC_ELKInterventionMode "紧急车道保持模式";
CM_ SG_ 871 ACC_ELKMode "紧急车道保持系统状态";
CM_ SG_ 871 ACC_HostPedLatRange_1 "本车道行人目标1横向距离";
CM_ SG_ 871 ACC_HostPedLngRange_1 "本车道行人目标1纵向距离";
CM_ SG_ 871 ACC_HostPedDetection_1 "本车道行人目标1识别结果";
CM_ SG_ 778 ACC_CRCCheck_30A "ACC_30A校验和";
CM_ SG_ 778 ACC_RollingCounter_30A "ACC_30A计数器";
CM_ SG_ 778 ACC_LaneChangeStatus "变道状态";
CM_ SG_ 778 ACC_RoadCurvatureFar "前方80m处道路曲率";
CM_ SG_ 778 ACC_RoadCurvatureNear "前方50m处道路曲率";
CM_ SG_ 778 ACC_RoadCurvature "当前位置道路曲率";
CM_ SG_ 778 ACC_LLaneMarkerType "左侧车道线类型";
CM_ SG_ 778 ACC_HostLaneLeftStatus "本车道左侧车道线状态";
CM_ SG_ 778 ACC_HostLaneRightStatus "本车道右侧车道线状态";
CM_ SG_ 778 ACC_LASWarningModeSelectionSts "LAS警告方式状态";
CM_ SG_ 778 ACC_LDWShakeLevStatus "LDW震动强度状态";
CM_ SG_ 778 ACC_IACCHWAEnable "IACC/HWA使能开关状态";
CM_ SG_ 778 ACC_LASModeSelectionStatus "LAS模式选择信号状态";
CM_ SG_ 778 ACC_RLaneMarkerType "右侧车道线类型";
CM_ SG_ 877 ACC_CRCCheck_36D "ACC_36D校验和";
CM_ SG_ 877 ACC_RollingCounter_36D "ACC_36D计数器";
CM_ SG_ 877 ACC_FRadarFailureStatus "前毫米波雷达失效状态";
CM_ SG_ 877 ACC_Voiceinfo "驾驶辅助声音信息";
CM_ SG_ 877 ACC_AEBTargetmode "AEB目标模式";
CM_ SG_ 877 ACC_AEBTextInfo "AEB信息提示";
CM_ SG_ 877 ACC_AEBStatus "AEB系统状态";
CM_ SG_ 877 ACC_AEBTargetLatRange "AEB目标横向距离";
CM_ SG_ 877 ACC_AEBTargetRelSpeed "AEB目标纵向相对速度";
CM_ SG_ 877 ACC_AEBTargetLngRange "AEB目标纵向距离";
CM_ SG_ 998 ACC_CRCCheck_3E6 "ACC_3E6校验和";
CM_ SG_ 998 ACC_RollingCounter_3E6 "ACC_3E6计数器";
CM_ SG_ 998 ACC_LaneEquationStatus "车道线方程状态信号";
CM_ SG_ 998 ACC_LaneEquationC3 "车道线方程系数C3";
CM_ SG_ 998 ACC_LaneEquationC2 "车道线方程系数C2";
CM_ SG_ 998 ACC_LaneEquationC1 "车道线方程系数C1";
CM_ SG_ 998 ACC_LaneQuality "车道线置信度";
CM_ SG_ 996 ACC_CRCCheck_3E4 "ACC_3E4校验和";
CM_ SG_ 996 ACC_RollingCounter_3E4 "ACC_3E4计数器";
CM_ SG_ 996 ACC_FRTarget2ID "右车道前方目标2ID";
CM_ SG_ 996 ACC_AEBTargetType "AEB锁定目标类型";
CM_ SG_ 996 ACC_AEBTargetDetection "AEB目标识别情况";
CM_ SG_ 996 ACC_AEBTargetDirection "AEB目标方向";
CM_ SG_ 996 ACC_RLaneDistanceFusion "车辆中心到右侧车道线的距离";
CM_ SG_ 996 ACC_LLaneDistanceFusion "车辆中心到左侧车道线的距离";
CM_ SG_ 996 ACC_HostPotentialTargetID "本车道潜在目标目标ID";
CM_ SG_ 996 ACC_FLTarget2ID "左车道前方目标2ID";
CM_ SG_ 996 ACC_FRTarget1ID "右车道前方目标1ID";
CM_ SG_ 996 ACC_FLTarget1ID "左车道前方目标1ID";
CM_ SG_ 996 ACC_ACCTargetID "ACC目标ID";
CM_ SG_ 863 ACC_CRCCheck_35F "ACC_35F校验和";
CM_ SG_ 863 ACC_RollingCounter_35F "ACC_35F计数器";
CM_ SG_ 863 ACC_CSLSetReq "一键设定巡航车速请求";
CM_ SG_ 863 ACC_CSLAEnableStatus "自动调整巡航车速使能状态";
CM_ SG_ 863 ACC_HostPotentialTargetDirection "本车道潜在目标方向";
CM_ SG_ 863 ACC_HostPotentialTargetLatRange "本车道潜在目标横向距离";
CM_ SG_ 863 ACC_HostPotentialTargetLngRange "本车道潜在目标纵向距离";
CM_ SG_ 863 ACC_HostPotentialTargetDetection "本车道潜在目标的识别情况";
CM_ SG_ 863 ACC_HostPotentialTargetType "本车道潜在目标类型";
CM_ SG_ 862 ACC_CRCCheck_35E "ACC_35E校验和";
CM_ SG_ 862 ACC_RollingCounter_35E "ACC_35E计数器";
CM_ SG_ 862 ACC_SaftyBelt_Tightened "安全带收紧命令";
CM_ SG_ 862 ACC_SaftyBeltVibrationReq "安全带振动命令";
CM_ SG_ 862 ACC_CruiseSetStatus "巡航模式状态";
CM_ SG_ 862 ACC_ACCObjSoundEnable "车辆识别声音提示使能开关状态";
CM_ SG_ 862 ACC_AEBEnable "AEB使能开关状态";
CM_ SG_ 862 ACC_FCWSettingStatus "FCW设置状态";
CM_ SG_ 862 ACC_TimeGapSet "ACC跟车时距设置";
CM_ SG_ 862 ACC_DistanceLevel "ACC跟车距离等级";
CM_ SG_ 862 ACC_ACCEPBrequest "EPB介入请求";
CM_ SG_ 862 ACC_LngTakeOverReq "纵向接管请求";
CM_ SG_ 862 ACC_ObjValid "ACC目标识别情况";
CM_ SG_ 862 ACC_SetSpeed "ACC目标巡航车速";
CM_ SG_ 836 ACC_CRCCheck_344 "ACC_344校验和";
CM_ SG_ 836 ACC_RollingCounter_344 "ACC_344计数器";
CM_ SG_ 836 ACC_FLTarget2Type "左车道前方目标2类型";
CM_ SG_ 836 ACC_FLTarget2LngRange "左车道前方目标2纵向距离";
CM_ SG_ 836 ACC_FLTarget2Detection "左车道前方目标2的识别情况";
CM_ SG_ 836 ACC_FLTarget2Direction "左车道前方目标2方向";
CM_ SG_ 836 ACC_FLTarget1Detection "左车道前方目标1的识别情况";
CM_ SG_ 836 ACC_FLTarget1Direction "左车道前方目标1方向";
CM_ SG_ 836 ACC_FLTarget1Type "左车道前方目标1类型";
CM_ SG_ 836 ACC_FLTarget1LatRange "左车道前方目标1横向距离";
CM_ SG_ 836 ACC_FLTarget1LngRange "左车道前方目标1纵向距离";
CM_ SG_ 802 ACC_CRCCheck_322 "ACC_322校验和";
CM_ SG_ 802 ACC_RollingCounter_322 "ACC_322计数器";
CM_ SG_ 802 ACC_ACCTargetDirection "ACC目标方向";
CM_ SG_ 802 ACC_ACCTargetLatRange "ACC目标横向距离";
CM_ SG_ 802 ACC_ACCTargetRelSpd "ACC目标纵向相对速度";
CM_ SG_ 802 ACC_FRadarCalibrationStatus "前毫米波雷达校准状态";
CM_ SG_ 802 ACC_TextInfoForDriver "ACC文字提示";
CM_ SG_ 802 ACC_HostTargetDetection "本车道目标的识别情况";
CM_ SG_ 802 ACC_DistanceAlertLevel "车距报警等级";
CM_ SG_ 802 ACC_ACCTargetType "ACC目标类型";
CM_ SG_ 802 ACC_ACCTargetLngRange "ACC目标车纵向距离";
CM_ SG_ 606 ACC_CRCCheck_25E "ACC_25E校验和";
CM_ SG_ 606 ACC_RollingCounter_25E "ACC_25E计数器";
CM_ SG_ 606 ACC_FuelCutOffPrevention "ACC禁止断油信号";
CM_ SG_ 606 ACC_AEBCtrlType "AEB请求类型";
CM_ SG_ 606 ACC_AccTrqReqActive "ACC扭矩请求激活";
CM_ SG_ 606 ACC_AccTrqReq "ACC扭矩请求值";
CM_ SG_ 606 ACC_AEBVehilceHoldReq "AEB停车保压请求";
CM_ SG_ 606 ACC_FCWPreWarning "前碰撞预警提醒";
CM_ SG_ 606 ACC_FCWLatentWarning "安全距离提醒报警";
CM_ SG_ 606 ACC_FCWActive "前碰撞预警激活";
CM_ SG_ 606 ACC_PrefillActive "AEB预填充请求";
CM_ SG_ 606 ACC_AWBActive "AWB激活";
CM_ SG_ 606 ACC_AWBlevel "AWB等级";
CM_ SG_ 606 ACC_ABAActive "ABA激活";
CM_ SG_ 606 ACC_ABAlevel "ABA等级";
CM_ SG_ 606 ACC_AEBActive "AEB减速激活";
CM_ SG_ 606 ACC_AEBTargetDeceleration "AEB目标减速度";
CM_ SG_ 590 ACC_CRCCheck_24E "ACC_24E校验和";
CM_ SG_ 590 ACC_RollingCounter_24E "ACC_24E计数器";
CM_ SG_ 590 ACC_ACCMode "ACC工作模式";
CM_ SG_ 590 ACC_Driveoff_Request "ACC起步请求";
CM_ SG_ 590 ACC_EngineStartStopRequest "ACC怠速起停请求";
CM_ SG_ 590 ACC_LimitSwitchArbitration "限速开关仲裁结果";
CM_ SG_ 590 ACC_CDDActive "ACC减速激活";
CM_ SG_ 590 ACC_CCMode "定速巡航工作模式";
CM_ SG_ 590 ACC_TCUCreepProhibition "禁止TCU进入爬行模式";
CM_ SG_ 590 ACC_DecToStop "ACC停车请求";
CM_ SG_ 590 ACC_EmergencyDataRrdReq "ACC紧急数据记录请求";
CM_ SG_ 590 ACC_LDWStatus "LDW状态";
CM_ SG_ 590 ACC_LDWVibrationWarningReq "振动报警请求";
CM_ SG_ 590 ACC_ACCTargetAcceleration "ACC目标加速度值";
CM_ SG_ 448 ACC_CRCCheck_1C0 "ACC_1C0校验和";
CM_ SG_ 448 ACC_RollingCounter_1C0 "ACC_1C0计数器";
CM_ SG_ 448 ACC_LatAngReqActive "转向角请求激活";
CM_ SG_ 448 ACC_LatAngReq "转向角请求（方向盘端）";
CM_ SG_ 448 ACC_MotorTorqueMinLimitRequest "EPS电机扭矩最小限制值";
CM_ SG_ 448 ACC_MotorTorqueMaxLimitRequest "EPS电机扭矩最大限制值";
CM_ SG_ 980 LAS_CRCCheck_3D4 "LAS_3D4校验和";
CM_ SG_ 980 LAS_RollingCounter_3D4 "LAS_3D4计数器";
CM_ SG_ 980 LAS_TLAStopLine_HostLane "本车道停止线距离";
CM_ SG_ 980 LAS_TLADistance__HostLane "本车道交通信号灯距离";
CM_ SG_ 980 LAS_TLACountDownTime_HostLane "本车道交通灯倒计时";
CM_ SG_ 980 LAS_TSRWarningSign "警告标志";
CM_ SG_ 980 LAS_TSRProhibitionSign "禁令标志";
CM_ SG_ 980 LAS_TSRMandatorySign "指示标志";
CM_ SG_ 818 LAS_CRCCheck_332 "LAS_332校验和";
CM_ SG_ 818 LAS_RollingCounter_332 "LAS_332计数器";
CM_ SG_ 818 LAS_TSRRightLaneStatus "右车道交通标示识别状态";
CM_ SG_ 818 LAS_TSRLeftLaneStatus "左车道交通标示识别状态";
CM_ SG_ 818 LAS_TSRHostSpdLimitUnits "本车道限速值显示单位";
CM_ SG_ 818 LAS_HMAStatus "自动大灯状态";
CM_ SG_ 818 LAS_TSRHostSpdLimit "本车道限速值";
CM_ SG_ 818 LAS_TSRStatus "交通标示识别状态";
CM_ SG_ 818 LAS_OverspeedSoundWarningEnSt "超速预警提示音状态";
CM_ SG_ 818 LAS_TSREnable "交通标志识别使能状态";
CM_ SG_ 818 LAS_FrontCameraFailureStatus "前置智能摄像头状态";
CM_ SG_ 818 LAS_FrontCameraCalibrationStatus "前置智能摄像头校准状态";
CM_ SG_ 818 LAS_HMAEnableStatus "智能远光功能开启状态";
CM_ SG_ 818 LAS_HMALightDistribution "自动灯光分配";
CM_ SG_ 818 LAS_OverspeedWarningOffset "超速预警偏差状态";
CM_ SG_ 818 LAS_OverspeedWarningEnableStatus "超速预警开关状态";
CM_ SG_ 818 LAS_OverspeedSoundWarning "超速预警声音报警";
CM_ SG_ 818 LAS_OverspeedVisualWarning "超速预警图像报警";
CM_ SG_ 893 LAS_CRCCheck_37D "LAS_37D校验和";
CM_ SG_ 893 LAS_RollingCounter_37D "LAS_37D计数器";
CM_ SG_ 893 LAS_TLAObjectStatus_LeftLane "左车道交通灯状态";
CM_ SG_ 893 LAS_TLAObjectStatus_RightLane "右车道交通灯状态";
CM_ SG_ 893 LAS_TLAArrowDirection_RightLane "右车道交通灯方向";
CM_ SG_ 893 LAS_TLAObjectType_RightLane "右车道交通灯类型";
CM_ SG_ 893 LAS_TLAObjectColour_RightLane "右车道交通灯颜色";
CM_ SG_ 893 LAS_TLAObjectDetection_RightLane "右车道交通灯识别情况";
CM_ SG_ 893 LAS_TLAArrowDirection_LeftLane "左车道交通灯方向";
CM_ SG_ 893 LAS_TLAObjectType_LeftLane "左车道交通灯类型";
CM_ SG_ 893 LAS_TLAObjectColour_LeftLane "左车道交通灯颜色";
CM_ SG_ 893 LAS_TLAObjectDetection_LeftLane "左车道交通灯识别情况";
CM_ SG_ 893 LAS_TLAObjectType_HostLane "本车道交通灯类型";
CM_ SG_ 893 LAS_TLAArrowDirection_HostLane "本车道交通灯方向";
CM_ SG_ 893 LAS_TLAObjectDetection_HostLane "本车道交通灯识别情况";
CM_ SG_ 893 LAS_TLAObjectColour_HostLane "本车道交通灯颜色";
CM_ SG_ 893 LAS_TLAWarninglevel "交通灯辅助系统报警等级";
CM_ SG_ 893 LAS_TLAStatus "交通灯辅助系统状态";
CM_ SG_ 893 LAS_TLAEnable "交通灯辅助系统开关状态";
CM_ SG_ 893 LAS_TLAObjectStatus_HostLane "本车道交通灯状态";
CM_ SG_ 960 LAS_CRCCheck_3C0 "LAS_3C0校验和";
CM_ SG_ 960 LAS_RollingCounter_3C0 "LAS_3C0计数器";
CM_ SG_ 960 LAS_TSRRightLaneSpdLimit "右侧车道限速值";
CM_ SG_ 960 LAS_TSRLeftLaneSpdLimit "左侧车道限速值";
CM_ SG_ 856 ADS_CRCCheck_358 "DAS_358校验和";
CM_ SG_ 856 ADS_RollingCounter_358 "DAS_358计数器";
CM_ SG_ 856 ADS_UDLCTextInfoForDriver "UDLC驾驶员信息提示";
CM_ SG_ 856 ADS_LightColorRequest "ADS请求灯带颜色";
CM_ SG_ 856 ADS_LightFlashRequest "ADS请求灯带闪烁";
CM_ SG_ 856 ADS_HighBeamLampOnRequest "远光灯点亮请求";
CM_ SG_ 856 ADS_LightingReq "氛围灯请求";
CM_ SG_ 856 ADS_RLaneColor "右车道颜色";
CM_ SG_ 856 ADS_AutoHeadlightshift_Req "ADS自动大灯档位请求";
CM_ SG_ 856 ADS_LLaneColor "左车道颜色";
CM_ SG_ 856 ADS_UDLCTurnLeftRequest "左侧主动换道请求";
CM_ SG_ 856 ADS_UDLCTurnLightReq "转向灯请求";
CM_ SG_ 856 ADS_AutoWiperShift_Rqe "自动雨刮档位请求";
CM_ SG_ 856 ADS_UDLCTurnRightRequest "右侧主动换道请求";
CM_ SG_ 856 ADS_ESSEnable "紧急转向辅助开关状态";
CM_ SG_ 856 ACC_HornCommand "ADS喇叭请求";
CM_ SG_ 856 ADS_UDLCRightStatus "右侧主动换道状态";
CM_ SG_ 856 ADS_LightFrequencyRequest "ADS请求频率";
CM_ SG_ 856 ADS_LightBrightRequest "ADS请求亮度";
CM_ SG_ 856 ADS_UDLCLeftStatus "左侧主动换道状态";
CM_ SG_ 856 ADS_UDLCStatus "主动换道状态";
CM_ SG_ 856 ADS_UDLCEnableStatus "主动换道开关状态";
CM_ SG_ 856 ADS_LowBeamLampOnRequest "近光灯点亮请求";
CM_ SG_ 856 ADS_ESSMode "紧急转向辅助系统状态";
CM_ SG_ 834 ADS_CRCCheck_342 "DAS_342校验和";
CM_ SG_ 834 ADS_RollingCounter_342 "DAS_342计数器";
CM_ SG_ 834 ADS_ToTargetLatDistance "距目标位置实时横向距离";
CM_ SG_ 834 ADS_rescueReq "ADS救援请求";
CM_ SG_ 834 ADS_SafeStopSts "安全停车状态";
CM_ SG_ 834 ADS_EyesOffWarningInhi "驾驶员EyesOff报警抑制";
CM_ SG_ 834 ADS_EOMWarnning "EOM报警";
CM_ SG_ 1534 GW_FBLPowerHoldOFFGear "刷写档位保持OFF档";
CM_ SG_ 1534 GW_CRCCheck_5FE "GW_5FE校验和";
CM_ SG_ 1534 GW_RollingCounter_5FE "GW_5FE计数器";
CM_ SG_ 1534 GW_FBLPowerHold "刷写档位保持信号";
CM_ SG_ 1534 GW_FBLPowerReq "刷写档位请求";
CM_ SG_ 801 GW_OTAmode_Chks "OTA模式信号校验和";
CM_ SG_ 801 GW_OTAmode_Cntr "OTA模式信号计数器";
CM_ SG_ 801 GW_OTAmode "OTA模式";
CM_ SG_ 1014 EDL_LckSts "差速锁状态";
CM_ SG_ 950 ATB_CRCCheck_3B6 "ATB_3B6校验和";
CM_ SG_ 950 ATB_RollingCounter_3B6 "ATB_3B6计数器";
CM_ SG_ 950 ATB_WarningDisp "全地形开关切换提醒显示";
CM_ SG_ 950 ATB_DriveMode "全地形开关驾驶模式";
CM_ SG_ 584 AWD_CRCCheck_248 "AWD_248校验和";
CM_ SG_ 584 AWD_RollingCounter_248 "AWD_248计数器";
CM_ SG_ 584 AWD_EstimatedTorque "理论扭矩";
CM_ SG_ 584 AWD_EngineLimitingRequest "发动机限扭请求";
CM_ SG_ 584 AWD_ATSReqRefuse "四驱拒绝响应全地形请求";
CM_ SG_ 584 AWD_SystemOperatingMode "四驱工作模式";
CM_ SG_ 584 AWD_ClutchCircuitFaultStatus "离合电路故障状态";
CM_ SG_ 584 AWD_EngineLimitingEnable "发动机限扭请求使能";
CM_ SG_ 846 AWD_CRCCheck_34E "AWD_34E校验和";
CM_ SG_ 846 AWD_RollingCounter_34E "AWD_34E计数器";
CM_ SG_ 846 AWD_Lamp4WDLow "四驱低速模式灯";
CM_ SG_ 846 AWD_Lamp4WDAuto "四驱自动模式灯";
CM_ SG_ 846 AWD_LampDiag "诊断指示灯";
CM_ SG_ 846 AWD_Lamp2WD "二驱指示灯";
CM_ SG_ 846 AWD_Lamp4WDLock "四驱锁止模式灯";
CM_ SG_ 846 AWD_CouplingFaultStatus "耦合失效状态";
CM_ SG_ 846 AWD_CouplingThermalFailsafe "过热保护";
CM_ SG_ 846 AWD_ExternalRequestsIgnored "外部响应忽略";
CM_ SG_ 846 AWD_SystemType "四驱类型";
CM_ SG_ 846 AWD_ModeChangeInProgress "模式切换";
CM_ SG_ 80 SRS_RollingCounter_id050 "SRS_050报文计数器";
CM_ SG_ 80 SRS_RightRearBuckleSwitchSts "第二排右安全带扣状态";
CM_ SG_ 80 SRS_FrontPsgOccupancy "前排乘客座是否被占用";
CM_ SG_ 80 SRS_MiddleRearBuckleSwitchSts "第二排中安全带扣状态";
CM_ SG_ 80 SRS_PADIndication "副驾安全气囊禁用指示";
CM_ SG_ 80 SRS_WarningLampStatus "SRS故障信号（警告灯信号）";
CM_ SG_ 80 SRS_LeftRearBuckleSwitchSts "第二排左安全带扣状态";
CM_ SG_ 80 SRS_PassengerBuckleSwitchStatus "副驶安全带扣状态";
CM_ SG_ 80 SRS_DriverBuckleSwitchStatus "主驶安全带扣状态";
CM_ SG_ 80 SRS_CrashOutputStatusCheckSum "碰撞校验信号";
CM_ SG_ 80 SRS_CrashOutputStatus "碰撞输出信号";
CM_ SG_ 1288 ESP_CRCCheck_508 "ESP_508报文计数器";
CM_ SG_ 1288 ESP_RollingCounter_508 "ESP_508计数器";
CM_ SG_ 1288 ESP_WheelSpdSensorEcuError "轮速传感器ECU故障检测";
CM_ SG_ 1288 ESP_WheelSpdSensorError "轮速传感器故障检测";
CM_ SG_ 1288 ESP_RRWheelSpdSensorSigFailure "后右轮速信号故障";
CM_ SG_ 1288 ESP_RRWheelSpdSensor_Open "后右轮速电源开路检测";
CM_ SG_ 1288 ESP_RRWheelSpdSensor_ShtBAT "后右轮速电源短路检测";
CM_ SG_ 1288 ESP_RRWheelSpdSensor_GND "后右轮速对地短路检测";
CM_ SG_ 1288 ESP_RRWheelSpdSensorFailure "后右轮速未知原因故障检测";
CM_ SG_ 1288 ESP_RLWheelSpdSensorSigFailure "后左轮速信号故障";
CM_ SG_ 1288 ESP_RLWheelSpdSensor_Open "后左轮速电源开路检测";
CM_ SG_ 1288 ESP_RLWheelSpdSensor_ShtBAT "后左轮速电源短路检测";
CM_ SG_ 1288 ESP_RLWheelSpdSensor_GND "后左轮速对地短路检测";
CM_ SG_ 1288 ESP_RLWheelSpdSensorFailure "后左轮速未知原因故障检测";
CM_ SG_ 1288 ESP_FRWheelSpdSensorSigFailure "前右轮速信号故障";
CM_ SG_ 1288 ESP_FRWheelSpdSensor_Open "前右轮速电源开路检测";
CM_ SG_ 1288 ESP_FRWheelSpdSensor_ShtBAT "前右轮速电源短路检测";
CM_ SG_ 1288 ESP_FRWheelSpdSensor_GND "前右轮速对地短路检测";
CM_ SG_ 1288 ESP_FRWheelSpdSensorFailure "前右轮速未知原因故障检测";
CM_ SG_ 1288 ESP_FLWheelSpdSensorSigFailure "前左轮速信号故障";
CM_ SG_ 1288 ESP_FLWheelSpdSensor_Open "前左轮速电源开路检测";
CM_ SG_ 1288 ESP_FLWheelSpdSensor_ShtBAT "前左轮速电源短路检测";
CM_ SG_ 1288 ESP_FLWheelSpdSensor_GND "前左轮速对地短路检测";
CM_ SG_ 1288 ESP_FLWheelSpdSensorFailure "前左轮速未知原因故障检测";
CM_ SG_ 1018 ESP_TPMSresetstatus "胎压复位状态";
CM_ SG_ 1018 ESP_TPMS_WarningStatus "胎压警告状态";
CM_ SG_ 1018 ESP_TPMS_MalfunctionStatus "胎压故障状态";
CM_ SG_ 1018 ESP_RearRghtWheelStatus "右后轮状态";
CM_ SG_ 1018 ESP_RearLeftWheelStatus "左后轮状态";
CM_ SG_ 1018 ESP_FrontRightWheelStatus "右前轮状态";
CM_ SG_ 1018 ESP_FrontLeftWheelStatus "左前轮状态";
CM_ SG_ 847 EPB_CRCCheck_34F "EPB校验和";
CM_ SG_ 847 EPB_RollingCounter_34F "EPB报文计数器";
CM_ SG_ 847 ESP_VGH_Available "VGH功能可用";
CM_ SG_ 847 ESP_VGH_Status "VGH功能激活状态";
CM_ SG_ 847 HDC_TextDisplay "HDC文本显示";
CM_ SG_ 847 AUTOHOLD_TextDisplay "AUTOHOLD文本显示";
CM_ SG_ 847 ESP_AVHStatusSet "AutoHold功能设置状态";
CM_ SG_ 847 ESP_HDC_StatusFeedback "HDC功能状态反馈";
CM_ SG_ 847 ESP_ATS_PtrotectMode "全地形系统保护模式";
CM_ SG_ 847 ESP_ATS_ATB_Failure "全地形系统开关故障";
CM_ SG_ 847 ESP_ATS_EPBi_Failure "全地形系统EPBi故障";
CM_ SG_ 847 ESP_ATS_AWD_Failure "全地形系统AWD故障";
CM_ SG_ 847 ESP_ATS_TCU_Failure "全地形系统TCU故障";
CM_ SG_ 847 ESP_ATS_EMS_Failure "全地形系统EMS故障";
CM_ SG_ 847 ESP_ATSReqRefuse "EPBi拒绝响应全地形请求";
CM_ SG_ 847 ESP_ATS_DriveMode_confirm "全地形系统驾驶模式确认";
CM_ SG_ 847 ESP_ATS_DriveModeRequest "全地形系统驾驶模式请求";
CM_ SG_ 847 EPB_TextDisplay "文本显示";
CM_ SG_ 847 EPB_AcousticWarning "声音报警";
CM_ SG_ 847 EPB_FunctionLamp "功能指示灯";
CM_ SG_ 847 EPB_FailureLamp "错误指示灯";
CM_ SG_ 632 ESP_CRCCheck_278 "ESP_278校验和";
CM_ SG_ 632 ESP_RollingCounter_278 "ESP_278计数器";
CM_ SG_ 632 ESP_YawRateValid "偏航率有效位";
CM_ SG_ 632 ESP_YawRate "偏航率";
CM_ SG_ 632 ESP_LongAccel "纵向加速度";
CM_ SG_ 632 ESP_LatAccel "横向加速度";
CM_ SG_ 632 ESP_TODTorqueMaxLimit "TOD扭矩最大值限制";
CM_ SG_ 632 ABS_TODFastOpenRequest "TOD快速打开请求";
CM_ SG_ 631 ESP_CRCCheck_277 "ESP_277校验和";
CM_ SG_ 631 ESP_RollingCounter_277 "ESP_277计数器";
CM_ SG_ 631 ESP_HBBFunctionStatus "HBB工作状态";
CM_ SG_ 631 ESP_LongAcceloffset "纵向加速度补偿值";
CM_ SG_ 631 ESP_LatAcceloffset "横向加速度补偿值";
CM_ SG_ 631 ESP_CDP_ParkingAvailForACC "CDP制动可用";
CM_ SG_ 631 ESP_CDP_ParkingActiveForACC "CDP制动激活";
CM_ SG_ 631 ESP_RWU_ParkingAvailForACC "RWU制动可用";
CM_ SG_ 631 ESP_RWU_ParkingActiveForACC "RWU制动激活";
CM_ SG_ 631 ESP_HBBActiveStatus "HBB激活状态";
CM_ SG_ 631 ESP_HDC_STATUS "HDC工作状态";
CM_ SG_ 631 ESP_IncreasePressureReqOK "响应APA主动建压完成";
CM_ SG_ 631 ESP_CDD_Available_APA "CDD(减速度控制)可用";
CM_ SG_ 631 ESP_CDD_Active_APA "CDD(减速度控制)激活";
CM_ SG_ 631 ESP_QDCACC "ESP检测到ACC发出的信息有错误（例如checksum,_alivecouner,timeout…)";
CM_ SG_ 631 ESP_OnlyABSActive "ABS激活";
CM_ SG_ 631 ESP_TCSActive "TCS激活";
CM_ SG_ 631 ESP_VDCActive "VDC激活";
CM_ SG_ 631 ESP_VehicleStandstill "车辆静止";
CM_ SG_ 631 ESP_CDD_Available "CDD(减速度控制)可用";
CM_ SG_ 631 ESP_CDD_Active "CDD(减速度控制)激活";
CM_ SG_ 631 ESP_BrakeOverHeatBrakeDiscTemp "制动盘过热";
CM_ SG_ 631 ESP_AWBavailable "AWB(自动警告制动)有效";
CM_ SG_ 631 ESP_AWBactive "AWB(自动警告制动)激活";
CM_ SG_ 631 ESP_AEBdecActive "AEB(自动紧急制动)激活";
CM_ SG_ 631 ESP_AEBAvailable "AEB(自动紧急制动)可用";
CM_ SG_ 631 ESP_PrefillAvailable "预制动有效";
CM_ SG_ 631 ESP_PrefillActive "预制动激活";
CM_ SG_ 631 ESP_ABAavailable "ABA(自动制动辅助)可用";
CM_ SG_ 631 ESP_ABAactive "ABA(自动制动辅助)激活";
CM_ SG_ 631 ESP_BrakeForce "制动系统压力";
CM_ SG_ 600 ESP_CRCCheck_258 "ESP_258校验和";
CM_ SG_ 600 ESP_RollingCounter_258 "ESP_258计数器";
CM_ SG_ 600 ESP_HHC_Active "HHC激活状态";
CM_ SG_ 600 ESP_HHC_Available "HHC功能可用";
CM_ SG_ 600 ESP_AutoHoldAvailable "AutoHold功能有效";
CM_ SG_ 600 ESP_AutoHoldActive "AutoHold功能状态";
CM_ SG_ 600 Wheel_Speed_RL_Pulse "左后轮速脉冲";
CM_ SG_ 600 Wheel_Speed_RR_Pulse "右后轮速脉冲";
CM_ SG_ 600 Wheel_Speed_FR_Pulse "右前轮速脉冲";
CM_ SG_ 600 Wheel_Speed_FL_Pulse "左前轮速脉冲";
CM_ SG_ 600 ESP_BrakeLightOnRequest "制动灯点亮请求";
CM_ SG_ 600 ESP_AutoHoldStandby "AutoHold功能待用状态";
CM_ SG_ 600 ESP_MasCylBrakePressure "制动主缸压力信号";
CM_ SG_ 520 ESP_CRCCheck_208 "ESP_208校验和";
CM_ SG_ 520 ESP_RollingCounter_208 "ESP_208计数器";
CM_ SG_ 520 ESP_ECDAvailable "ECD功能有效";
CM_ SG_ 520 ESP_ECDActive "ECD功能状态";
CM_ SG_ 520 ESP_UrgencyBrakeAlarm "紧急制动报警";
CM_ SG_ 520 ESP_YawRateoffset "横摆角速度补偿值";
CM_ SG_ 520 Wheel_Speed_RL_Data "左后轮速信号";
CM_ SG_ 520 Wheel_Speed_RL_Direction "左后轮方向信号";
CM_ SG_ 520 Wheel_Speed_RL_Valid_Data "左后轮速数据有效";
CM_ SG_ 520 Wheel_Speed_RR_Data "右后轮速信号";
CM_ SG_ 520 Wheel_Speed_RR_Direction "右后轮方向信号";
CM_ SG_ 520 Wheel_Speed_RR_Valid_Data "右后轮速数据有效";
CM_ SG_ 518 ESP_CRCCheck_206 "ESP_206校验和";
CM_ SG_ 518 ESP_RollingCounter_206 "ESP_206计数器";
CM_ SG_ 518 Wheel_Speed_FL_Data "左前轮速信号";
CM_ SG_ 518 Wheel_Speed_FL_Direction "左前轮方向信号";
CM_ SG_ 518 Wheel_Speed_FL_Valid_Data "左前轮速数据有效";
CM_ SG_ 518 Wheel_Speed_FR_Data "右前轮速信号";
CM_ SG_ 518 Wheel_Speed_FR_Direction "右前轮方向信号";
CM_ SG_ 518 Wheel_Speed_FR_Valid_Data "右前轮速数据有效";

BA_DEF_  "Baudrate" INT 0 1000000;
BA_DEF_  "SamplePoint" INT 50 100;
BA_DEF_  "SyncJumpWidth" INT 1 4;
BA_DEF_  "NBTNum" INT 8 25;
BA_DEF_  "Manufacturer" STRING ;
BA_DEF_ BO_  "GenMsgILSupport" ENUM  "No","Yes";
BA_DEF_ SG_  "GenSigSendType" ENUM  "Cyclic","OnWrite","OnWriteWithRepetition","OnChange","OnChangeWithRepetition","NotUsed","NotUsed","NoSigSendType";

BA_DEF_ SG_  "GenSigEnvVarType" ENUM  "int","float","undef";
BA_DEF_ BO_ "NmMessage" ENUM "No","Yes";
BA_DEF_ BO_  "GenMsgCycleTime" INT 0 65535;
BA_DEF_ BO_  "GenMsgSendType" ENUM  "cyclic","event","spontaneous","cyclicIOnEvent","spontaneousWithDelay","cyclicAndEvent","cyclicAndSpontaneousWithDelay","spontaneousWithRepetition","cyclicIfActiveAndSpontaneousWD","FixedPeriodic";
BA_DEF_ BU_ "NmStationAddress"  HEX 0 127;
BA_DEF_  "BusType" STRING ;
BA_DEF_  "GenEnvVarPrefix" STRING ;
BA_DEF_  "GenEnvVarEndingSnd" STRING ;
BA_DEF_  "GenEnvVarEndingDsp" STRING ;
BA_DEF_  "DBName" STRING ;
BA_DEF_DEF_  "Baudrate" 500000;
BA_DEF_DEF_  "SamplePoint" 80;
BA_DEF_DEF_  "SyncJumpWidth" 4;
BA_DEF_DEF_  "NBTNum" 20;
BA_DEF_DEF_  "Manufacturer" "NeuSAR";
BA_DEF_DEF_  "GenMsgILSupport" "Yes";
BA_DEF_DEF_  "GenSigSendType" "Cyclic";
BA_DEF_DEF_ "NmStationAddress" 0;
BA_DEF_DEF_ "NmMessage" "Yes";

BA_DEF_DEF_  "GenSigEnvVarType" "undef";
BA_DEF_DEF_  "GenMsgCycleTime" 2;
BA_DEF_DEF_  "GenMsgSendType" "cyclic";
BA_DEF_DEF_  "BusType" "CAN";
BA_DEF_DEF_  "GenEnvVarPrefix" "PE";
BA_DEF_DEF_  "GenEnvVarEndingSnd" "_Ps";
BA_DEF_DEF_  "GenEnvVarEndingDsp" "_Pd";
BA_DEF_DEF_  "DBName" "";
BA_ "NmStationAddress" BU_ BDCR 1034;
BA_ "NmStationAddress" BU_ THU 1041;
BA_ "NmStationAddress" BU_ FIS 1036;
BA_ "NmStationAddress" BU_ ESCL 1026;
BA_ "NmStationAddress" BU_ IP 1025;
BA_ "NmStationAddress" BU_ BDCF 1024;
BA_ "DBName" "BCAN";
BA_ "GenMsgCycleTime" BO_ 1476 0;
BA_ "GenMsgCycleTime" BO_ 1494 0;
BA_ "GenMsgCycleTime" BO_ 1320 500;
BA_ "GenMsgCycleTime" BO_ 1302 500;
BA_ "GenMsgCycleTime" BO_ 1383 500;
BA_ "GenMsgCycleTime" BO_ 1329 0;
BA_ "GenMsgCycleTime" BO_ 1034 0;
BA_ "GenMsgCycleTime" BO_ 1041 0;
BA_ "GenMsgCycleTime" BO_ 1036 0;
BA_ "GenMsgCycleTime" BO_ 1026 0;
BA_ "GenMsgCycleTime" BO_ 1025 0;
BA_ "GenMsgCycleTime" BO_ 1024 0;
BA_ "GenMsgCycleTime" BO_ 973 100;
BA_ "GenMsgCycleTime" BO_ 971 100;
BA_ "GenMsgCycleTime" BO_ 970 100;
BA_ "GenMsgCycleTime" BO_ 768 50;
BA_ "GenMsgCycleTime" BO_ 759 50;
BA_ "GenMsgCycleTime" BO_ 751 50;
BA_ "GenMsgCycleTime" BO_ 687 50;
BA_ "GenMsgCycleTime" BO_ 686 50;
BA_ "GenMsgCycleTime" BO_ 684 50;
BA_ "GenMsgCycleTime" BO_ 1771 500;
BA_ "GenMsgCycleTime" BO_ 906 100;
BA_ "GenMsgCycleTime" BO_ 951 100;
BA_ "GenMsgCycleTime" BO_ 1760 0;
BA_ "GenMsgCycleTime" BO_ 932 100;
BA_ "GenMsgCycleTime" BO_ 954 100;
BA_ "GenMsgCycleTime" BO_ 679 100;
BA_ "GenMsgCycleTime" BO_ 1295 200;
BA_ "GenMsgCycleTime" BO_ 682 40;
BA_ "GenMsgCycleTime" BO_ 678 100;
BA_ "GenMsgCycleTime" BO_ 765 100;
BA_ "GenMsgCycleTime" BO_ 767 100;
BA_ "GenMsgCycleTime" BO_ 766 40;
BA_ "GenMsgCycleTime" BO_ 620 50;
BA_ "GenMsgCycleTime" BO_ 621 50;
BA_ "GenMsgCycleTime" BO_ 724 40;
BA_ "GenMsgCycleTime" BO_ 725 40;
BA_ "GenMsgCycleTime" BO_ 612 100;
BA_ "GenMsgCycleTime" BO_ 983 100;
BA_ "GenMsgCycleTime" BO_ 861 100;
BA_ "GenMsgCycleTime" BO_ 860 100;
BA_ "GenMsgCycleTime" BO_ 968 100;
BA_ "GenMsgCycleTime" BO_ 781 100;
BA_ "GenMsgCycleTime" BO_ 871 100;
BA_ "GenMsgCycleTime" BO_ 778 100;
BA_ "GenMsgCycleTime" BO_ 877 100;
BA_ "GenMsgCycleTime" BO_ 998 100;
BA_ "GenMsgCycleTime" BO_ 996 100;
BA_ "GenMsgCycleTime" BO_ 863 100;
BA_ "GenMsgCycleTime" BO_ 862 100;
BA_ "GenMsgCycleTime" BO_ 836 100;
BA_ "GenMsgCycleTime" BO_ 802 100;
BA_ "GenMsgCycleTime" BO_ 606 100;
BA_ "GenMsgCycleTime" BO_ 590 100;
BA_ "GenMsgCycleTime" BO_ 448 100;
BA_ "GenMsgCycleTime" BO_ 980 100;
BA_ "GenMsgCycleTime" BO_ 818 100;
BA_ "GenMsgCycleTime" BO_ 893 100;
BA_ "GenMsgCycleTime" BO_ 960 100;
BA_ "GenMsgCycleTime" BO_ 856 100;
BA_ "GenMsgCycleTime" BO_ 834 100;
BA_ "GenMsgCycleTime" BO_ 1534 500;
BA_ "GenMsgCycleTime" BO_ 801 100;
BA_ "GenMsgCycleTime" BO_ 1014 200;
BA_ "GenMsgCycleTime" BO_ 950 100;
BA_ "GenMsgCycleTime" BO_ 584 100;
BA_ "GenMsgCycleTime" BO_ 846 100;
BA_ "GenMsgCycleTime" BO_ 80 500;
BA_ "GenMsgCycleTime" BO_ 1288 200;
BA_ "GenMsgCycleTime" BO_ 1018 100;
BA_ "GenMsgCycleTime" BO_ 847 100;
BA_ "GenMsgCycleTime" BO_ 632 100;
BA_ "GenMsgCycleTime" BO_ 631 100;
BA_ "GenMsgCycleTime" BO_ 600 100;
BA_ "GenMsgCycleTime" BO_ 520 100;
BA_ "GenMsgCycleTime" BO_ 518 100;
BA_ "NmMessage" BO_ 1476 0;
BA_ "NmMessage" BO_ 1494 0;
BA_ "NmMessage" BO_ 1320 0;
BA_ "NmMessage" BO_ 1302 0;
BA_ "NmMessage" BO_ 1383 0;
BA_ "NmMessage" BO_ 1329 0;
BA_ "NmMessage" BO_ 973 0;
BA_ "NmMessage" BO_ 971 0;
BA_ "NmMessage" BO_ 970 0;
BA_ "NmMessage" BO_ 768 0;
BA_ "NmMessage" BO_ 759 0;
BA_ "NmMessage" BO_ 751 0;
BA_ "NmMessage" BO_ 687 0;
BA_ "NmMessage" BO_ 686 0;
BA_ "NmMessage" BO_ 684 0;
BA_ "NmMessage" BO_ 1771 0;
BA_ "NmMessage" BO_ 906 0;
BA_ "NmMessage" BO_ 951 0;
BA_ "NmMessage" BO_ 1760 0;
BA_ "NmMessage" BO_ 932 0;
BA_ "NmMessage" BO_ 954 0;
BA_ "NmMessage" BO_ 679 0;
BA_ "NmMessage" BO_ 1295 0;
BA_ "NmMessage" BO_ 682 0;
BA_ "NmMessage" BO_ 678 0;
BA_ "NmMessage" BO_ 765 0;
BA_ "NmMessage" BO_ 767 0;
BA_ "NmMessage" BO_ 766 0;
BA_ "NmMessage" BO_ 620 0;
BA_ "NmMessage" BO_ 621 0;
BA_ "NmMessage" BO_ 724 0;
BA_ "NmMessage" BO_ 725 0;
BA_ "NmMessage" BO_ 612 0;
BA_ "NmMessage" BO_ 983 0;
BA_ "NmMessage" BO_ 861 0;
BA_ "NmMessage" BO_ 860 0;
BA_ "NmMessage" BO_ 968 0;
BA_ "NmMessage" BO_ 781 0;
BA_ "NmMessage" BO_ 871 0;
BA_ "NmMessage" BO_ 778 0;
BA_ "NmMessage" BO_ 877 0;
BA_ "NmMessage" BO_ 998 0;
BA_ "NmMessage" BO_ 996 0;
BA_ "NmMessage" BO_ 863 0;
BA_ "NmMessage" BO_ 862 0;
BA_ "NmMessage" BO_ 836 0;
BA_ "NmMessage" BO_ 802 0;
BA_ "NmMessage" BO_ 606 0;
BA_ "NmMessage" BO_ 590 0;
BA_ "NmMessage" BO_ 448 0;
BA_ "NmMessage" BO_ 980 0;
BA_ "NmMessage" BO_ 818 0;
BA_ "NmMessage" BO_ 893 0;
BA_ "NmMessage" BO_ 960 0;
BA_ "NmMessage" BO_ 856 0;
BA_ "NmMessage" BO_ 834 0;
BA_ "NmMessage" BO_ 1534 0;
BA_ "NmMessage" BO_ 801 0;
BA_ "NmMessage" BO_ 1014 0;
BA_ "NmMessage" BO_ 950 0;
BA_ "NmMessage" BO_ 584 0;
BA_ "NmMessage" BO_ 846 0;
BA_ "NmMessage" BO_ 80 0;
BA_ "NmMessage" BO_ 1288 0;
BA_ "NmMessage" BO_ 1018 0;
BA_ "NmMessage" BO_ 847 0;
BA_ "NmMessage" BO_ 632 0;
BA_ "NmMessage" BO_ 631 0;
BA_ "NmMessage" BO_ 600 0;
BA_ "NmMessage" BO_ 520 0;
BA_ "NmMessage" BO_ 518 0;
BA_ "GenMsgSendType" BO_ 1476 1;
BA_ "GenMsgSendType" BO_ 1494 1;
BA_ "GenMsgSendType" BO_ 1329 1;
BA_ "GenMsgSendType" BO_ 1034 1;
BA_ "GenMsgSendType" BO_ 1041 1;
BA_ "GenMsgSendType" BO_ 1036 1;
BA_ "GenMsgSendType" BO_ 1026 1;
BA_ "GenMsgSendType" BO_ 1025 1;
BA_ "GenMsgSendType" BO_ 1024 1;
BA_ "GenMsgSendType" BO_ 1760 1;
BA_ "GenMsgSendType" BO_ 80 5;
VAL_ 1320 RemoteParking_payment_activation_status 1 "功能无效 " 1 "功能支持 " 2 "功能激活 " 3 "功能保持（预留） " ;
VAL_ 1320 group_number 0 "代表第0组车型编号 " 1 "代表第1组车型编号 " ;
VAL_ 1302 BSD_payment_activation_status 1 "功能无效 " 1 "功能支持 " 2 "功能激活 " 3 "功能保持（预留） " ;
VAL_ 1302 group_number 0 "代表第0组车型编号 " 1 "代表第1组车型编号 " ;
VAL_ 1383 group_number 0 "代表第0组车型编号 " 1 "代表第1组车型编号 " ;
VAL_ 1329 HU_CAMReplayModeStatus 0 "norequest " 1 "enterpicturemodebrowse " 2 "entervideomodebrowse " 3 "Reserved " 4 "Reserved " 5 "Reserved " 6 "Reserved " 7 "Reserved " ;
VAL_ 1329 HU_CAMRecordControl 0 "inactive " 1 "RecStartReq " 2 "RecStopReq " 3 "Invalid " ;
VAL_ 1329 HU_CAMShootControl 0 "inactive " 1 "ShootReq " 2 "Reserved " 3 "Invalid " ;
VAL_ 1329 HU_CAMDisplayVision 0 "norequest " 1 "front " 2 "rear " 3 "left " 4 "right " 5 "all " 6 "reserved " 7 "invalid " ;
VAL_ 1329 HU_CAMMode 0 "Inactive " 1 "RealTimeMode " 2 "ReplayMode " 3 "SettingMode " ;
VAL_ 1034 BDCR_PTSStillOver10MinStatus 0 "有 " 1 "无 " ;
VAL_ 1034 BDCR_SCMSwitchWakeUp 0 "no " 1 "yes " ;
VAL_ 1034 BDCR_KeyRemoteOpenSCMWakeUp 0 "no " 1 "yes " ;
VAL_ 1034 BDCR_KickWakeUp 0 "no " 1 "yes " ;
VAL_ 1034 BDCR_PTSSwitchWakeUp 0 "no " 1 "yes " ;
VAL_ 1034 BDCR_KeyRemoteOpenPTSWakeUp 0 "no " 1 "yes " ;
VAL_ 1034 BDCR_CanBusStatus 0 "无总线活动 " 1 "有总线活动 " ;
VAL_ 1034 BDCR_PowerStatus 0 "OFF档 " 1 "非OFF档 " ;
VAL_ 1034 BDCR_BusMessageWakeUpMold 0 "no " 1 "BCan " 2 "PCan " 3 "TCan " 4 "DCan " 5 "LIN " 6 "reserved " 7 "reserved " ;
VAL_ 1034 BDCR_BusMessageWakeUp 0 "no " 1 "yes " ;
VAL_ 1034 BDCR_PowerDistributionStatus 0 "no " 1 "yes " ;
VAL_ 1034 BDCR_NMSleepAcknowledge 0 "Inactive " 1 "Active " ;
VAL_ 1034 BDCR_NMSleepIndication 0 "Inactive " 1 "Active " ;
VAL_ 1034 BDCR_NMLimphome 0 "Inactive " 1 "Active " ;
VAL_ 1034 BDCR_NMRing 0 "Inactive " 1 "Active " ;
VAL_ 1034 BDCR_NMAlive 0 "Inactive " 1 "Active " ;
VAL_ 1041 HU_G_sensorWakeup 1 "yes " ;
VAL_ 1041 NM_Segment 0 "BodyCan网络管理报文 " 1 "TBoxCan网络管理报文 " ;
VAL_ 1041 HU_CanBusStatus 0 "无总线活动 " 1 "有总线活动 " ;
VAL_ 1041 HU_PowerDown10Min 0 "是 " 1 "否 " ;
VAL_ 1041 HU_RemoteLocksignal 0 "是 " 1 "否 " ;
VAL_ 1041 HU_PowerStatus 0 "OFF档 " 1 "非OFF档 " ;
VAL_ 1041 HU_TBOX_RemoteWakeup 1 "yes " ;
VAL_ 1041 HU_TBOX_ECALLRequestSwitch 1 "yes " ;
VAL_ 1041 HU_Chip 1 "yes " ;
VAL_ 1041 HU_BusMessageWakeUpMold 0 "no " 1 "BCan " 2 "PCan " 3 "TCan " 4 "DCan " 5 "LIN " 6 "reserved " 7 "reserved " ;
VAL_ 1041 HU_BusMessageWakeUp 0 "no " 1 "yes " ;
VAL_ 1041 HU_PowerDistributionStatus 0 "no " 1 "yes " ;
VAL_ 1041 HU_NMSleepAcknowledge 0 "Inactive " 1 "Active " ;
VAL_ 1041 HU_NMSleepIndication 0 "Inactive " 1 "Active " ;
VAL_ 1041 HU_NMLimphome 0 "Inactive " 1 "Active " ;
VAL_ 1041 HU_NMRing 0 "Inactive " 1 "Active " ;
VAL_ 1041 HU_NMAlive 0 "Inactive " 1 "Active " ;
VAL_ 1036 FIS_CanBusStatus 0 "无总线活动 " 1 "有总线活动 " ;
VAL_ 1036 FIS_PowerStatus 0 "OFF档 " 1 "非OFF档 " ;
VAL_ 1036 FIS_BusMessageWakeUpMold 0 "no " 1 "BCan " 2 "PCan " 3 "TCan " 4 "DCan " 5 "LIN " 6 "reserved " 7 "reserved " ;
VAL_ 1036 FIS_BusMessageWakeUp 0 "no " 1 "yes " ;
VAL_ 1036 FIS_PowerDistributionStatus 0 "no " 1 "yes " ;
VAL_ 1036 FIS_NMSleepAcknowledge 0 "Inactive " 1 "Active " ;
VAL_ 1036 FIS_NMSleepIndication 0 "Inactive " 1 "Active " ;
VAL_ 1036 FIS_NMLimphome 0 "Inactive " 1 "Active " ;
VAL_ 1036 FIS_NMRing 0 "Inactive " 1 "Active " ;
VAL_ 1036 FIS_NMAlive 0 "Inactive " 1 "Active " ;
VAL_ 1026 ESCL_VehicleSpeed 0 "是 " 1 "否 " ;
VAL_ 1026 ESCL_CanBusStatus 0 "无总线活动 " 1 "有总线活动 " ;
VAL_ 1026 ESCL_PowerStatus 0 "OFF档 " 1 "非OFF档 " ;
VAL_ 1026 ESCL_BusMessageWakeUpMold 0 "no " 1 "BCan " 2 "PCan " 3 "TCan " 4 "DCan " 5 "LIN " 6 "reserved " 7 "reserved " ;
VAL_ 1026 ESCL_BusMessageWakeUp 0 "no " 1 "yes " ;
VAL_ 1026 ESCL_PowerDistributionStatus 0 "no " 1 "yes " ;
VAL_ 1026 ESCL_NMSleepAcknowledge 0 "Inactive " 1 "Active " ;
VAL_ 1026 ESCL_NMSleepIndication 0 "Inactive " 1 "Active " ;
VAL_ 1026 ESCL_NMLimphome 0 "Inactive " 1 "Active " ;
VAL_ 1026 ESCL_NMRing 0 "Inactive " 1 "Active " ;
VAL_ 1026 ESCL_NMAlive 0 "Inactive " 1 "Active " ;
VAL_ 1025 IP_CanBusStatus 0 "无总线活动 " 1 "有总线活动 " ;
VAL_ 1025 IP_PowerStatus 0 "OFF档 " 1 "非OFF档 " ;
VAL_ 1025 IP_BusMessageWakeUpMold 0 "no " 1 "BCan " 2 "PCan " 3 "TCan " 4 "DCan " 5 "LIN " 6 "reserved " 7 "reserved " ;
VAL_ 1025 IP_BusMessageWakeUp 0 "no " 1 "yes " ;
VAL_ 1025 IP_PowerDistributionStatus 0 "no " 1 "yes " ;
VAL_ 1025 IP_NMSleepAcknowledge 0 "Inactive " 1 "Active " ;
VAL_ 1025 IP_NMSleepIndication 0 "Inactive " 1 "Active " ;
VAL_ 1025 IP_NMLimphome 0 "Inactive " 1 "Active " ;
VAL_ 1025 IP_NMRing 0 "Inactive " 1 "Active " ;
VAL_ 1025 IP_NMAlive 0 "Inactive " 1 "Active " ;
VAL_ 1024 BDCF_DSMSleepStatus 0 "是 " 1 "否 " ;
VAL_ 1024 BDCF_DSMLocalSwitchWakeUp 0 "no " 1 "yes " ;
VAL_ 1024 BDCF_RemoteSignalStatus 0 "无 " 1 "有 " ;
VAL_ 1024 BDCF_BrakePedalStatus 0 "未踩下 " 1 "y踩下 " ;
VAL_ 1024 BDCF_PowerSaveModeStatus 0 "已到期 " 1 "未到期 " ;
VAL_ 1024 BDCF_lockPerformStatus 0 "已执行完 " 1 "未执行完 " ;
VAL_ 1024 BDCF_UnlockPerformStatus 0 "已执行完 " 1 "未执行完 " ;
VAL_ 1024 BDCF_TurnLightSwitchStatus 0 "关闭 " 1 "开启 " ;
VAL_ 1024 BDCF_LinBusStatus 0 "无总线活动 " 1 "有总线活动 " ;
VAL_ 1024 BDCF_CanBusStatus 0 "无总线活动 " 1 "有总线活动 " ;
VAL_ 1024 BDCF_FollowMeHomeStatus 0 "已执行完 " 1 "未执行完 " ;
VAL_ 1024 BDCF_TrunkButtonStatus 0 "未按下 " 1 "按下 " ;
VAL_ 1024 BDCF_DriverDoorHandleButtonStatus 0 "未按下 " 1 "按下 " ;
VAL_ 1024 BDCF_ALLDoorStatus 0 "全部关闭 " 1 "未全部关闭 " ;
VAL_ 1024 BDCF_SecondAntiTheftStatus 0 "已执行完 " 1 "未执行完 " ;
VAL_ 1024 BDCF_PositionLampStatus 0 "关闭 " 1 "开启 " ;
VAL_ 1024 BDCF_PowerStatus 0 "OFF档 " 1 "非OFF档 " ;
VAL_ 1024 BDCF_GreetWakeUp 0 "no " 1 "yes " ;
VAL_ 1024 BDCF_BrakePedalWakeUp 0 "no " 1 "yes " ;
VAL_ 1024 BDCF_DoorHandleButtonSignalWakeUp 0 "no " 1 "yes " ;
VAL_ 1024 BDCF_StartupButtonSignalWakeUp 0 "no " 1 "yes " ;
VAL_ 1024 BDCF_OverTakeLightSwitchWakeUp 0 "no " 1 "yes " ;
VAL_ 1024 BDCF_Easy_openWakeUp 0 "no " 1 "yes " ;
VAL_ 1024 BDCF_TrunkSwitchCommandWakeUp 0 "no " 1 "yes " ;
VAL_ 1024 BDCF_KeyRemoteSignalWakeUp 0 "no " 1 "UnLockdoor " 2 "Lockdoor " 3 "UnLockLuggage " 4 "SearchCar " 5 "RemoteStart " 6 "reserved " 7 "reserved " ;
VAL_ 1024 BDCF_DriverDoorUnlockorLockStatusWakeUp 0 "no " 1 "yes " ;
VAL_ 1024 BDCF_CentralUnlockorLockControlSignalWakeUp 0 "no " 1 "yes " ;
VAL_ 1024 BDCF_DriverDoorStatusWakeUp 0 "no " 1 "yes " ;
VAL_ 1024 BDCF_PassengerDoorStatusWakeUp 0 "no " 1 "yes " ;
VAL_ 1024 BDCF_LeftRearDoorStatusWakeUp 0 "no " 1 "yes " ;
VAL_ 1024 BDCF_RightRearDoorStatusWakeUp 0 "no " 1 "yes " ;
VAL_ 1024 BDCF_TrunkStatusWakeUp 0 "no " 1 "yes " ;
VAL_ 1024 BDCF_HoodStatusWakeUp 0 "no " 1 "yes " ;
VAL_ 1024 BDCF_EmergencyLightSwitchWakeUp 0 "no " 1 "yes " ;
VAL_ 1024 BDCF_PositionLampSwitchWakeUp 0 "no " 1 "yes " ;
VAL_ 1024 BDCF_BusMessageWakeUpMold 0 "no " 1 "BCan " 2 "PCan " 3 "TCan " 4 "DCan " 5 "LIN " 6 "reserved " 7 "reserved " ;
VAL_ 1024 BDCF_BusMessageWakeUp 0 "no " 1 "yes " ;
VAL_ 1024 BDCF_PowerDistributionStatus 0 "no " 1 "yes " ;
VAL_ 1024 BDCF_NMSleepAcknowledge 0 "Inactive " 1 "Active " ;
VAL_ 1024 BDCF_NMSleepIndication 0 "Inactive " 1 "Active " ;
VAL_ 1024 BDCF_NMLimphome 0 "Inactive " 1 "Active " ;
VAL_ 1024 BDCF_NMRing 0 "Inactive " 1 "Active " ;
VAL_ 1024 BDCF_NMAlive 0 "Inactive " 1 "Active " ;
VAL_ 973 ADS_TunnelStatus 0 "nodisplay " 1 "nearTunnel " 2 "inTunnel " 3 "reserved " ;
VAL_ 973 ADS_PathThroughRamp 0 "notThroughRamp " 1 "throughRamp " 2 "invalid " 3 "reserved " ;
VAL_ 971 ADS_RampSide 0 "invalid " 1 "onRightSide " 2 "onLeftSide " 3 "reserved " ;
VAL_ 971 ADS_EOMTOReq 0 "无请求 " 1 "1级接管请求 " 2 "2级接管请求 " 3 "3级接管请求 " ;
VAL_ 971 ADS_AutoDriveStateDisplay 0 "nodisplay " 1 "ACC " 2 "IACC " 3 "HWA " 4 "TJP " 5 "共驾 " 6 "1级提醒报警 " 7 "2级提醒报警 " 8 "3级提醒报警 " 9 "4级提醒报警 " 10 "1级立即接管报警 " 11 "2级立即接管报警 " 12 "3级立即接管报警 " ;
VAL_ 970 ADS_PathShow_Status 0 "nodisplay " 1 "LaneChangeTryPath换道等待 " 2 "NormalLaneChangePath换道过程 " 3 "LaneChangeReturnPath换道回退 " 4 "CanNotChangeLanePath换道等待或保持本车道行驶 " 5 "SmartBiasPath智慧偏移路径 " 6 "FollowVehicleDrivePath跟车行驶路径 " 7 "RecommendPath推荐路径 " ;
VAL_ 687 ADS_LCDAR_Left_LCAAlertForELK 0 "nowarning " 1 "Level1 " 2 "notused " 3 "Level2 " ;
VAL_ 687 LCDAR_ELK_oAlert 0 "Nowarning " 1 "level1 " 2 "level2 " 3 "Reserved " ;
VAL_ 687 LCDAR_ELK_oStatus 0 "OFF关闭（预留） " 1 "Inactive未激活 " 2 "Active " 3 "Failure " ;
VAL_ 687 LCDAR_Left_ELK_oAlert 0 "Nowarning " 1 "level1 " 2 "level2 " 3 "Reserved " ;
VAL_ 687 LCDAR_RCTAStatus 0 "OFF关闭 " 1 "Inactive未激活 " 2 "Active " 3 "Failure " ;
VAL_ 687 LCDAR_RCTBStatus 0 "OFF关闭 " 1 "Inactive未激活 " 2 "Active " 3 "Failure " ;
VAL_ 687 LCDAR_RCTBEnable 0 "off " 1 "on " ;
VAL_ 687 LCDAR_RCTBActive 0 "notActive " 1 "Active " ;
VAL_ 687 LCDAR_RCTAAlert 0 "NoRCTAwarning " 1 "RCTAwarningLevel1 " 2 "RCTAwarningLevel2 " 3 "RCTAwarningLevel3 " ;
VAL_ 687 LCDAR_BSD_LCAStatus 0 "OFF关闭 " 1 "Inactive未激活 " 2 "Active " 3 "Failure " ;
VAL_ 687 LCDAR_BSD_LCAAlert 0 "NoLCAwarning " 1 "LCAwarninglevel1 " 2 "LCAwarninglevel2 " 3 "Reserved " ;
VAL_ 687 LCDAR_SystemStatus 0 "Reserved " 1 "StartUp " 2 "Running " 3 "Blocked " 4 "Calibration " 5 "ShutDown " 6 "Hot " 7 "Failure " ;
VAL_ 687 LCDAR_RCTAEnableStatus 0 "Off " 1 "On " ;
VAL_ 687 LCDAR_Left_RCTAAlert 0 "NoRCTAwarning " 1 "RCTAwarningLevel1 " 2 "RCTAwarningLevel2 " 3 "RCTAwarningLevel3 " ;
VAL_ 687 LCDAR_Left_BSD_LCAAlert 0 "NoLCAwarning " 1 "LCAwarninglevel1 " 2 "LCAwarninglevel2 " 3 "Reserved " ;
VAL_ 687 LCDAR_BSD_LCAEnableStatus 0 "early " 1 "normal（初始值） " 2 "late " 3 "Off " ;
VAL_ 686 LCDAL_AudioWarningEnableStatus 0 "Off " 1 "On " ;
VAL_ 686 LCDAL_SEAStatus 0 "OFF关闭 " 1 "Inactive未激活 " 2 "Active " 3 "Failure " ;
VAL_ 686 LCDAL_SEAAlert 0 "NoSEAwarning " 1 "SEAwarninglevel1 " 2 "SEAExit " 3 "SEAwarninglevel2 " ;
VAL_ 686 LCDAL_SEAEnableStatus 0 "Off " 1 "On " ;
VAL_ 686 LCDAL_Right_SEAAlert 0 "NoSEAwarning " 1 "SEAwarninglevel1 " 2 "SEAExit " 3 "SEAwarninglevel2 " ;
VAL_ 686 LCDAL_RCWStatus 0 "OFF关闭 " 1 "Inactive未激活 " 2 "Active " 3 "Failure " ;
VAL_ 686 LCDAL_RCWAlert 0 "NoRCWwarning " 1 "RCWwarninglevel1 " 2 "RCWwarninglevel2 " 3 "RCWwarninglevel3 " ;
VAL_ 686 LCDAL_RCWEnableStatus 0 "Off " 1 "On " ;
VAL_ 686 LCDAL_Right_RCWAlert 0 "NoRCWwarning " 1 "RCWwarninglevel1 " 2 "RCWwarninglevel2 " 3 "RCWwarninglevel3 " ;
VAL_ 686 LCDAL_SystemStatus 0 "Reserved " 1 "StartUp " 2 "Running " 3 "Blocked " 4 "Calibration " 5 "ShutDown " 6 "Hot " 7 "Failure " ;
VAL_ 684 ADS_FRC_FCTAEnable 0 "off " 1 "on " ;
VAL_ 684 ADS_FRC_FCTBStatus 0 "OFF关闭 " 1 "Inactive未激活 " 2 "Active " 3 "Failure " ;
VAL_ 684 ADS_FLC_SystemStatus 0 "Reserved " 1 "StartUp " 2 "Running " 3 "Blocked " 4 "Calibration " 5 "ShutDown " 6 "Hot " 7 "Failure " ;
VAL_ 684 ADS_FRC_FCTARStatus 0 "OFF关闭 " 1 "Inactive未激活 " 2 "Active " 3 "Failure " ;
VAL_ 684 ADS_FRC_Right_FCTARAlert 0 "NoFCTAwarning " 1 "FCTAwarningLevel1 " 2 "FCTAwarningLevel2 " 3 "FCTAwarningLevel3 " ;
VAL_ 684 ADS_FRC_Left_FCTALAlert 0 "NoFCTAwarning " 1 "FCTAwarningLevel1 " 2 "FCTAwarningLevel2 " 3 "FCTAwarningLevel3 " ;
VAL_ 684 ADS_FRC_FCTBActive 0 "notActive " 1 "Active " ;
VAL_ 684 ADS_FRC_FCTBEnable 0 "off " 1 "on " ;
VAL_ 1771 GW_FBLRemoteSts 0 "notactive " 1 "正在远程启动状态 " ;
VAL_ 1771 GW_FBLVehicleChargeSts 0 "notactive " 1 "车辆正在充电 " ;
VAL_ 1771 GW_FBLExceedSts 0 "notactive " 1 "当前已在刷写 " ;
VAL_ 1771 GW_FBLTempSts 0 "notactive " 1 "温度不满足 " ;
VAL_ 1771 GW_FBLhandbreakSts 0 "notactive " 1 "手刹非拉起状态 " ;
VAL_ 1771 GW_InstallReqFeedbackShiftSts 0 "notactive " 1 "换挡器非P档 " ;
VAL_ 1771 GW_VehicleSpeedSts 0 "notactive " 1 "车速非零（＞3KM/h） " ;
VAL_ 1771 GW_InstallReqFeedback_BatterySts 0 "notactive " 1 "蓄电池剩余电量不满足刷写 " ;
VAL_ 1771 GW_InstallReqFeedback_PowerSts 0 "notactive " 1 "整车电源状态非OFF档 " ;
VAL_ 1771 GW_InstallReqFeedback 0 "inactive " 1 "刷写请求成功 " 2 "请求超时 " 3 "请求失败 " ;
VAL_ 906 HU_Thridscreen_switch 0 "未激活 " 1 "短按 " 2 "长按 " 3 "无效 " ;
VAL_ 906 HU_APA_OnOff_switch 0 "未激活 " 1 "短按 " 2 "长按 " 3 "无效 " ;
VAL_ 906 HU_CloudCamera 0 "未激活 " 1 "短按 " 2 "长按 " 3 "无效 " ;
VAL_ 906 HU_FIS_AVM_switch 0 "按键未按下 " 1 "按键按下 " 2 "假按键 " 3 "长按 " ;
VAL_ 906 HU_FIS_SeekPlus_switch 0 "按键未按下 " 1 "按键按下 " 2 "假按键 " 3 "Error " ;
VAL_ 906 HU_FIS_SeekReduce_switch 0 "按键未按下 " 1 "按键按下 " 2 "假按键 " 3 "Error " ;
VAL_ 906 HU_FIS_Hungup_switch_signal 0 "按键未按下 " 1 "按键按下 " 2 "假按键 " 3 "Error " ;
VAL_ 906 HU_FIS_Answer_switch_signal 0 "按键未按下 " 1 "按键按下 " 2 "假按键 " 3 "Error " ;
VAL_ 906 HU_FIS_VolPlus_switch 0 "按键未按下 " 1 "按键按下 " 2 "假按键 " 3 "Error " ;
VAL_ 906 HU_FIS_VolReduce_switch 0 "按键未按下 " 1 "按键按下 " 2 "假按键 " 3 "Error " ;
VAL_ 906 HU_FIS_Mute_switch 0 "按键未按下 " 1 "按键按下 " 2 "假按键 " 3 "Error " ;
VAL_ 906 HU_FIS_Speech_switch 0 "按键未按下 " 1 "按键按下 " 2 "假按键 " 3 "Error " ;
VAL_ 906 HU_FIS_Mode_switch 0 "按键未按下 " 1 "按键按下 " 2 "假按键 " 3 "Error " ;
VAL_ 951 CAM_RecordStatus 0 "invalid " 1 "Unsuccessful " 2 "Success " 3 "Recording " ;
VAL_ 951 CAM_CAMReplayModeStatus 0 "norequest " 1 "picturemodebrowse " 2 "videomodebrowse " 3 "Reserved " 4 "Reserved " 5 "picturemodereplay " 6 "videomodereplay " 7 "Reserved " ;
VAL_ 951 CAM_PhotographResult 0 "invalid " 1 "success " 2 "fail " 3 "Reserved " ;
VAL_ 951 CAM_DisplayVision 0 "norequest " 1 "front " 2 "rear " 3 "left " 4 "right " 5 "all " 6 "reserved " 7 "invalid " ;
VAL_ 951 CAM_CAMModeFeedback 0 "Inactive " 1 "RealTimeMode " 2 "ReplayMode " 3 "SettingMode " ;
VAL_ 951 AVM_LicenseNumberSetStatus 0 "Inactive " 1 "success " 2 "fail " 3 "Reserved " ;
VAL_ 951 AVM_BodyColourSetStatus 0 "Inactive " 1 "colour1 " 2 "colour2 " 3 "colour3 " 4 "colour4 " 5 "colour5 " 6 "colour6 " 7 "colour7 " 8 "colour8 " 9 "colour9 " 10 "colour10 " 11 "colour11 " 12 "colour12 " 13 "colour13 " 14 "colour14 " 15 "Reserved " ;
VAL_ 951 AVM_AVMDVRReplayModeStatus 0 "norequest " 1 "cyclemodebrowse " 2 "emergencymodebrowse " 3 "photomodebrowse " 4 "DASmodebrowse " 5 "Reserved " 6 "Reserved " 7 "Reserved " 8 "cyclemodereplay " 9 "emergencymodereplay " 10 "photomodereplay " 11 "DASmodereplay " 12 "Reserved " 13 "Reserved " 14 "Reserved " 15 "invalid " ;
VAL_ 954 APA_AVMNotice 0 "IDLE " 1 "TopView " 2 "360Surroundview " 3 "Frontview " 4 "Rearview " 5 "LeftView " 6 "RightView " 7 "Reserved " ;
VAL_ 954 APA_ASPSwitchSts 0 "Inactive " 1 "Off " 2 "On " 3 "Reserved " ;
VAL_ 954 APA_CrossParkingModeSetSts 0 "Inactive " 1 "BackIn " 2 "HeadIn " 3 "Reserved " ;
VAL_ 954 APA_LAEBEnableSts 0 "Inactive " 1 "Off " 2 "On " 3 "Reserved " ;
VAL_ 954 APA_ASPRemindEnableSts 0 "Inactive " 1 "Off " 2 "On " 3 "Reserved " ;
VAL_ 954 APA_ObstacleSafeDistSetStatus 0 "invalid " 1 "30 " 2 "40 " 3 "50 " 4 "60 " 5 "70 " 6 "80 " 7 "Reserved " ;
VAL_ 954 APA_Uls_FKP_WarningSoundStatus 0 "inactive " 1 "On " 2 "Off " 3 "Reserved " ;
VAL_ 682 APA_right_slot_4_available_sts 0 "Inactive " 1 "Available " 2 "NotAvailable " 3 "Reserved " ;
VAL_ 682 APA_right_slot_3_available_sts 0 "Inactive " 1 "Available " 2 "NotAvailable " 3 "Reserved " ;
VAL_ 682 APA_right_slot_2_available_sts 0 "Inactive " 1 "Available " 2 "NotAvailable " 3 "Reserved " ;
VAL_ 682 APA_right_slot_1_available_sts 0 "Inactive " 1 "Available " 2 "NotAvailable " 3 "Reserved " ;
VAL_ 682 APA_left_slot_4_available_sts 0 "Inactive " 1 "Available " 2 "NotAvailable " 3 "Reserved " ;
VAL_ 682 APA_left_slot_3_available_sts 0 "Inactive " 1 "Available " 2 "NotAvailable " 3 "Reserved " ;
VAL_ 682 APA_left_slot_2_available_sts 0 "Inactive " 1 "Available " 2 "NotAvailable " 3 "Reserved " ;
VAL_ 682 APA_left_slot_1_available_sts 0 "Inactive " 1 "Available " 2 "NotAvailable " 3 "Reserved " ;
VAL_ 682 APA_right_slot_4_type 0 "unvailable " 1 "verticalslot " 2 "parallelslot " 3 "Fishboneslot " ;
VAL_ 682 APA_right_slot_3_type 0 "unvailable " 1 "verticalslot " 2 "parallelslot " 3 "Fishboneslot " ;
VAL_ 682 APA_left_slot_4_type 0 "unvailable " 1 "verticalslot " 2 "parallelslot " 3 "Fishboneslot " ;
VAL_ 682 APA_left_slot_3_type 0 "unvailable " 1 "verticalslot " 2 "parallelslot " 3 "Fishboneslot " ;
VAL_ 767 RRS_SwitchIndicatorError 0 "NoError " 1 "Error " ;
VAL_ 767 RRS_FrontRadarActiveStatus 0 "Invalid " 1 "Activated " 2 "Deactivated " 3 "Reserved " ;
VAL_ 767 RRS_SystemFailureFlag 0 "NotFailure " 1 "FrontFailure " 2 "RealFailure " 3 "SystemFailure " ;
VAL_ 767 RRS_ButtonPress 0 "PASbuttonidle " 1 "PASbuttonpressed " ;
VAL_ 767 RRS_SideZoneStatus_Rear 0 "None " 1 "Left " 2 "Right " 3 "LeftandRight " ;
VAL_ 767 RRS_MODE 0 "Off " 1 "Standby " 2 "FrontRearActive " 3 "FrontActive " 4 "RearActive " 5 "SystemFailure " 6 "Reserved " 7 "Invalidnotused " ;
VAL_ 767 RRS_SideZoneStatus_Front 0 "None " 1 "Left " 2 "Right " 3 "LeftandRight " ;
VAL_ 766 APA_right_fishboneslot_type 0 "Inactive " 1 "RigntForwardtype " 2 "RightReversetype " 3 "Reserved " ;
VAL_ 766 APA_left_fishboneslot_type 0 "Inactive " 1 "LeftForwardtype " 2 "LeftReversetype " 3 "Reserved " ;
VAL_ 766 APA_right_slot_2_type 0 "unvailable " 1 "verticalslot " 2 "parallelslot " 3 "Fishboneslot " ;
VAL_ 766 APA_right_slot_1_type 0 "unvailable " 1 "verticalslot " 2 "parallelslot " 3 "Fishboneslot " ;
VAL_ 766 APA_left_slot_2_type 0 "unvailable " 1 "verticalslot " 2 "parallelslot " 3 "Fishboneslot " ;
VAL_ 766 APA_left_slot_1_type 0 "unvailable " 1 "verticalslot " 2 "parallelslot " 3 "Fishboneslot " ;
VAL_ 620 APA_PrefillReq 0 "Notrequest " 1 "Request " ;
VAL_ 620 APA_DynamicSlotWarning 0 "Nowarning " 1 "Warning " ;
VAL_ 620 APA_TCUClutchCombinationReq 0 "NoRequest " 1 "Request " ;
VAL_ 620 APA_TrqHoldForTCUCl 0 "Off " 1 "On " ;
VAL_ 620 APA_AccPedShieldReq 0 "Unshield " 1 "Shield " ;
VAL_ 620 APA_ESPDecompressionModel 0 "Slowdecompression " 1 "fastdecompression " ;
VAL_ 620 APA_Activation_Status 0 "APAOff " 1 "APAStandby " 2 "APASearching " 3 "APAGuidanceActive " 4 "APACompleted " 5 "APAFailure " 6 "APATerminated " 7 "Reverse " ;
VAL_ 620 APA_TransPRNDShiftEnable 0 "NotEnable " 1 "Enable " ;
VAL_ 620 APA_LSCAction 0 "OFF " 1 "ON " ;
VAL_ 620 APA_HSAHDforbidden 0 "Notrequest " 1 "Request " ;
VAL_ 620 APA_EngineTrqReqEnable 0 "NotEnable " 1 "Enable " ;
VAL_ 620 APA_EPBrequest 0 "NoRequest " 1 "RequestBrake " 2 "RequestRelase " ;
VAL_ 620 APA_EPBrequestValid 0 "Invalid " 1 "Valid " ;
VAL_ 620 APA_TargetAccelerationValid 0 "notenable " 1 "enable " ;
VAL_ 620 APA_TransPRNDShiftReqValid 0 "Invalid " 1 "Valid " ;
VAL_ 621 APA_PrefillReq 0 "Notrequest " 1 "Request " ;
VAL_ 621 APA_DynamicSlotWarning 0 "Nowarning " 1 "Warning " ;
VAL_ 621 APA_TCUClutchCombinationReq 0 "NoRequest " 1 "Request " ;
VAL_ 621 APA_TrqHoldForTCUCl 0 "Off " 1 "On " ;
VAL_ 621 APA_AccPedShieldReq 0 "Unshield " 1 "Shield " ;
VAL_ 621 APA_ESPDecompressionModel 0 "Slowdecompression " 1 "fastdecompression " ;
VAL_ 621 APA_Activation_Status 0 "APAOff " 1 "APAStandby " 2 "APASearching " 3 "APAGuidanceActive " 4 "APACompleted " 5 "APAFailure " 6 "APATerminated " 7 "Reverse " ;
VAL_ 621 APA_TransPRNDShiftEnable 0 "NotEnable " 1 "Enable " ;
VAL_ 621 APA_LSCAction 0 "OFF " 1 "ON " ;
VAL_ 621 APA_HSAHDforbidden 0 "Notrequest " 1 "Request " ;
VAL_ 621 APA_EngineTrqReqEnable 0 "NotEnable " 1 "Enable " ;
VAL_ 621 APA_EPBrequest 0 "NoRequest " 1 "RequestBrake " 2 "RequestRelase " ;
VAL_ 621 APA_EPBrequestValid 0 "Invalid " 1 "Valid " ;
VAL_ 621 APA_TargetAccelerationValid 0 "notenable " 1 "enable " ;
VAL_ 621 APA_TransPRNDShiftReqValid 0 "Invalid " 1 "Valid " ;
VAL_ 724 APA_BCMHornCommand 0 "NoRequest " 1 "Request " 2 "Reserved " 3 "Invalid " ;
VAL_ 724 APA_vehicleFrontdetect 0 "NoDetect " 1 "Detect " 2 "Reserved " 3 "Invalid " ;
VAL_ 724 APA_ReleasePressureReq 0 "NoRequest " 1 "Request " ;
VAL_ 724 APA_PEPS_EngineOffLockRequest 0 "NotRequest " 1 "Request " ;
VAL_ 724 APA_PowerMirrorFoldReq 0 "NotRequest " 1 "Fold " 2 "Open " 3 "Reserved " ;
VAL_ 724 APA_ParkingModeAvailableSts 0 "idle " 1 "InteriorParkingMode " 2 "RemoteParkingMode " 3 "DoubleMode " ;
VAL_ 724 APA_RemoteParkingUsingRemind 0 "NoGetOffRequest " 1 "GetOffRequest " ;
VAL_ 724 APA_ASPAvailableStatus 0 "NotAvailable " 1 "Available " ;
VAL_ 724 APA_ASPStatus 0 "Off " 1 "On " 2 "Abort " 3 "Finish " 4 "Suspend " 5 "Failure " 6 "Reserved " 7 "Invalid " ;
VAL_ 724 APA_CrossModeSelectReq 0 "NoRequest " 1 "Request " ;
VAL_ 724 APA_LAEBStatus 0 "Off " 1 "Standby " 2 "Unavailable " 3 "Active " 4 "Brake " 5 "ReFault " 6 "Fault " 7 "Reserve " ;
VAL_ 724 APA_BLEConnectionRemind 0 "NoRequest " 1 "Request " ;
VAL_ 724 APA_LAEBReq 0 "NoRequest " 1 "Request " ;
VAL_ 725 APA_BCMHornCommand 0 "NoRequest " 1 "Request " 2 "Reserved " 3 "Invalid " ;
VAL_ 725 APA_vehicleFrontdetect 0 "NoDetect " 1 "Detect " 2 "Reserved " 3 "Invalid " ;
VAL_ 725 APA_ReleasePressureReq 0 "NoRequest " 1 "Request " ;
VAL_ 725 APA_PEPS_EngineOffLockRequest 0 "NotRequest " 1 "Request " ;
VAL_ 725 APA_PowerMirrorFoldReq 0 "NotRequest " 1 "Fold " 2 "Open " 3 "Reserved " ;
VAL_ 725 APA_ParkingModeAvailableSts 0 "idle " 1 "InteriorParkingMode " 2 "RemoteParkingMode " 3 "DoubleMode " ;
VAL_ 725 APA_RemoteParkingUsingRemind 0 "NoGetOffRequest " 1 "GetOffRequest " ;
VAL_ 725 APA_ASPAvailableStatus 0 "NotAvailable " 1 "Available " ;
VAL_ 725 APA_ASPStatus 0 "Off " 1 "On " 2 "Abort " 3 "Finish " 4 "Suspend " 5 "Failure " 6 "Reserved " 7 "Invalid " ;
VAL_ 725 APA_CrossModeSelectReq 0 "NoRequest " 1 "Request " ;
VAL_ 725 APA_LAEBStatus 0 "Off " 1 "Standby " 2 "Unavailable " 3 "Active " 4 "Brake " 5 "ReFault " 6 "Fault " 7 "Reserve " ;
VAL_ 725 APA_BLEConnectionRemind 0 "NoRequest " 1 "Request " ;
VAL_ 725 APA_LAEBReq 0 "NoRequest " 1 "Request " ;
VAL_ 612 APA_ParkNotice_4 0 "IDLE " 1 "'SearchSlot " 2 "Stopthecar " 3 "ParkingModeselection " 4 "Fastenseatbeltsfordriverparkin " 5 "Closethedoorparkin " 6 "NoStandstillBrakeparkin " 7 "PMOchoseELSautomode " 8 "BrakeandLongButton " 9 "ReleBraPark " 10 "Parkingin " 11 "ParkinsuspendACCpedalpressed " 12 "ParkinsuspendHandleGearshift " 13 "parkinsuspendDriverseatbeltunfastened " 14 "ParkinsuspendDooropen " 15 "ParkinsuspendEPBON " 16 "Parkinsuspendresume " 17 "Parkingsystemerror " 18 "SuccessfulParkin " 19 "PMOslottoobig " 20 "PMOslottoosmall " 21 "PMOsideselection " 22 "PMOsuspendHandleGearShift " 23 "Fastenseatbeltsparkout " 24 "Closethedoorparkout " 25 "PMOchoseELSautomode " 26 "FP4Ubuttonlongpressedandbrakingcheck " 27 "StartPMOReleaseBrake " 28 "Parkingout " 29 "PMOsuspendACCpadelpressed " 30 "PMOsuspendGearchange " 31 "PMOsuspenddriverseatbeltunfastened " 32 "PMOsuspenddooropen " 33 "PMOsuspendEPBON " 34 "Parkoutresume " 35 "Parkingcanceled " 36 "Parkoffspeedtoofast " 37 "successfulPMO " 38 "Speedtoohighpleaseslowdown " 39 "Slotsearchoffspeedtoohigh " 40 "RemoteParkingactive " 41 "forwardremoteparking " 42 "backwardremoteparking " 43 "remoteParkingfinish " 48 "SpeedtoohighParkingQuit " 49 "stop " 50 "GearR " 51 "GearD " 52 "Slopetoohighfunctioncancel " 53 "vehiclenotstandstill " 54 "GearnotP " 55 "EPBnotclamp " 56 "GuidenceWaitforsteeringcomplete " 57 "AbortHandondetect " 58 "Abortmaxnumberofmaneouvres " 59 "AbortGuidanceTimeout " 60 "AbortOtherreasons " 61 "CancleACCMode " 62 "ShiftGeartoD " ;
VAL_ 612 APA_ParkNotice 0 "IDLE " 1 "pPSCSearchR " 2 "pPSCSearchL " 3 "cPSCSearchR " 4 "cPSCSearchL " 5 "pPSCPSOKPosNOKR " 6 "pPSCPSOKPosNOKL " 7 "cPSCPSOKPosNOKR " 8 "cPSCPSOKPosNOKL " 9 "pPSCPSOKStopR " 10 "pPSCPSOKStopL " 11 "cPSCPSOKStopR " 12 "cPSCPSOKStopL " 13 "pPSCPSOKRGearR " 14 "pPSCPSOKRGearL " 15 "cPSCPSOKRGearR " 16 "cPSCPSOKRGearL " 17 "PSCPSOKReactive " 18 "ePSCPSOKRGearR " 19 "POCOKR " 20 "ePSCPSOKRGearL " 21 "POCTurnONIndicator " 22 "pPSCmovebwdR " 23 "pPSCmovebwdL " 24 "cPSCmovebwdR " 25 "cPSCmovebwdL " 26 "POCmovebwdR " 27 "POCmovebwdL " 28 "pPSCmovefwdR " 29 "pPSCmovefwdL " 30 "cPSCmovefwdR " 31 "cPSCmovefwdL " 32 "POCmovefwdR " 33 "POCmovefwdL " 34 "GuidanceInsertDGear " 35 "GuidanceInsertRGear " 36 "GuidanceStop " 37 "GuidenceWaitforsteeringcomplete " 38 "GuidenceSlowDown " 39 "Parkingmaneuvercompleted " 40 "reserved " 41 "AbortESPIntervention " 42 "AbortSpeedtoohigh " 43 "AbortHandondetect " 44 "Abortmaxnumberofmaneouvresreached " 45 "AbortTrailorattached " 46 "AbortUserdeactivated " 47 "FailureSensorsBlinded " 48 "APAinternalFailure " 49 "APAexternalFailure " 50 "SearchingSlowDown " 51 "AbortGuidanceTimeout " 52 "AbortOffTrack " 53 "AbortPStoosmall " 54 "AbortOtherreasons " 55 "POCNofrontobstacle " 56 "SearchingforPakingSlotRightEchelon " 57 "SearchingforPakingSlotLeftEchelon " 58 "ParkingSpaceFoundRightEchelon " 59 "ParkingSpaceFoundLeftEchelon " ;
VAL_ 612 APA_RemoteOnOff 0 "OFF " 1 "On " 2 "Notused " 3 "Invalid " ;
VAL_ 612 APA_ButtonPress 0 "PSCbuttonidle " 1 "PSCbuttonpressed " ;
VAL_ 612 APA_IncreasePressureReq 0 "Notrequest " 1 "Request " ;
VAL_ 612 APA_TurnLightsCommand 0 "NoRequest " 1 "LeftLightOn " 2 "RightLightOn " 3 "DoubleLightsOn " ;
VAL_ 612 APA_SteeringAngleReqProtection 0 "NoRequest " 1 "RequestEPScontrol " 2 "EPScontrolactive " ;
VAL_ 612 APA_ErrorStatus 0 "NoError " 1 "Error " ;
VAL_ 612 APA_indication 0 "Nofunctionisactive " 1 "pPSCisactive " 2 "cPSCisactive " 3 "POCisactive " 4 "ePSCisactive " 5 "Invalid " ;
VAL_ 612 APA_APAOnOff 0 "OFF " 1 "ON " ;
VAL_ 612 APA_EmergenceBrake 0 "Notrequest " 1 "Request " ;
VAL_ 968 ADS_RoadSlopeFlag 0 "无效 " 1 "有效 " ;
VAL_ 968 ADS_RoadMergeFlag 0 "无效 " 1 "有效 " ;
VAL_ 968 ACC_TakeoverReqAtIPFail 0 "norequest " 1 "level1request " 2 "level2request " 3 "reserved " ;
VAL_ 781 ACC_DoorCtrlReq 0 "norequest " 1 "lock " 2 "unlock " 3 "reserved " ;
VAL_ 781 ACC_EmergencyLightingRequest 0 "norequest " 1 "Level1 " 2 "Level2 " 3 "OFF " ;
VAL_ 781 ACC_TargetBasedLateralControl 0 "nolateralcontrol " 1 "aroundBased " 2 "lanebased " 3 "targetbased " ;
VAL_ 781 ACC_IACCHWATextInfoForDriver 0 "nodisplay " 1 "IACCCancel " 2 "IACCdeactivate " 3 "IACCunintendedexit " 4 "unabletoactivateIACC " 5 "laneconditionnotavailable " 6 "reserved " 7 "longitudinalcontrolnotavailable " 8 "IACCnotavailablebyEPS " 9 "exceedspeedlimit " 10 "driveroverridessteering " 11 "cautionaboutdrivingsafty " 12 "systemerror " 13 "prohibitionrequest " 14 "turnlightswitchon " 15 "Handsonplz " 16 "PleaseturnonIACCinincall " 17 "unabletoactiveincurve " 18 "unabletoactivefornotinlane/crossinglane " 19 "LongitudeExit " 20 "takeoverrequestwithsafetystoping " 21 "takeoverrequestwithsafetystopcompleted " 22 "othersystemerror " 27 "DriverDrowsyorDistracted " ;
VAL_ 781 ACC_LatTakeoverReq 0 "norequest " 1 "level1request " 2 "level2request " 3 "reserved " ;
VAL_ 781 ACC_IACCHWAMode 0 "off " 1 "standby " 2 "passive " 3 "active " 4 "suspend " 5 "prohibition " 6 "reserved " 7 "failure " ;
VAL_ 871 ACC_ELKEnableStatus 0 "off " 1 "on " ;
VAL_ 871 ACC_ELKInterventionMode 0 "off " 1 "Roadedge " 2 "Overtaking " 3 "Oncoming " ;
VAL_ 778 ACC_LaneChangeStatus 0 "未变道 " 1 "变道进行中 " 2 "变道结束 " 3 "Unknow " ;
VAL_ 778 ACC_LLaneMarkerType 0 "Dashed " 1 "solid " 2 "roadedge " 3 "doublelanemark " 4 "Botts'dots " 5 "other " 6 "fence " 7 "nodisplay " ;
VAL_ 778 ACC_LDWShakeLevStatus 0 "reserved " 1 "low " 2 "normal " 3 "high " ;
VAL_ 778 ACC_IACCHWAEnable 0 "OFF " 1 "ON " ;
VAL_ 778 ACC_RLaneMarkerType 0 "Dashed " 1 "solid " 2 "roadedge " 3 "doublelanemark " 4 "Botts'dots " 5 "other " 6 "fence " 7 "nodisplay " ;
VAL_ 877 ACC_FRadarFailureStatus 0 "nofailure " 1 "blind " 2 "reversiblefailure " 3 "irrversiblefailure " ;
VAL_ 877 ACC_AEBTargetmode 0 "none " 1 "videoonlymode " 2 "raderonlymode " 3 "fusionmode " ;
VAL_ 877 ACC_AEBStatus 0 "off " 1 "on " 2 "reserved " 3 "failure " ;
VAL_ 998 ACC_LaneEquationStatus 0 "nodisplay " 1 "LeftLane " 2 "RightLane " 3 "reserved " ;
VAL_ 996 ACC_AEBTargetDetection 0 "nodetected " 1 "detected " ;
VAL_ 863 ACC_CSLSetReq 0 "norequest " 1 "request " ;
VAL_ 863 ACC_CSLAEnableStatus 0 "OFF " 1 "ON " ;
VAL_ 862 ACC_SaftyBelt_Tightened 0 "level0 " 1 "level1 " 2 "level2 " 3 "Reserved " ;
VAL_ 862 ACC_SaftyBeltVibrationReq 0 "NoRequest " 1 "Request " ;
VAL_ 862 ACC_AEBEnable 0 "off " 1 "on " ;
VAL_ 862 ACC_ACCEPBrequest 0 "norequest " 1 "request " ;
VAL_ 862 ACC_LngTakeOverReq 0 "norequest " 1 "level1request " 2 "level2request " 3 "reserved " ;
VAL_ 862 ACC_ObjValid 0 "noobject " 1 "targetobjectdetected " ;
VAL_ 802 ACC_FRadarCalibrationStatus 0 "Calibrationisok " 1 "CalibrationInProcess " 2 "Calibrationneverdone " 3 "CalibrationFailed " ;
VAL_ 802 ACC_DistanceAlertLevel 0 "nodisplay " 1 "Level1 " 2 "Level2 " 3 "Level3 " 4 "reverved " 5 "reverved " 6 "reverved " 7 "reverved " ;
VAL_ 606 ACC_AccTrqReqActive 0 "notActive " 1 "Active " ;
VAL_ 606 ACC_AEBVehilceHoldReq 0 "Nohold " 1 "hold " ;
VAL_ 606 ACC_FCWPreWarning 0 "nowarning " 1 "warning " ;
VAL_ 606 ACC_FCWLatentWarning 0 "nowarning " 1 "warning " ;
VAL_ 606 ACC_FCWActive 0 "notActive " 1 "Active " ;
VAL_ 606 ACC_PrefillActive 0 "notActive " 1 "Active " ;
VAL_ 606 ACC_AWBActive 0 "notActive " 1 "Active " ;
VAL_ 606 ACC_ABAActive 0 "notActive " 1 "Active " ;
VAL_ 606 ACC_ABAlevel 0 "level0 " 1 "level1 " 2 "level2 " 3 "level3 " ;
VAL_ 606 ACC_AEBActive 0 "notActive " 1 "Active " ;
VAL_ 590 ACC_ACCMode 0 "OFFmode " 1 "Passivemode " 2 "StandBymode " 3 "ActiveControlmode " 4 "BrakeOnlymode " 5 "Override " 6 "StandWaitmode " 7 "Failuremode " ;
VAL_ 590 ACC_Driveoff_Request 0 "Norequest " 1 "request " ;
VAL_ 590 ACC_EngineStartStopRequest 0 "Norequest " 1 "EngineAutoStopRequest " 2 "EngineAutoStartRequest " 3 "reserved " ;
VAL_ 590 ACC_LimitSwitchArbitration 0 "invalid " 1 "Off " 2 "On " 3 "reserved " ;
VAL_ 590 ACC_CDDActive 0 "notactive " 1 "Active " ;
VAL_ 590 ACC_CCMode 0 "OFFmode " 1 "Passivemode " 2 "StandBymode " 3 "ActiveControlmode " 4 "Override " 5 "Reserved " 6 "Reserved " 7 "Failuremode " ;
VAL_ 590 ACC_TCUCreepProhibition 0 "norequest " 1 "request " ;
VAL_ 590 ACC_DecToStop 0 "nodemand " 1 "demand " ;
VAL_ 590 ACC_EmergencyDataRrdReq 0 "norequest " 1 "Event1Request " 2 "Event2Request " 3 "ImageRecord " ;
VAL_ 590 ACC_LDWStatus 0 "Off " 1 "Standby " 2 "Active " 3 "Failure " ;
VAL_ 590 ACC_LDWVibrationWarningReq 0 "NoWarning不报警 " 1 "LeftWarning左报警 " 2 "RightWarning右报警 " 3 "reserved " ;
VAL_ 448 ACC_LatAngReqActive 0 "notActive " 1 "Active " ;
VAL_ 818 LAS_TSRRightLaneStatus 0 "off " 1 "fusionmode " 2 "visiononlymode " 3 "navigationonlymode " 4 "reserved " 5 "reserved " 6 "reserved " 7 "Invalid " ;
VAL_ 818 LAS_TSRLeftLaneStatus 0 "off " 1 "fusionmode " 2 "visiononlymode " 3 "navigationonlymode " 4 "reserved " 5 "reserved " 6 "reserved " 7 "Invalid " ;
VAL_ 818 LAS_TSRHostSpdLimitUnits 0 "nodisplay " 1 "unitkph " 2 "unitmph " 3 "reserved " ;
VAL_ 818 LAS_HMAStatus 0 "Off " 1 "Standby " 2 "Active " 3 "Failure " ;
VAL_ 818 LAS_TSRStatus 0 "off " 1 "fusionmode " 2 "visiononlymode " 3 "navigationonlymode " 4 "reserved " 5 "reserved " 6 "reserved " 7 "Invalid " ;
VAL_ 818 LAS_OverspeedSoundWarningEnSt 0 "Off " 1 "On " ;
VAL_ 818 LAS_TSREnable 0 "off " 1 "on " ;
VAL_ 818 LAS_FrontCameraFailureStatus 0 "NoError " 1 "camerablocked " 2 "temporaryfailure " 3 "permanentfailure " ;
VAL_ 818 LAS_FrontCameraCalibrationStatus 0 "Calibrationisok " 1 "CalibrationInProcess " 2 "Calibrationneverdone " 3 "CalibrationFailed " ;
VAL_ 818 LAS_HMAEnableStatus 0 "off " 1 "on " ;
VAL_ 818 LAS_HMALightDistribution 0 "Highbeamnotrecommended " 1 "Highbeamrecommended " ;
VAL_ 818 LAS_OverspeedWarningEnableStatus 0 "OFF " 1 "ON " ;
VAL_ 818 LAS_OverspeedSoundWarning 0 "NoWarning " 1 "Warning " ;
VAL_ 818 LAS_OverspeedVisualWarning 0 "NoWarning " 1 "Warning " ;
VAL_ 893 LAS_TLAObjectStatus_LeftLane 0 "nodisplay " 1 "Lighting " 2 "Flashing " 3 "Disappear " ;
VAL_ 893 LAS_TLAObjectStatus_RightLane 0 "nodisplay " 1 "Lighting " 2 "Flashing " 3 "Disappear " ;
VAL_ 893 LAS_TLAArrowDirection_RightLane 0 "nodisplay " 1 "Forward " 2 "Left " 3 "ForwardLeft " 4 "Right " 5 "ForwardRight " 6 "RightLeft " 7 "LeftForwardRight " ;
VAL_ 893 LAS_TLAObjectColour_RightLane 0 "nodisplay " 1 "Red " 2 "Yellow " 3 "Green " ;
VAL_ 893 LAS_TLAObjectDetection_RightLane 0 "NotDetected " 1 "Detected " ;
VAL_ 893 LAS_TLAArrowDirection_LeftLane 0 "nodisplay " 1 "Forward " 2 "Left " 3 "ForwardLeft " 4 "Right " 5 "ForwardRight " 6 "RightLeft " 7 "LeftForwardRight " ;
VAL_ 893 LAS_TLAObjectColour_LeftLane 0 "nodisplay " 1 "Red " 2 "Yellow " 3 "Green " ;
VAL_ 893 LAS_TLAObjectDetection_LeftLane 0 "NotDetected " 1 "Detected " ;
VAL_ 893 LAS_TLAArrowDirection_HostLane 0 "nodisplay " 1 "Forward " 2 "Left " 3 "ForwardLeft " 4 "Right " 5 "ForwardRight " 6 "RightLeft " 7 "LeftForwardRight " ;
VAL_ 893 LAS_TLAObjectDetection_HostLane 0 "NotDetected " 1 "Detected " ;
VAL_ 893 LAS_TLAObjectColour_HostLane 0 "nodisplay " 1 "Red " 2 "Yellow " 3 "Green " ;
VAL_ 893 LAS_TLAWarninglevel 0 "nowarning " 1 "warninglevel1 " 2 "warninglevel2 " 3 "warninglevel3 " ;
VAL_ 893 LAS_TLAStatus 0 "OFF " 1 "Standby " 2 "Active " 3 "Failure " ;
VAL_ 893 LAS_TLAEnable 0 "OFF " 1 "ON " ;
VAL_ 893 LAS_TLAObjectStatus_HostLane 0 "nodisplay " 1 "Lighting " 2 "Flashing " 3 "Disappear " ;
VAL_ 856 ADS_UDLCTextInfoForDriver 0 "nodisplay " 1 "UDLCexit触发式换道已退出（UDLC不再等待换道并且不再主导控制） " 2 "UDLCreturn触发式换道已退出并回退原车道（驾驶员取消转向灯回退或系统回退开始时） " 3 "UDLCfinished请拨回转向灯（换道完成或回退对中完成时） " 4 "Lanechangerequestbymerge " 5 "changelanetobothsidesforthetrafficjam两边车道均可支持变道 " 6 "Lanechangerequestbyramp " 7 "changelanetoleftsideforthetrafficjam左边车道可支持变道 " 8 "changelanetorightsideforthetrafficjam右边车道可支持变道 " 9 "outofODD暂时不满足换道条件不尝试换道 " 10 "PleaseturnontheUDLCinHU请在主机中打开主动换道设置开关 " 14 "waitovertime换道尝试超时中止 " 15 "reserved " ;
VAL_ 856 ADS_LightFlashRequest 0 "NoRequest " 1 "Request " ;
VAL_ 856 ADS_HighBeamLampOnRequest 0 "NoRequest " 1 "LightOn " 2 "LightOff " 3 "Reserved " ;
VAL_ 856 ADS_LightingReq 0 "Off " 1 "On " ;
VAL_ 856 ADS_AutoHeadlightshift_Req 0 "Off " 1 "On " ;
VAL_ 856 ADS_UDLCTurnLeftRequest 0 "norequest " 1 "request " ;
VAL_ 856 ADS_AutoWiperShift_Rqe 0 "Off " 1 "On " ;
VAL_ 856 ADS_UDLCTurnRightRequest 0 "norequest " 1 "request " ;
VAL_ 856 ADS_ESSEnable 0 "OFF " 1 "ON " ;
VAL_ 856 ACC_HornCommand 0 "NoRequest " 1 "LongHonk " 2 "IntervalHonk " 3 "Reserved " ;
VAL_ 856 ADS_LightFrequencyRequest 0 "Off " 1 "Level1 " 2 "Level2 " 3 "Level3 " 4 "Level4 " 5 "Level5 " 6 "Level6 " 7 "Level7 " ;
VAL_ 856 ADS_LightBrightRequest 0 "Off " 1 "Level1 " 2 "Level2 " 3 "Level3 " 4 "Level4 " 5 "Level5 " 6 "Level6 " 7 "Invalid " ;
VAL_ 856 ADS_UDLCEnableStatus 0 "OFF " 1 "ON " ;
VAL_ 856 ADS_LowBeamLampOnRequest 0 "NoRequest " 1 "LightOn " 2 "LightOff " 3 "Reserved " ;
VAL_ 834 ADS_rescueReq 0 "NoRequest " 1 "Request " ;
VAL_ 834 ADS_SafeStopSts 0 "off " 1 "Active " 2 "completed " 3 "reserved " ;
VAL_ 834 ADS_EyesOffWarningInhi 0 "norequest " 1 "Request " ;
VAL_ 1534 GW_FBLPowerHold 0 "刷写档位保持请求信号无效 " 1 "刷写档位保持请求信号有效 " 2 "Reserved " 3 "Invalid " ;
VAL_ 1534 GW_FBLPowerReq 0 "刷写档位请求无效 " 1 "刷写档位请求有效 " 2 "Reserved " 3 "Reserved " 4 "Reserved " 5 "Reserved " 6 "Reserved " 7 "Invalid " ;
VAL_ 950 ATB_WarningDisp 0 "无提示 " 1 "不能切换驾驶模式 " 2 "reserved " 3 "invalid " ;
VAL_ 584 AWD_EstimatedTorque 65535 "Fault " ;
VAL_ 584 AWD_EngineLimitingRequest 4095 "Fault " ;
VAL_ 584 AWD_ATSReqRefuse 0 "false " 1 "true " ;
VAL_ 584 AWD_ClutchCircuitFaultStatus 0 "NormalOperation " 1 "ClutchCircuitShortedtoBattery " 2 "ClutchCircuitShortedtoGround " 3 "ClutchCircuitOpen " ;
VAL_ 584 AWD_EngineLimitingEnable 0 "Disable " 1 "Enable " ;
VAL_ 846 AWD_Lamp4WDAuto 0 "LampOff " 1 "BlinkLamp " 2 "LampOn " 3 "Unused " ;
VAL_ 846 AWD_LampDiag 0 "LampOff " 1 "BlinkLamp " 2 "LampOn " 3 "Unused " ;
VAL_ 846 AWD_Lamp2WD 0 "LampOff " 1 "BlinkLamp " 2 "LampOn " 3 "Unused " ;
VAL_ 846 AWD_CouplingFaultStatus 0 "NormalOperatingMode " 1 "Reducedcouplingfunctionality " 2 "Temporarycouplingfailure " 3 "Permanentcouplingfailure " ;
VAL_ 846 AWD_CouplingThermalFailsafe 0 "FalseCouplingThermaisnotbeingFailsafe " 1 "TrueCouplingThermaisbeingFailsafe " ;
VAL_ 846 AWD_ExternalRequestsIgnored 0 "FalseExternalRequestsbeingaccepted " 1 "TrueExternalRequestsnotbeingaccepted " ;
VAL_ 846 AWD_ModeChangeInProgress 0 "NoModeChange " 1 "ModeChange " ;
VAL_ 80 SRS_RightRearBuckleSwitchSts 0 "Buckled " 1 "Unbuckle " 2 "NotUsed " 3 "NotUsed " ;
VAL_ 80 SRS_FrontPsgOccupancy 0 "notoccupied " 1 "occupied " ;
VAL_ 80 SRS_MiddleRearBuckleSwitchSts 0 "Buckled " 1 "Unbuckle " 2 "NotUsed " 3 "NotUsed " ;
VAL_ 80 SRS_PADIndication 0 "PABonandLampoff " 1 "PABoffandLampon " ;
VAL_ 80 SRS_WarningLampStatus 0 "Lampoff " 1 "Lampon " 2 "LampFlashing " 3 "NotUsed " ;
VAL_ 80 SRS_LeftRearBuckleSwitchSts 0 "Buckled " 1 "Unbuckle " 2 "NotUsed " 3 "NotUsed " ;
VAL_ 80 SRS_PassengerBuckleSwitchStatus 0 "Buckled " 1 "Unbuckle " 2 "NotUsed " 3 "NotUsed " ;
VAL_ 80 SRS_DriverBuckleSwitchStatus 0 "Buckled " 1 "Unbuckle " 2 "NotUsed " 3 "NotUsed " ;
VAL_ 1288 ESP_WheelSpdSensorEcuError 0 "Noerror " 1 "error " ;
VAL_ 1288 ESP_WheelSpdSensorError 0 "Noerror " 1 "error " ;
VAL_ 1288 ESP_RRWheelSpdSensorSigFailure 0 "Noerror " 1 "error " ;
VAL_ 1288 ESP_RRWheelSpdSensor_Open 0 "Noerror " 1 "error " ;
VAL_ 1288 ESP_RRWheelSpdSensor_ShtBAT 0 "Noerror " 1 "error " ;
VAL_ 1288 ESP_RRWheelSpdSensor_GND 0 "Noerror " 1 "error " ;
VAL_ 1288 ESP_RRWheelSpdSensorFailure 0 "Noerror " 1 "error " ;
VAL_ 1288 ESP_RLWheelSpdSensorSigFailure 0 "Noerror " 1 "error " ;
VAL_ 1288 ESP_RLWheelSpdSensor_Open 0 "Noerror " 1 "error " ;
VAL_ 1288 ESP_RLWheelSpdSensor_ShtBAT 0 "Noerror " 1 "error " ;
VAL_ 1288 ESP_RLWheelSpdSensor_GND 0 "Noerror " 1 "error " ;
VAL_ 1288 ESP_RLWheelSpdSensorFailure 0 "Noerror " 1 "error " ;
VAL_ 1288 ESP_FRWheelSpdSensorSigFailure 0 "Noerror " 1 "error " ;
VAL_ 1288 ESP_FRWheelSpdSensor_Open 0 "Noerror " 1 "error " ;
VAL_ 1288 ESP_FRWheelSpdSensor_ShtBAT 0 "Noerror " 1 "error " ;
VAL_ 1288 ESP_FRWheelSpdSensor_GND 0 "Noerror " 1 "error " ;
VAL_ 1288 ESP_FRWheelSpdSensorFailure 0 "Noerror " 1 "error " ;
VAL_ 1288 ESP_FLWheelSpdSensorSigFailure 0 "Noerror " 1 "error " ;
VAL_ 1288 ESP_FLWheelSpdSensor_Open 0 "Noerror " 1 "error " ;
VAL_ 1288 ESP_FLWheelSpdSensor_ShtBAT 0 "Noerror " 1 "error " ;
VAL_ 1288 ESP_FLWheelSpdSensor_GND 0 "Noerror " 1 "error " ;
VAL_ 1288 ESP_FLWheelSpdSensorFailure 0 "Noerror " 1 "error " ;
VAL_ 1018 ESP_TPMS_WarningStatus 0 "NoTirePressureWarning " 1 "TirePressureWarning " ;
VAL_ 1018 ESP_TPMS_MalfunctionStatus 0 "TPMSWorkOK " 1 "TPMSMalFunction " ;
VAL_ 1018 ESP_RearRghtWheelStatus 0 "Normal " 1 "SingleWheelWarning " 2 "GeneralWarning " 3 "invalid " ;
VAL_ 1018 ESP_RearLeftWheelStatus 0 "Normal " 1 "SingleWheelWarning " 2 "GeneralWarning " 3 "invalid " ;
VAL_ 1018 ESP_FrontRightWheelStatus 0 "Normal " 1 "SingleWheelWarning " 2 "GeneralWarning " 3 "invalid " ;
VAL_ 1018 ESP_FrontLeftWheelStatus 0 "Normal " 1 "SingleWheelWarning " 2 "GeneralWarning " 3 "invalid " ;
VAL_ 847 ESP_VGH_Available 0 "Available " 1 "NotAvailable " ;
VAL_ 847 ESP_VGH_Status 0 "Standby " 1 "Inactive " 2 "Failure " 3 "Close " ;
VAL_ 847 AUTOHOLD_TextDisplay 0 "Notextmessage " 1 "EMSEngineSpeed≤180RPM " 6 "坡度过大AVH功能失效 " 7 "Invalid " ;
VAL_ 847 ESP_AVHStatusSet 0 "invalid " 1 "off " 2 "on " ;
VAL_ 847 ESP_ATS_PtrotectMode 0 "false " 1 "True " ;
VAL_ 847 ESP_ATS_ATB_Failure 0 "false " 1 "True " ;
VAL_ 847 ESP_ATS_EPBi_Failure 0 "false " 1 "True " ;
VAL_ 847 ESP_ATS_AWD_Failure 0 "false " 1 "True " ;
VAL_ 847 ESP_ATS_TCU_Failure 0 "false " 1 "True " ;
VAL_ 847 ESP_ATS_EMS_Failure 0 "false " 1 "True " ;
VAL_ 847 ESP_ATSReqRefuse 0 "false " 1 "true " ;
VAL_ 847 EPB_TextDisplay 0 "Notextmessage " 1 "Gradienttoohigh " 2 "Clampforcenotenough " 3 "Fastenseatbelt " 4 "Openparkbrakebyswitch " 5 "Pressbrakepedal " 6 "reserved " 7 "reserved " 8 "reserved " 9 "reserved " 10 "reserved " 11 "reserved " 12 "reserved " 13 "reserved " 14 "reserved " 15 "Invalid " ;
VAL_ 847 EPB_AcousticWarning 0 "OFF " 1 "ON " ;
VAL_ 847 EPB_FunctionLamp 0 "LampOFF " 1 "LampON " 2 "flash " 3 "Invalid " ;
VAL_ 847 EPB_FailureLamp 0 "LampOFF " 1 "LampON " 2 "flash " 3 "Invalid " ;
VAL_ 632 ESP_YawRateValid 0 "Valid " 1 "Invalid " ;
VAL_ 632 ABS_TODFastOpenRequest 0 "Passive " 1 "OpenClutch " 2 "Torquemaxlimit " 3 "Error " ;
VAL_ 631 ESP_HBBFunctionStatus 0 "HBBStandby " 1 "HBBVacuumBoostFailure " 2 "HBBFailure " 3 "Disable " ;
VAL_ 631 ESP_CDP_ParkingAvailForACC 0 "Available " 1 "notavailable " ;
VAL_ 631 ESP_CDP_ParkingActiveForACC 0 "Active " 1 "notActive " ;
VAL_ 631 ESP_RWU_ParkingAvailForACC 0 "Available " 1 "notavailable " ;
VAL_ 631 ESP_RWU_ParkingActiveForACC 0 "Active " 1 "notActive " ;
VAL_ 631 ESP_HBBActiveStatus 0 "NotActive " 1 "Active " ;
VAL_ 631 ESP_HDC_STATUS 0 "OFF " 1 "ON " 2 "Standby " 3 "Error " ;
VAL_ 631 ESP_IncreasePressureReqOK 0 "NotOK " 1 "OK " ;
VAL_ 631 ESP_CDD_Available_APA 1 "available " 0 "notavailable " ;
VAL_ 631 ESP_CDD_Active_APA 1 "active " 0 "notactive " ;
VAL_ 631 ESP_QDCACC 0 "noerror " 1 "error " 2 "reserved " 3 "reserved " ;
VAL_ 631 ESP_OnlyABSActive 0 "NotActive " 1 "Active " ;
VAL_ 631 ESP_TCSActive 0 "NotActive " 1 "Active " ;
VAL_ 631 ESP_VDCActive 0 "NotActive " 1 "Active " ;
VAL_ 631 ESP_VehicleStandstill 0 "notstandstill " 1 "standstill " ;
VAL_ 631 ESP_CDD_Available 0 "notavailable " 1 "available " ;
VAL_ 631 ESP_CDD_Active 0 "notactive " 1 "active " ;
VAL_ 631 ESP_BrakeOverHeatBrakeDiscTemp 0 "nothigh " 1 "temptoohigh " ;
VAL_ 631 ESP_AWBavailable 0 "notavailable " 1 "available " ;
VAL_ 631 ESP_AWBactive 0 "notactive " 1 "active " ;
VAL_ 631 ESP_AEBdecActive 0 "notactive " 1 "active " ;
VAL_ 631 ESP_AEBAvailable 0 "notavailable " 1 "available " ;
VAL_ 631 ESP_PrefillAvailable 0 "notavailable " 1 "available " ;
VAL_ 631 ESP_PrefillActive 0 "notactive " 1 "active " ;
VAL_ 631 ESP_ABAavailable 0 "notavailable " 1 "available " ;
VAL_ 631 ESP_ABAactive 0 "notactive " 1 "active " ;
VAL_ 631 ESP_BrakeForce 0 "nobrakeforce " 1 "havebrakeforce " ;
VAL_ 600 ESP_HHC_Active 0 "functionisnotinactive " 1 "functionisinactive " ;
VAL_ 600 ESP_HHC_Available 0 "Available " 1 "NotAvailable " ;
VAL_ 600 ESP_AutoHoldAvailable 0 "Valid " 1 "Invalid " ;
VAL_ 600 ESP_AutoHoldActive 0 "NotActive " 1 "Active " ;
VAL_ 600 ESP_BrakeLightOnRequest 0 "brakelightOFF " 1 "brakelightON " 2 "notused " 3 "signalnotavailable " ;
VAL_ 600 ESP_AutoHoldStandby 0 "NotActive " 1 "Active " ;
VAL_ 600 ESP_MasCylBrakePressureValid 0 "Valid " 1 "Invalid " ;
VAL_ 520 ESP_ECDAvailable 0 "Valid " 1 "Invalid " ;
VAL_ 520 ESP_ECDActive 0 "NotActive " 1 "Active " ;
VAL_ 520 ESP_UrgencyBrakeAlarm 0 "NotActive " 1 "Active " ;
VAL_ 520 Wheel_Speed_RL_Direction 0 "Forward " 1 "backward " 2 "Standstill " 3 "Invalid " ;
VAL_ 520 Wheel_Speed_RL_Valid_Data 0 "Valid " 1 "NotValid " ;
VAL_ 520 Wheel_Speed_RR_Direction 0 "Forward " 1 "backward " 2 "Standstill " 3 "Invalid " ;
VAL_ 520 Wheel_Speed_RR_Valid_Data 0 "Valid " 1 "NotValid " ;
VAL_ 518 Wheel_Speed_FL_Direction 0 "Forward " 1 "backward " 2 "Standstill " 3 "Invalid " ;
VAL_ 518 Wheel_Speed_FL_Valid_Data 0 "Valid " 1 "NotValid " ;
VAL_ 518 Wheel_Speed_FR_Direction 0 "Forward " 1 "backward " 2 "Standstill " 3 "Invalid " ;
VAL_ 518 Wheel_Speed_FR_Valid_Data 0 "Valid " 1 "NotValid " ;
